VERSION ""

NS_ :

BS_:

BU_: ABS_BASE ATCM_DMSM GENERIC_GWMWakeup PBM IPMB TCU_TBS FDSM GSM TRCM GWM _delete ABS_ESC HUD IPMA CCM SASM PSCM SCCM HCM ATCM SUMA_RLM ATCM_FFSM PCU SECM VDM TBM OCS GENERIC TCCM TSTR RCM

BO_ 947 BodyInfo_3_HS2: 8 GWM
 SG_ ValetMode_D_Mem : 16|1@0+ (1,0) [0|1] "SED"  GENERIC
 SG_ DimmingLvlEvnt_No_Actl : 18|2@0+ (1,0) [0|3] "unitless"  GENERIC
 SG_ DrStatDrvErrCnt_B_Stat : 19|1@0+ (1,0) [0|1] "SED"  GENERIC
 SG_ Backlit_LED_Status : 23|4@0+ (1,0) [0|15] "SED"  ATCM_DMSM,ATCM_FFSM,ATCM,TBM,GSM
 SG_ TurnLghtRight_D_Rq : 63|2@0+ (1,0) [0|3] "SED"  IPMA,HCM,SCCM
 SG_ TurnLghtRightOn_B_Stat : 35|1@0+ (1,0) [0|1] "SED"  GENERIC
 SG_ TurnLghtLeftOn_B_Stat : 54|1@0+ (1,0) [0|1] "SED"  GENERIC
 SG_ FogLghtRearOn_B_Stat : 1|1@0+ (1,0) [0|1] "SED"  HCM,IPMA,GENERIC
 SG_ FogLghtFrontOn_B_Stat : 56|1@0+ (1,0) [0|1] "SED"  HCM,IPMA
 SG_ TurnLghtLeft_D_Rq : 9|2@0+ (1,0) [0|3] "SED"  IPMA,HCM,SCCM
 SG_ IgnKeyType_D_Actl : 39|4@0+ (1,0) [0|15] "SED"  ABS_BASE,ABS_ESC,CCM,IPMA
 SG_ Parklamp_Status : 3|2@0+ (1,0) [0|3] "SED"  HCM,ATCM_FFSM,ATCM_DMSM
 SG_ Litval : 47|8@0+ (1,0) [0|253] "SED"  IPMA,TBM,CCM,HCM,GSM
 SG_ Key_In_Ignition_Stat : 11|1@0+ (1,0) [0|1] "SED"  ABS_BASE,ABS_ESC,GSM,TRCM
 SG_ Ignition_Status : 7|4@0+ (1,0) [0|15] "SED"  ABS_BASE,PBM,HCM,ATCM_DMSM,TCU_TBS,ATCM,FDSM,OCS,TBM,TCCM,VDM,TRCM,SCCM,PSCM,GSM,RCM,HUD,ATCM_FFSM,IPMA,CCM,ABS_ESC
 SG_ Dimming_Lvl : 31|8@0+ (1,0) [0|253] "SED"  ATCM,ATCM_DMSM,ATCM_FFSM,GSM,TBM
 SG_ Day_Night_Status : 15|2@0+ (1,0) [0|3] "SED"  HUD,IPMA,ATCM_DMSM,TBM,CCM,ATCM_FFSM,RCM
 SG_ Remote_Start_Status : 13|2@0+ (1,0) [0|3] "SED"  TRCM,RCM,GENERIC,IPMB
 SG_ DrStatTgate_B_Actl : 0|1@0+ (1,0) [0|1] "SED"  SUMA_RLM,ABS_BASE,VDM,ABS_ESC,IPMB,TCU_TBS,OCS
 SG_ DrStatRr_B_Actl : 49|1@0+ (1,0) [0|1] "SED"  SUMA_RLM,ABS_BASE,VDM,IPMB,ABS_ESC,TCU_TBS,OCS
 SG_ DrStatRl_B_Actl : 48|1@0+ (1,0) [0|1] "SED"  SUMA_RLM,ABS_BASE,VDM,IPMB,ABS_ESC,TCU_TBS,OCS
 SG_ DrStatPsngr_B_Actl : 60|1@0+ (1,0) [0|1] "SED"  SUMA_RLM,ATCM_FFSM,ATCM_DMSM,ABS_BASE,VDM,IPMB,ABS_ESC,TCU_TBS,OCS
 SG_ DrStatInnrTgate_B_Actl : 58|1@0+ (1,0) [0|1] "SED"  VDM,ABS_BASE,ABS_ESC,IPMB,TCU_TBS,SCCM,OCS
 SG_ DrStatHood_B_Actl : 59|1@0+ (1,0) [0|1] "SED"  ABS_BASE,ABS_ESC,TCU_TBS,OCS
 SG_ DrStatDrv_B_Actl : 61|1@0+ (1,0) [0|1] "SED"  SUMA_RLM,ATCM_FFSM,ATCM_DMSM,ABS_BASE,IPMB,PBM,TCU_TBS,SASM,VDM,TCCM,GSM,IPMA,OCS,ABS_ESC,CCM
 SG_ PrkBrkActv_B_Actl : 55|1@0+ (1,0) [0|1] "SED"  ABS_BASE,IPMB,PSCM,TCCM,ABS_ESC
 SG_ LifeCycMde_D_Actl : 53|4@0+ (1,0) [0|15] "SED"  SUMA_RLM,ABS_BASE,SASM,SCCM,TCU_TBS,IPMA,HCM,FDSM,ABS_ESC,CCM,GSM,TRCM,VDM
 SG_ CrashEvnt_D_Stat : 34|2@0+ (1,0) [0|3] "SED"  GENERIC
 SG_ FuelPmpInhbt_B_Stat : 32|1@0+ (1,0) [0|1] "SED"  GENERIC
 SG_ BodySrvcRqd_B_Rq : 10|1@0+ (1,0) [0|1] "SED"  GENERIC
 SG_ Delay_Accy : 57|1@0+ (1,0) [0|1] "SED"  GENERIC

BO_ 131 Steering_Data: 8 SCCM
 SG_ HeadLghtHiCtrl_D_RqAhb : 43|3@0+ (1,0) [0|7] "SED"  GWM,HCM
 SG_ AhbStat_B_Dsply : 33|1@0+ (1,0) [0|1] "SED"  GWM
 SG_ WiprFrontSwtch_D_Stat : 47|4@0+ (1,0) [0|15] "SED"  GWM
 SG_ HeadLghtHiOn_B_StatAhb : 34|1@0+ (1,0) [0|1] "SED"  IPMA,GWM
 SG_ HeadLghtHiFlash_D_Actl : 36|2@0+ (1,0) [0|3] "SED"  GWM,HCM,IPMA
 SG_ TjaButtnOnOffPress : 40|1@0+ (1,0) [0|1] "SED"  IPMA,GWM
 SG_ AccButtnGapTogglePress : 32|1@0+ (1,0) [0|1] "SED"  IPMA,GWM
 SG_ HeadLghtHiFlash_D_Stat : 7|2@0+ (1,0) [0|3] "SED"  HCM,GWM,IPMA
 SG_ WiprFront_D_Stat : 3|4@0+ (1,0) [0|15] "SED"  HCM,CCM,IPMA,GWM,FDSM
 SG_ TurnLghtSwtch_D_Stat : 5|2@0+ (1,0) [0|3] "SED"  PSCM,SASM,HCM,CCM,IPMA,GWM
 SG_ LghtAmb_D_Sns : 15|3@0+ (1,0) [0|7] "SED"  IPMA,HCM,GWM
 SG_ AccButtnGapIncPress : 11|1@0+ (1,0) [0|1] "SED"  IPMA,CCM,GWM
 SG_ AccButtnGapDecPress : 12|1@0+ (1,0) [0|1] "SED"  IPMA,CCM,GWM
 SG_ AslButtnOnOffPress : 9|1@0+ (1,0) [0|1] "SED"  GWM
 SG_ AslButtnOnOffCnclPress : 10|1@0+ (1,0) [0|1] "SED"  CCM,GWM
 SG_ CcButtnOnPress : 37|1@0+ (1,0) [0|1] "SED"  IPMA,CCM,GWM
 SG_ CcButtnOnOffPress : 38|1@0+ (1,0) [0|1] "SED"  IPMA,CCM,GWM
 SG_ CcButtnOnOffCnclPress : 39|1@0+ (1,0) [0|1] "SED"  IPMA,CCM,GWM
 SG_ CcButtnOffPress : 24|1@0+ (1,0) [0|1] "SED"  IPMA,CCM,GWM
 SG_ CcAsllButtnResPress : 25|1@0+ (1,0) [0|1] "SED"  CCM,GWM
 SG_ CcAslButtnSetPress : 26|1@0+ (1,0) [0|1] "SED"  CCM,GWM
 SG_ CcAslButtnSetIncPress : 27|1@0+ (1,0) [0|1] "SED"  IPMA,CCM,GWM
 SG_ CcAslButtnSetDecPress : 28|1@0+ (1,0) [0|1] "SED"  IPMA,CCM,GWM
 SG_ CcAslButtnResIncPress : 29|1@0+ (1,0) [0|1] "SED"  IPMA,CCM,GWM
 SG_ CcAslButtnResDecPress : 30|1@0+ (1,0) [0|1] "SED"  CCM,GWM
 SG_ CcAslButtnOnPress : 31|1@0+ (1,0) [0|1] "SED"  IPMA,CCM,GWM
 SG_ CcAslButtnOnOffCncl : 16|1@0+ (1,0) [0|1] "SED"  CCM,GWM
 SG_ CcAslButtnOffCnclPress : 17|1@0+ (1,0) [0|1] "SED"  GWM,CCM
 SG_ CcAslButtnIndxIncPress : 18|1@0+ (1,0) [0|1] "SED"  CCM,GWM
 SG_ CcAslButtnIndxDecPress : 19|1@0+ (1,0) [0|1] "SED"  CCM,GWM
 SG_ CcAslButtnDeny_B_Actl : 20|1@0+ (1,0) [0|1] "SED"  IPMA,CCM,GWM
 SG_ CcAslButtnCnclResPress : 21|1@0+ (1,0) [0|1] "SED"  IPMA,CCM,GWM
 SG_ CcAslButtnCnclPress : 8|1@0+ (1,0) [0|1] "SED"  IPMA,CCM,GWM
 SG_ LaSwtchPos_D_Stat : 23|2@0+ (1,0) [0|3] "SED"  IPMA,GWM

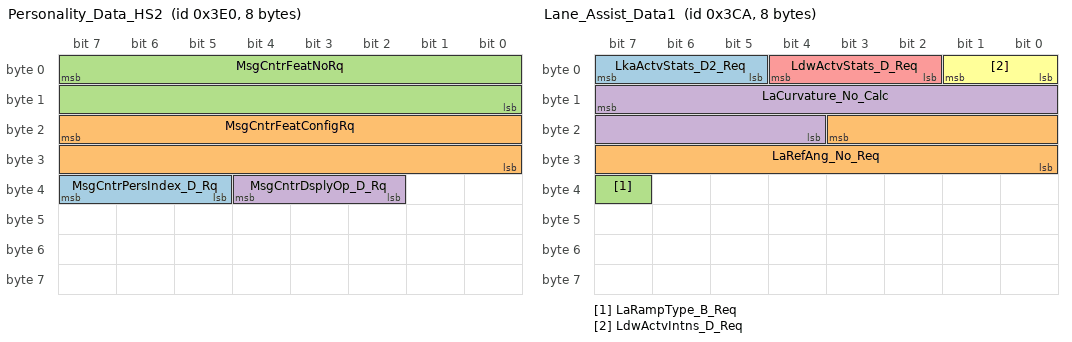
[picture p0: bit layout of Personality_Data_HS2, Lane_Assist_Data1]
BO_ 992 Personality_Data_HS2: 8 GWM
 SG_ MsgCntrPersIndex_D_Rq : 39|3@0+ (1,0) [0|7] "SED"  SASM,IPMB,HCM,CCM,VDM,SCCM,IPMA
 SG_ MsgCntrFeatConfigRq : 23|16@0+ (1,0) [0|65535] "unitless"  SASM,IPMB,HCM,CCM,VDM,SCCM,IPMA
 SG_ MsgCntrFeatNoRq : 7|16@0+ (1,0) [0|65535] "Number"  SASM,IPMB,HCM,CCM,VDM,SCCM,IPMA
 SG_ MsgCntrDsplyOp_D_Rq : 36|3@0+ (1,0) [0|7] "SED"  SASM,IPMB,HCM,SCCM,IPMA,CCM,VDM

BO_ 970 Lane_Assist_Data1: 8 IPMA
 SG_ LkaActvStats_D2_Req : 7|3@0+ (1,0) [0|7] "SED"  PSCM
 SG_ LaRefAng_No_Req : 19|12@0+ (0.05,-102.4) [-102.4|102.3] "mrad"  PSCM
 SG_ LaRampType_B_Req : 39|1@0+ (1,0) [0|1] "SED"  PSCM
 SG_ LaCurvature_No_Calc : 15|12@0+ (5E-006,-0.01024) [-0.01024|0.01023] "1/m"  PSCM
 SG_ LdwActvStats_D_Req : 4|3@0+ (1,0) [0|7] "SED"  SASM,SCCM,PSCM
 SG_ LdwActvIntns_D_Req : 1|2@0+ (1,0) [0|3] "SED"  SASM,SCCM,PSCM,GWM

BO_ 1806 TesterPhysicalResIPMA: 8 IPMA
 SG_ TesterPhysicalResIPMA : 7|64@0+ (1,0) [0|1.84467E+019] "unitless"  TSTR

BO_ 1798 TesterPhysicalReqIPMA: 8 TSTR
 SG_ TesterPhysicalReqIPMA : 7|64@0+ (1,0) [0|1.84467E+019] "unitless"  IPMA

BO_ 129 Steering_Wheel_Data2: 8 SCCM
 SG_ SteWhlSwtchView_B_Stat : 23|1@0+ (1,0) [0|1] "SED"  GWM
 SG_ SteWhlSwtchSet_B_Stat : 8|1@0+ (1,0) [0|1] "SED"  GWM
 SG_ SteWhlSwtchPhon_B_Stat : 9|1@0+ (1,0) [0|1] "SED"  GWM
 SG_ SteWhlSwtchNav_B_Stat : 10|1@0+ (1,0) [0|1] "SED"  GWM
 SG_ SteWhlSwtchMed_B_Stat : 11|1@0+ (1,0) [0|1] "SED"  GWM,HUD
 SG_ SteWhlSwtchIod_B_Stat : 12|1@0+ (1,0) [0|1] "SED"  GWM
 SG_ SteWhlSwtchHud_B_Stat : 13|1@0+ (1,0) [0|1] "SED"  GWM
 SG_ SteWhlSwtchBack_B_Stat : 14|1@0+ (1,0) [0|1] "SED"  GWM
 SG_ SteWhlSwtchMenu_B_Stat : 22|1@0+ (1,0) [0|1] "SED"  GWM
 SG_ SteEffortInc_B_RqDrv : 5|1@0+ (1,0) [0|1] "SED"  GWM
 SG_ SelDrvMdeInc_B_RqDrv : 6|1@0+ (1,0) [0|1] "SED"  GWM
 SG_ SelDrvMdeDec_B_RqDrv : 7|1@0+ (1,0) [0|1] "SED"  GWM
 SG_ SuspDampInc_B_RqDrv : 15|1@0+ (1,0) [0|1] "SED"  GWM
 SG_ SteWhlSwtchUp_B_Stat : 3|1@0+ (1,0) [0|1] "SED"  GWM
 SG_ SteWhlSwtchRght_B_Stat : 2|1@0+ (1,0) [0|1] "SED"  GWM
 SG_ SteWhlSwtchOk_B_Stat : 4|1@0+ (1,0) [0|1] "SED"  GWM
 SG_ SteWhlSwtchLeft_B_Stat : 1|1@0+ (1,0) [0|1] "SED"  GWM
 SG_ SteWhlSwtchDown_B_Stat : 0|1@0+ (1,0) [0|1] "SED"  GWM

BO_ 1833 TesterPhysicalResVDM: 8 VDM
 SG_ TesterPhysicalResVDM : 7|64@0+ (1,0) [0|1.84467E+019] "unitless"  TSTR

BO_ 1109 eCall_Info_HS2: 8 GWM
 SG_ eCallConfirmation : 7|3@0+ (1,0) [0|7] "SED"  RCM

BO_ 394 ACCDATA_3: 8 IPMA
 SG_ AccTrgDist2_D_Dsply : 27|4@0+ (1,0) [0|15] "SED"  GWM
 SG_ AccStopRes_B_Dsply : 54|1@0+ (1,0) [0|1] "SED"  GWM
 SG_ TjaWarn_D_Rq : 50|3@0+ (1,0) [0|7] "SED"  GWM
 SG_ Tja_D_Stat : 44|3@0+ (1,0) [0|7] "SED"  GWM
 SG_ TjaMsgTxt_D_Dsply : 53|3@0+ (1,0) [0|7] "SED"  GWM
 SG_ IaccLamp_D_Rq : 46|2@0+ (1,0) [0|3] "SED"  GWM
 SG_ AccMsgTxt_D2_Rq : 31|4@0+ (1,0) [0|15] "SED"  GWM
 SG_ FcwDeny_B_Dsply : 10|1@0+ (1,0) [0|1] "SED"  GWM
 SG_ FdaWarn_B_Rq : 21|1@0+ (1,0) [0|1] "SED"  GWM
 SG_ FcwMemStat_B_Actl : 13|1@0+ (1,0) [0|1] "SED"  GWM
 SG_ AccTGap_B_Dsply : 35|1@0+ (1,0) [0|1] "SED"  GWM
 SG_ CadsAlignIncplt_B_Actl : 11|1@0+ (1,0) [0|1] "SED"  GWM
 SG_ AccLowVMde_B_Dsply : 16|1@0+ (1,0) [0|1] "SED"  GWM
 SG_ AccFllwMde_B_Dsply : 17|1@0+ (1,0) [0|1] "SED"  GWM
 SG_ CadsRadrBlck_B_Actl : 22|1@0+ (1,0) [0|1] "SED"  GWM
 SG_ FdaStat_D_Dsply : 3|3@0+ (1,0) [0|7] "SED"  GWM
 SG_ FdaDeny_B_Dsply : 4|1@0+ (1,0) [0|1] "SED"  GWM
 SG_ CadsChime_B_Rq : 55|1@0+ (1,0) [0|1] "SED"  GWM
 SG_ CmbbPostEvnt_B_Dsply : 15|1@0+ (1,0) [0|1] "SED"  GWM
 SG_ FcwCmbbSrvcRqd_B_Rq : 12|1@0+ (1,0) [0|1] "SED"  GWM
 SG_ AccStopMde_B_Dsply : 0|1@0+ (1,0) [0|1] "SED"  GWM
 SG_ CadsCamraBlck_B_Actl : 23|1@0+ (1,0) [0|1] "SED"  GWM
 SG_ FcwMemSens_D_Actl : 20|2@0+ (1,0) [0|3] "SED"  GWM
 SG_ FcwMemDfaltOn_B_Actl : 18|1@0+ (1,0) [0|1] "SED"  GWM
 SG_ AccSrvcRqd_B_Rq : 14|1@0+ (1,0) [0|1] "SED"  GWM
 SG_ FcwMsgTxt_D_Rq : 7|3@0+ (1,0) [0|7] "SED"  GWM
 SG_ AccWarn_D_Dsply : 39|2@0+ (1,0) [0|3] "SED"  GWM
 SG_ FcwVisblWarn_B_Rq : 47|1@0+ (1,0) [0|1] "SED"  GWM
 SG_ FcwAudioWarn_B_Rq : 8|1@0+ (1,0) [0|1] "SED"  GWM
 SG_ FcwMemAudioOn_B_Actl : 9|1@0+ (1,0) [0|1] "SED"  GWM
 SG_ AccTGap_D_Dsply : 34|3@0+ (1,0) [0|7] "SED"  GWM
 SG_ AccMemEnbl_B_RqDrv : 36|1@0+ (1,0) [0|1] "SED"  GWM
 SG_ FdaMem_B_Stat : 37|1@0+ (1,0) [0|1] "SED"  GWM

BO_ 1046 BrakeSysFeatures_2: 8 ABS_ESC
 SG_ PrkBrkDynmc_D_Allw : 39|2@0+ (1,0) [0|3] "SED"  PBM,GWM
 SG_ BrkPrkBrkDynmc_B_Actl : 24|1@0+ (1,0) [0|1] "SED"  PBM,GWM
 SG_ ReserveTracCtlPtActv : 28|1@0+ (1,0) [0|1] "SED"  GWM,GENERIC
 SG_ HsaMde_D_Mem : 33|2@0+ (1,0) [0|3] "SED"  GWM
 SG_ BrkBstrVac_B_Rq : 27|1@0+ (1,0) [0|1] "Discrete"  GWM
 SG_ HdcMde_D_Actl : 31|3@0+ (1,0) [0|7] "SED"  GWM
 SG_ RearDiffLck_Tq2_RqMx : 51|12@0+ (4,0) [0|16376] "Nm"  GWM
 SG_ TRLR_SWAY_EVNT_IN_PROG : 25|1@0+ (1,0) [0|1] "SED"  GWM
 SG_ TRLR_SWAY_CONFIG_STAT : 26|1@0+ (1,0) [0|1] "SED"  GWM
 SG_ TCMode : 15|1@0+ (1,0) [0|1] "SED"  IPMA,PBM,PSCM,VDM,RCM,GWM,CCM
 SG_ DrvSlipCtlLamp_D_Rq : 42|2@0+ (1,0) [0|3] "SED"  IPMA,VDM,SASM,GWM,CCM,RCM
 SG_ Abs_B_Falt : 5|1@0+ (1,0) [0|1] "SED"  TBM,GWM
 SG_ DrvSlipCtlMde_D_Ind : 44|2@0+ (1,0) [0|3] "SED"  PSCM,IPMA,CCM,SASM,GWM,RCM
 SG_ BpedMove_No_Cs : 23|8@0+ (1,0) [0|255] "Unitless"  GWM
 SG_ DrvAntiLckLamp_D_Rq : 55|2@0+ (1,0) [0|3] "SED"  GWM,RCM
 SG_ BpedMove_No_Cnt : 3|4@0+ (1,0) [0|15] "Unitless"  GWM
 SG_ StabCtlBrk_B_Avail : 4|1@0+ (1,0) [0|1] "SED"  TCCM,GWM,VDM
 SG_ DrvHdcWarnInfo_D_Rq : 35|2@0+ (1,0) [0|3] "SED"  GWM
 SG_ DrvHdcMsg_D_Rq : 10|3@0+ (1,0) [0|7] "SED"  GWM
 SG_ DrvHdcLampInfo_D_Rq : 12|2@0+ (1,0) [0|3] "SED"  ATCM,GWM
 SG_ BpedMove_D_Actl : 7|2@0+ (1,0) [0|3] "SED"  CCM,GWM
 SG_ ChimeBrk_B_Rq : 14|1@0+ (1,0) [0|1] "SED"  GWM
 SG_ BrkLamp_B_Rq : 13|1@0+ (1,0) [0|1] "SED"  GWM,RCM
 SG_ HILL_DESC_MC : 47|3@0+ (1,0) [0|7] "SED"  GWM

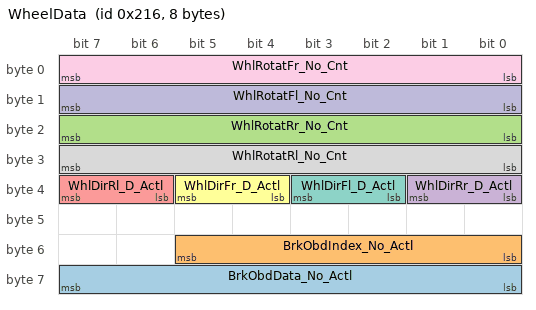
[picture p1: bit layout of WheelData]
BO_ 534 WheelData: 8 ABS_ESC
 SG_ BrkObdData_No_Actl : 63|8@0+ (1,0) [0|255] "unitless"  GWM
 SG_ BrkObdIndex_No_Actl : 53|6@0+ (1,0) [0|63] "unitless"  GWM
 SG_ WhlRotatRr_No_Cnt : 23|8@0+ (1,0) [0|255] "Unitless"  PBM,PSCM,TCU_TBS,GWM
 SG_ WhlDirRr_D_Actl : 33|2@0+ (1,0) [0|3] "SED"  IPMA,PSCM,TCU_TBS,FDSM,CCM,GWM
 SG_ WhlDirRl_D_Actl : 39|2@0+ (1,0) [0|3] "SED"  IPMA,PSCM,TCU_TBS,FDSM,CCM,GWM
 SG_ WhlDirFr_D_Actl : 37|2@0+ (1,0) [0|3] "SED"  PSCM,TCU_TBS,CCM,GWM
 SG_ WhlDirFl_D_Actl : 35|2@0+ (1,0) [0|3] "SED"  PBM,PSCM,TCU_TBS,CCM,GWM
 SG_ WhlRotatRl_No_Cnt : 31|8@0+ (1,0) [0|255] "Unitless"  PBM,PSCM,TCU_TBS,GWM
 SG_ WhlRotatFr_No_Cnt : 7|8@0+ (1,0) [0|255] "Unitless"  PSCM,TCU_TBS,GWM
 SG_ WhlRotatFl_No_Cnt : 15|8@0+ (1,0) [0|255] "Unitless"  PSCM,TCU_TBS,GWM

BO_TX_BU_ 131 : GENERIC_GWMWakeup,SCCM;
BO_TX_BU_ 129 : GENERIC_GWMWakeup,SASM,SCCM;
BO_TX_BU_ 394 : CCM,IPMA;
BO_TX_BU_ 1046 : ABS_BASE,ABS_ESC;
BO_TX_BU_ 534 : ABS_BASE,ABS_ESC;
CM_ SG_ 947 Dimming_Lvl "Refer to Vehicle Interior Illum Dimming Ctrl Sys Eng Spec, Table 2

";
CM_ SG_ 947 PrkBrkActv_B_Actl "Signal not transmitted on vehicles with electric park brake. ";
CM_ SG_ 1046 TCMode "Signal data set to 0x0 for ABS only vehicle option content";
CM_ SG_ 1046 DrvAntiLckLamp_D_Rq "update value table v8.34, not align w/GSDB, need etracker.  ABS & IPC implemented as updated.";
CM_ SG_ 1046 BpedMove_D_Actl "CCMGenSigTimeoutTime=1000";
CM_ SG_ 534 BrkObdData_No_Actl "Signal not transmitted on gas, diesel and HEV.  Only supported on PHEV.";
CM_ SG_ 534 BrkObdIndex_No_Actl "Signal not transmitted on gas, diesel and HEV.  Only supported on PHEV.";
CM_ SG_ 534 WhlRotatRr_No_Cnt "DCR 1833 to update Tx from GWM to EP100ms. Wheel Count signals are used by complex algorithm to determine Tire Pressure by Location & can't change from 20msec. (jweinfur)";
CM_ SG_ 534 WhlRotatRl_No_Cnt "DCR 1833 to update Tx from GWM to EP100ms. Wheel Count signals are used by complex algorithm to determine Tire Pressure by Location & can't change from 20msec. (jweinfur)";
CM_ SG_ 534 WhlRotatFr_No_Cnt "DCR 1833 to update Tx from GWM to EP100ms. Wheel Count signals are used by complex algorithm to determine Tire Pressure by Location & can't change from 20msec. (jweinfur)";
CM_ SG_ 534 WhlRotatFl_No_Cnt "DCR 1833 to update Tx from GWM to EP100ms. Wheel Count signals are used by complex algorithm to determine Tire Pressure by Location & can't change from 20msec. (jweinfur)";
BA_DEF_ SG_  "GenSigTimeoutTime_GWM" INT 0 100000;
BA_DEF_ BO_  "FrameGatewayNetwork" STRING ;
BA_DEF_ BO_  "FrameGatewayMS1" HEX 0 1407;
BA_DEF_ BO_  "FrameGatewayHS3" HEX 0 1407;
BA_DEF_ BO_  "FrameGatewayHS1" HEX 0 1407;
BA_DEF_ BO_  "NetworkInitialization" ENUM  "No","Yes";
BA_DEF_ BO_  "FrameGatewayId" HEX 0 1407;
BA_DEF_ BO_  "EventRateOfChange" INT 10 10000;
BA_DEF_ BO_  "GenMsgStartDelayTime" INT 0 10000;
BA_DEF_ BO_  "GenMsgNrOfRepetition" INT 0 100;
BA_DEF_ BO_  "GenMsgDelayTime" INT 0 1000;
BA_DEF_ BO_  "GenMsgCycleTime" INT 0 100000;
BA_DEF_ BO_  "GenMsgSendType" ENUM  "FixedPeriodic","Event","EnabledPeriodic","NotUsed","NotUsed","EventPeriodic","NotUsed","NotUsed","NoMsgSendType";
BA_DEF_ SG_  "U_U611_U625_MY20_Phev_Tx" ENUM  "No","Yes";
BA_DEF_ SG_  "U_CX482_CX483_MY20_Hev_Tx" ENUM  "No","Yes";
BA_DEF_ SG_  "U_CX482_CX483_MY20_Gas_Tx" ENUM  "No","Yes";
BA_DEF_ SG_  "U_CX482_CX483_MY20_Diesel_Tx" ENUM  "No","Yes";
BA_DEF_ SG_  "U_U611_U625_MY20_Hev_Tx" ENUM  "No","Yes";
BA_DEF_ SG_  "U_U611_U625_MY20_Gas_Tx" ENUM  "No","Yes";
BA_DEF_ SG_  "U_U611_U625_MY20_Diesel_Tx" ENUM  "No","Yes";
BA_DEF_ SG_  "U_LC1_B500_MY18_Gas_Tx" ENUM  "No","Yes";
BA_DEF_ SG_  "U_LC1_B500_MY18_Diesel_Tx" ENUM  "No","Yes";
BA_DEF_ SG_  "U_B500_MY18_Diesel_Tx" ENUM  "No","Yes";
BA_DEF_ SG_  "U_B500_MY18_Gas_Tx" ENUM  "No","Yes";
BA_DEF_ SG_  "U_C490_MY18_Tx" ENUM  "No","Yes";
BA_DEF_ SG_  "U_B562_MY18_Gas_Tx" ENUM  "No","Yes";
BA_DEF_ SG_  "U_C519_MY18_5_Gas_Tx" ENUM  "No","Yes";
BA_DEF_ SG_  "U_C519_MY18_5_Diesel_Tx" ENUM  "No","Yes";
BA_DEF_ SG_  "U_B515_MCA_MY17_Gas_Tx" ENUM  "No","Yes";
BA_DEF_ SG_  "U_B515_MCA_MY17_Diesel_Tx" ENUM  "No","Yes";
BA_DEF_ SG_  "U_B479_MY17_Diesel_Tx" ENUM  "No","Yes";
BA_DEF_ SG_  "U_B479_MY17_Gas_Tx" ENUM  "No","Yes";
BA_DEF_ SG_  "U_B562LC_MY15_Gas_Tx" ENUM  "No","Yes";
BA_DEF_ SG_  "U_B562LC_MY15_Diesel_Tx" ENUM  "No","Yes";
BA_DEF_ SG_  "U_U611_U625_MY20_Phev_Rx" ENUM  "No","Yes";
BA_DEF_ SG_  "U_CX482_CX483_MY20_Hev_Rx" ENUM  "No","Yes";
BA_DEF_ SG_  "U_CX482_CX483_MY20_Gas_Rx" ENUM  "No","Yes";
BA_DEF_ SG_  "U_CX482_CX483_MY20_Diesel_Rx" ENUM  "No","Yes";
BA_DEF_ SG_  "U_U611_U625_MY20_Hev_Rx" ENUM  "No","Yes";
BA_DEF_ SG_  "U_U611_U625_MY20_Gas_Rx" ENUM  "No","Yes";
BA_DEF_ SG_  "U_U611_U625_MY20_Diesel_Rx" ENUM  "No","Yes";
BA_DEF_ SG_  "U_B500_MY18_Diesel_Rx" ENUM  "No","Yes";
BA_DEF_ SG_  "U_B500_MY18_Gas_Rx" ENUM  "No","Yes";
BA_DEF_ SG_  "U_C490_MY18_Rx" ENUM  "No","Yes";
BA_DEF_ SG_  "U_B562_MY18_Gas_Rx" ENUM  "No","Yes";
BA_DEF_ SG_  "U_C519_MY18_5_Gas_Rx" ENUM  "No","Yes";
BA_DEF_ SG_  "U_C519_MY18_5_Diesel_Rx" ENUM  "No","Yes";
BA_DEF_ SG_  "U_B515_MCA_MY17_Gas_Rx" ENUM  "No","Yes";
BA_DEF_ SG_  "U_B515_MCA_MY17_Diesel_Rx" ENUM  "No","Yes";
BA_DEF_ SG_  "U_B479_MY17_Diesel_Rx" ENUM  "No","Yes";
BA_DEF_ SG_  "U_B479_MY17_Gas_Rx" ENUM  "No","Yes";
BA_DEF_ SG_  "U_B562LC_MY15_Gas_Rx" ENUM  "No","Yes";
BA_DEF_ SG_  "U_B562LC_MY15_Diesel_Rx" ENUM  "No","Yes";
BA_DEF_ SG_  "ContentDependant" ENUM  "No","Yes";
BA_DEF_ SG_  "GenSigStartValue" INT 0 1000000000;
BA_DEF_ SG_  "UsedOnPgmDBC" ENUM  "No","Yes";
BA_DEF_ SG_  "CrossOver_InfoCAN" ENUM  "No","Yes";
BA_DEF_ SG_  "WakeupSignal" ENUM  "No","Yes";
BA_DEF_ SG_  "GenSigMissingSourceValue" INT 0 1000000000;
BA_DEF_ SG_  "GenSigSendType" ENUM  "Cyclic","OnWrite","vector_leerstring","OnChange","vector_leerstring","IfActive","vector_leerstring","NoSigSendType";
BA_DEF_ BO_  "GenMsgRoutingTimeoutTime" INT 0 1000;
BA_DEF_ BO_  "MessageGateway" ENUM  "No","Yes";
BA_DEF_ BO_  "NmAsrMessage" ENUM  "No","Yes";
BA_DEF_ BO_  "TpApplType" STRING ;
BA_DEF_ BO_  "DiagState" ENUM  "No","Yes";
BA_DEF_ BO_  "DiagRequest" ENUM  "No","Yes";
BA_DEF_ BO_  "DiagResponse" ENUM  "No","Yes";
BA_DEF_ BO_  "GenMsgILSupport" ENUM  "No","Yes";
BA_DEF_DEF_  "GenSigTimeoutTime_GWM" 0;
BA_DEF_DEF_  "FrameGatewayNetwork" "NONE";
BA_DEF_DEF_  "FrameGatewayMS1" 0;
BA_DEF_DEF_  "FrameGatewayHS3" 0;
BA_DEF_DEF_  "FrameGatewayHS1" 0;
BA_DEF_DEF_  "NetworkInitialization" "Yes";
BA_DEF_DEF_  "FrameGatewayId" 0;
BA_DEF_DEF_  "EventRateOfChange" 10000;
BA_DEF_DEF_  "GenMsgStartDelayTime" 0;
BA_DEF_DEF_  "GenMsgNrOfRepetition" 1;
BA_DEF_DEF_  "GenMsgDelayTime" 20;
BA_DEF_DEF_  "GenMsgCycleTime" 0;
BA_DEF_DEF_  "GenMsgSendType" "NoMsgSendType";
BA_DEF_DEF_  "U_U611_U625_MY20_Phev_Tx" "No";
BA_DEF_DEF_  "U_CX482_CX483_MY20_Hev_Tx" "No";
BA_DEF_DEF_  "U_CX482_CX483_MY20_Gas_Tx" "No";
BA_DEF_DEF_  "U_CX482_CX483_MY20_Diesel_Tx" "No";
BA_DEF_DEF_  "U_U611_U625_MY20_Hev_Tx" "No";
BA_DEF_DEF_  "U_U611_U625_MY20_Gas_Tx" "No";
BA_DEF_DEF_  "U_U611_U625_MY20_Diesel_Tx" "No";
BA_DEF_DEF_  "U_LC1_B500_MY18_Gas_Tx" "No";
BA_DEF_DEF_  "U_LC1_B500_MY18_Diesel_Tx" "No";
BA_DEF_DEF_  "U_B500_MY18_Diesel_Tx" "No";
BA_DEF_DEF_  "U_B500_MY18_Gas_Tx" "No";
BA_DEF_DEF_  "U_C490_MY18_Tx" "No";
BA_DEF_DEF_  "U_B562_MY18_Gas_Tx" "No";
BA_DEF_DEF_  "U_C519_MY18_5_Gas_Tx" "No";
BA_DEF_DEF_  "U_C519_MY18_5_Diesel_Tx" "No";
BA_DEF_DEF_  "U_B515_MCA_MY17_Gas_Tx" "No";
BA_DEF_DEF_  "U_B515_MCA_MY17_Diesel_Tx" "No";
BA_DEF_DEF_  "U_B479_MY17_Diesel_Tx" "No";
BA_DEF_DEF_  "U_B479_MY17_Gas_Tx" "No";
BA_DEF_DEF_  "U_B562LC_MY15_Gas_Tx" "No";
BA_DEF_DEF_  "U_B562LC_MY15_Diesel_Tx" "No";
BA_DEF_DEF_  "U_U611_U625_MY20_Phev_Rx" "No";
BA_DEF_DEF_  "U_CX482_CX483_MY20_Hev_Rx" "No";
BA_DEF_DEF_  "U_CX482_CX483_MY20_Gas_Rx" "No";
BA_DEF_DEF_  "U_CX482_CX483_MY20_Diesel_Rx" "No";
BA_DEF_DEF_  "U_U611_U625_MY20_Hev_Rx" "No";
BA_DEF_DEF_  "U_U611_U625_MY20_Gas_Rx" "No";
BA_DEF_DEF_  "U_U611_U625_MY20_Diesel_Rx" "No";
BA_DEF_DEF_  "U_B500_MY18_Diesel_Rx" "No";
BA_DEF_DEF_  "U_B500_MY18_Gas_Rx" "No";
BA_DEF_DEF_  "U_C490_MY18_Rx" "No";
BA_DEF_DEF_  "U_B562_MY18_Gas_Rx" "No";
BA_DEF_DEF_  "U_C519_MY18_5_Gas_Rx" "No";
BA_DEF_DEF_  "U_C519_MY18_5_Diesel_Rx" "No";
BA_DEF_DEF_  "U_B515_MCA_MY17_Gas_Rx" "No";
BA_DEF_DEF_  "U_B515_MCA_MY17_Diesel_Rx" "No";
BA_DEF_DEF_  "U_B479_MY17_Diesel_Rx" "No";
BA_DEF_DEF_  "U_B479_MY17_Gas_Rx" "No";
BA_DEF_DEF_  "U_B562LC_MY15_Gas_Rx" "No";
BA_DEF_DEF_  "U_B562LC_MY15_Diesel_Rx" "No";
BA_DEF_DEF_  "ContentDependant" "No";
BA_DEF_DEF_  "GenSigStartValue" 0;
BA_DEF_DEF_  "UsedOnPgmDBC" "Yes";
BA_DEF_DEF_  "CrossOver_InfoCAN" "No";
BA_DEF_DEF_  "WakeupSignal" "No";
BA_DEF_DEF_  "GenSigMissingSourceValue" 0;
BA_DEF_DEF_  "GenSigSendType" "NoSigSendType";
BA_DEF_DEF_  "GenMsgRoutingTimeoutTime" 0;
BA_DEF_DEF_  "MessageGateway" "No";
BA_DEF_DEF_  "NmAsrMessage" "No";
BA_DEF_DEF_  "TpApplType" "";
BA_DEF_DEF_  "DiagState" "No";
BA_DEF_DEF_  "DiagRequest" "No";
BA_DEF_DEF_  "DiagResponse" "No";
BA_DEF_DEF_  "GenMsgILSupport" "Yes";
BA_ "FrameGatewayNetwork" BO_ 947 "HS1_CAN";
BA_ "FrameGatewayHS1" BO_ 947 947;
BA_ "FrameGatewayId" BO_ 947 947;
BA_ "GenMsgStartDelayTime" BO_ 947 100;
BA_ "GenMsgCycleTime" BO_ 131 100;
BA_ "GenMsgSendType" BO_ 131 5;
BA_ "MessageGateway" BO_ 131 1;
BA_ "FrameGatewayNetwork" BO_ 992 "HS3_CAN";
BA_ "FrameGatewayHS3" BO_ 992 992;
BA_ "FrameGatewayId" BO_ 992 992;
BA_ "GenMsgDelayTime" BO_ 970 10;
BA_ "GenMsgCycleTime" BO_ 970 30;
BA_ "GenMsgSendType" BO_ 970 0;
BA_ "NetworkInitialization" BO_ 1806 0;
BA_ "GenMsgDelayTime" BO_ 1806 0;
BA_ "GenMsgSendType" BO_ 1806 1;
BA_ "DiagResponse" BO_ 1806 1;
BA_ "GenMsgILSupport" BO_ 1806 0;
BA_ "NetworkInitialization" BO_ 1798 0;
BA_ "GenMsgDelayTime" BO_ 1798 0;
BA_ "GenMsgSendType" BO_ 1798 1;
BA_ "DiagRequest" BO_ 1798 1;
BA_ "GenMsgILSupport" BO_ 1798 0;
BA_ "GenMsgCycleTime" BO_ 129 1000;
BA_ "GenMsgSendType" BO_ 129 5;
BA_ "NetworkInitialization" BO_ 1833 0;
BA_ "GenMsgDelayTime" BO_ 1833 0;
BA_ "GenMsgSendType" BO_ 1833 1;
BA_ "DiagResponse" BO_ 1833 1;
BA_ "GenMsgILSupport" BO_ 1833 0;
BA_ "FrameGatewayNetwork" BO_ 1109 "HS1_CAN";
BA_ "FrameGatewayHS1" BO_ 1109 1109;
BA_ "FrameGatewayId" BO_ 1109 1109;
BA_ "GenMsgCycleTime" BO_ 394 200;
BA_ "GenMsgSendType" BO_ 394 5;
BA_ "GenMsgCycleTime" BO_ 1046 100;
BA_ "GenMsgSendType" BO_ 1046 0;
BA_ "GenMsgDelayTime" BO_ 534 10;
BA_ "GenMsgCycleTime" BO_ 534 20;
BA_ "GenMsgSendType" BO_ 534 0;
BA_ "WakeupSignal" SG_ 947 DimmingLvlEvnt_No_Actl 1;
BA_ "U_U611_U625_MY20_Phev_Rx" SG_ 947 Backlit_LED_Status 1;
BA_ "U_CX482_CX483_MY20_Hev_Rx" SG_ 947 Backlit_LED_Status 1;
BA_ "U_CX482_CX483_MY20_Gas_Rx" SG_ 947 Backlit_LED_Status 1;
BA_ "U_CX482_CX483_MY20_Diesel_Rx" SG_ 947 Backlit_LED_Status 1;
BA_ "U_U611_U625_MY20_Hev_Rx" SG_ 947 Backlit_LED_Status 1;
BA_ "U_U611_U625_MY20_Gas_Rx" SG_ 947 Backlit_LED_Status 1;
BA_ "U_U611_U625_MY20_Diesel_Rx" SG_ 947 Backlit_LED_Status 1;
BA_ "U_C519_MY18_5_Gas_Rx" SG_ 947 Backlit_LED_Status 1;
BA_ "U_C519_MY18_5_Diesel_Rx" SG_ 947 Backlit_LED_Status 1;
BA_ "CrossOver_InfoCAN" SG_ 947 Backlit_LED_Status 1;
BA_ "WakeupSignal" SG_ 947 Backlit_LED_Status 1;
BA_ "U_U611_U625_MY20_Phev_Rx" SG_ 947 TurnLghtRight_D_Rq 1;
BA_ "U_CX482_CX483_MY20_Hev_Rx" SG_ 947 TurnLghtRight_D_Rq 1;
BA_ "U_CX482_CX483_MY20_Gas_Rx" SG_ 947 TurnLghtRight_D_Rq 1;
BA_ "U_CX482_CX483_MY20_Diesel_Rx" SG_ 947 TurnLghtRight_D_Rq 1;
BA_ "U_U611_U625_MY20_Hev_Rx" SG_ 947 TurnLghtRight_D_Rq 1;
BA_ "U_U611_U625_MY20_Gas_Rx" SG_ 947 TurnLghtRight_D_Rq 1;
BA_ "U_U611_U625_MY20_Diesel_Rx" SG_ 947 TurnLghtRight_D_Rq 1;
BA_ "U_B500_MY18_Diesel_Rx" SG_ 947 TurnLghtRight_D_Rq 1;
BA_ "U_B500_MY18_Gas_Rx" SG_ 947 TurnLghtRight_D_Rq 1;
BA_ "U_C519_MY18_5_Gas_Rx" SG_ 947 TurnLghtRight_D_Rq 1;
BA_ "U_C519_MY18_5_Diesel_Rx" SG_ 947 TurnLghtRight_D_Rq 1;
BA_ "U_B515_MCA_MY17_Gas_Rx" SG_ 947 TurnLghtRight_D_Rq 1;
BA_ "U_B515_MCA_MY17_Diesel_Rx" SG_ 947 TurnLghtRight_D_Rq 1;
BA_ "U_B479_MY17_Diesel_Rx" SG_ 947 TurnLghtRight_D_Rq 1;
BA_ "U_B479_MY17_Gas_Rx" SG_ 947 TurnLghtRight_D_Rq 1;
BA_ "CrossOver_InfoCAN" SG_ 947 TurnLghtRight_D_Rq 1;
BA_ "WakeupSignal" SG_ 947 TurnLghtRight_D_Rq 1;
BA_ "CrossOver_InfoCAN" SG_ 947 TurnLghtRightOn_B_Stat 1;
BA_ "CrossOver_InfoCAN" SG_ 947 TurnLghtLeftOn_B_Stat 1;
BA_ "U_CX482_CX483_MY20_Hev_Rx" SG_ 947 FogLghtRearOn_B_Stat 1;
BA_ "U_CX482_CX483_MY20_Gas_Rx" SG_ 947 FogLghtRearOn_B_Stat 1;
BA_ "U_CX482_CX483_MY20_Diesel_Rx" SG_ 947 FogLghtRearOn_B_Stat 1;
BA_ "U_U611_U625_MY20_Hev_Rx" SG_ 947 FogLghtRearOn_B_Stat 1;
BA_ "U_U611_U625_MY20_Gas_Rx" SG_ 947 FogLghtRearOn_B_Stat 1;
BA_ "U_U611_U625_MY20_Diesel_Rx" SG_ 947 FogLghtRearOn_B_Stat 1;
BA_ "U_C519_MY18_5_Gas_Rx" SG_ 947 FogLghtRearOn_B_Stat 1;
BA_ "U_C519_MY18_5_Diesel_Rx" SG_ 947 FogLghtRearOn_B_Stat 1;
BA_ "U_B479_MY17_Diesel_Rx" SG_ 947 FogLghtRearOn_B_Stat 1;
BA_ "U_B479_MY17_Gas_Rx" SG_ 947 FogLghtRearOn_B_Stat 1;
BA_ "CrossOver_InfoCAN" SG_ 947 FogLghtRearOn_B_Stat 1;
BA_ "U_CX482_CX483_MY20_Hev_Rx" SG_ 947 FogLghtFrontOn_B_Stat 1;
BA_ "U_CX482_CX483_MY20_Gas_Rx" SG_ 947 FogLghtFrontOn_B_Stat 1;
BA_ "U_CX482_CX483_MY20_Diesel_Rx" SG_ 947 FogLghtFrontOn_B_Stat 1;
BA_ "U_C519_MY18_5_Gas_Rx" SG_ 947 FogLghtFrontOn_B_Stat 1;
BA_ "U_C519_MY18_5_Diesel_Rx" SG_ 947 FogLghtFrontOn_B_Stat 1;
BA_ "CrossOver_InfoCAN" SG_ 947 FogLghtFrontOn_B_Stat 1;
BA_ "U_U611_U625_MY20_Phev_Rx" SG_ 947 TurnLghtLeft_D_Rq 1;
BA_ "U_CX482_CX483_MY20_Hev_Rx" SG_ 947 TurnLghtLeft_D_Rq 1;
BA_ "U_CX482_CX483_MY20_Gas_Rx" SG_ 947 TurnLghtLeft_D_Rq 1;
BA_ "U_CX482_CX483_MY20_Diesel_Rx" SG_ 947 TurnLghtLeft_D_Rq 1;
BA_ "U_U611_U625_MY20_Hev_Rx" SG_ 947 TurnLghtLeft_D_Rq 1;
BA_ "U_U611_U625_MY20_Gas_Rx" SG_ 947 TurnLghtLeft_D_Rq 1;
BA_ "U_U611_U625_MY20_Diesel_Rx" SG_ 947 TurnLghtLeft_D_Rq 1;
BA_ "U_B500_MY18_Diesel_Rx" SG_ 947 TurnLghtLeft_D_Rq 1;
BA_ "U_B500_MY18_Gas_Rx" SG_ 947 TurnLghtLeft_D_Rq 1;
BA_ "U_C519_MY18_5_Gas_Rx" SG_ 947 TurnLghtLeft_D_Rq 1;
BA_ "U_C519_MY18_5_Diesel_Rx" SG_ 947 TurnLghtLeft_D_Rq 1;
BA_ "U_B515_MCA_MY17_Gas_Rx" SG_ 947 TurnLghtLeft_D_Rq 1;
BA_ "U_B515_MCA_MY17_Diesel_Rx" SG_ 947 TurnLghtLeft_D_Rq 1;
BA_ "U_B479_MY17_Diesel_Rx" SG_ 947 TurnLghtLeft_D_Rq 1;
BA_ "U_B479_MY17_Gas_Rx" SG_ 947 TurnLghtLeft_D_Rq 1;
BA_ "CrossOver_InfoCAN" SG_ 947 TurnLghtLeft_D_Rq 1;
BA_ "WakeupSignal" SG_ 947 TurnLghtLeft_D_Rq 1;
BA_ "U_B500_MY18_Diesel_Rx" SG_ 947 IgnKeyType_D_Actl 1;
BA_ "U_B500_MY18_Gas_Rx" SG_ 947 IgnKeyType_D_Actl 1;
BA_ "U_B562_MY18_Gas_Rx" SG_ 947 IgnKeyType_D_Actl 1;
BA_ "U_B515_MCA_MY17_Gas_Rx" SG_ 947 IgnKeyType_D_Actl 1;
BA_ "U_B515_MCA_MY17_Diesel_Rx" SG_ 947 IgnKeyType_D_Actl 1;
BA_ "U_CX482_CX483_MY20_Hev_Rx" SG_ 947 IgnKeyType_D_Actl 1;
BA_ "U_CX482_CX483_MY20_Gas_Rx" SG_ 947 IgnKeyType_D_Actl 1;
BA_ "U_CX482_CX483_MY20_Diesel_Rx" SG_ 947 IgnKeyType_D_Actl 1;
BA_ "U_U611_U625_MY20_Hev_Rx" SG_ 947 IgnKeyType_D_Actl 1;
BA_ "U_U611_U625_MY20_Gas_Rx" SG_ 947 IgnKeyType_D_Actl 1;
BA_ "U_U611_U625_MY20_Diesel_Rx" SG_ 947 IgnKeyType_D_Actl 1;
BA_ "U_C519_MY18_5_Gas_Rx" SG_ 947 IgnKeyType_D_Actl 1;
BA_ "U_C519_MY18_5_Diesel_Rx" SG_ 947 IgnKeyType_D_Actl 1;
BA_ "GenSigStartValue" SG_ 947 IgnKeyType_D_Actl 14;
BA_ "CrossOver_InfoCAN" SG_ 947 IgnKeyType_D_Actl 1;
BA_ "U_U611_U625_MY20_Hev_Rx" SG_ 947 Parklamp_Status 1;
BA_ "U_U611_U625_MY20_Gas_Rx" SG_ 947 Parklamp_Status 1;
BA_ "U_U611_U625_MY20_Diesel_Rx" SG_ 947 Parklamp_Status 1;
BA_ "GenSigStartValue" SG_ 947 Parklamp_Status 1;
BA_ "CrossOver_InfoCAN" SG_ 947 Parklamp_Status 1;
BA_ "WakeupSignal" SG_ 947 Parklamp_Status 1;
BA_ "U_U611_U625_MY20_Phev_Rx" SG_ 947 Litval 1;
BA_ "U_CX482_CX483_MY20_Hev_Rx" SG_ 947 Litval 1;
BA_ "U_CX482_CX483_MY20_Gas_Rx" SG_ 947 Litval 1;
BA_ "U_CX482_CX483_MY20_Diesel_Rx" SG_ 947 Litval 1;
BA_ "U_U611_U625_MY20_Hev_Rx" SG_ 947 Litval 1;
BA_ "U_U611_U625_MY20_Gas_Rx" SG_ 947 Litval 1;
BA_ "U_U611_U625_MY20_Diesel_Rx" SG_ 947 Litval 1;
BA_ "U_C519_MY18_5_Gas_Rx" SG_ 947 Litval 1;
BA_ "U_C519_MY18_5_Diesel_Rx" SG_ 947 Litval 1;
BA_ "U_B479_MY17_Diesel_Rx" SG_ 947 Litval 1;
BA_ "U_B479_MY17_Gas_Rx" SG_ 947 Litval 1;
BA_ "CrossOver_InfoCAN" SG_ 947 Litval 1;
BA_ "WakeupSignal" SG_ 947 Litval 1;
BA_ "U_B500_MY18_Diesel_Rx" SG_ 947 Key_In_Ignition_Stat 1;
BA_ "U_B500_MY18_Gas_Rx" SG_ 947 Key_In_Ignition_Stat 1;
BA_ "U_B515_MCA_MY17_Gas_Rx" SG_ 947 Key_In_Ignition_Stat 1;
BA_ "U_B515_MCA_MY17_Diesel_Rx" SG_ 947 Key_In_Ignition_Stat 1;
BA_ "U_B479_MY17_Diesel_Rx" SG_ 947 Key_In_Ignition_Stat 1;
BA_ "U_B479_MY17_Gas_Rx" SG_ 947 Key_In_Ignition_Stat 1;
BA_ "U_U611_U625_MY20_Phev_Rx" SG_ 947 Key_In_Ignition_Stat 1;
BA_ "U_CX482_CX483_MY20_Hev_Rx" SG_ 947 Key_In_Ignition_Stat 1;
BA_ "U_CX482_CX483_MY20_Gas_Rx" SG_ 947 Key_In_Ignition_Stat 1;
BA_ "U_CX482_CX483_MY20_Diesel_Rx" SG_ 947 Key_In_Ignition_Stat 1;
BA_ "U_U611_U625_MY20_Hev_Rx" SG_ 947 Key_In_Ignition_Stat 1;
BA_ "U_U611_U625_MY20_Gas_Rx" SG_ 947 Key_In_Ignition_Stat 1;
BA_ "U_U611_U625_MY20_Diesel_Rx" SG_ 947 Key_In_Ignition_Stat 1;
BA_ "U_C519_MY18_5_Gas_Rx" SG_ 947 Key_In_Ignition_Stat 1;
BA_ "U_C519_MY18_5_Diesel_Rx" SG_ 947 Key_In_Ignition_Stat 1;
BA_ "CrossOver_InfoCAN" SG_ 947 Key_In_Ignition_Stat 1;
BA_ "WakeupSignal" SG_ 947 Key_In_Ignition_Stat 1;
BA_ "U_U611_U625_MY20_Phev_Rx" SG_ 947 Ignition_Status 1;
BA_ "U_CX482_CX483_MY20_Hev_Rx" SG_ 947 Ignition_Status 1;
BA_ "U_CX482_CX483_MY20_Gas_Rx" SG_ 947 Ignition_Status 1;
BA_ "U_CX482_CX483_MY20_Diesel_Rx" SG_ 947 Ignition_Status 1;
BA_ "U_U611_U625_MY20_Hev_Rx" SG_ 947 Ignition_Status 1;
BA_ "U_U611_U625_MY20_Gas_Rx" SG_ 947 Ignition_Status 1;
BA_ "U_U611_U625_MY20_Diesel_Rx" SG_ 947 Ignition_Status 1;
BA_ "U_B500_MY18_Diesel_Rx" SG_ 947 Ignition_Status 1;
BA_ "U_B500_MY18_Gas_Rx" SG_ 947 Ignition_Status 1;
BA_ "U_C490_MY18_Rx" SG_ 947 Ignition_Status 1;
BA_ "U_B562_MY18_Gas_Rx" SG_ 947 Ignition_Status 1;
BA_ "U_B515_MCA_MY17_Gas_Rx" SG_ 947 Ignition_Status 1;
BA_ "U_C519_MY18_5_Gas_Rx" SG_ 947 Ignition_Status 1;
BA_ "U_C519_MY18_5_Diesel_Rx" SG_ 947 Ignition_Status 1;
BA_ "U_B479_MY17_Diesel_Rx" SG_ 947 Ignition_Status 1;
BA_ "U_B479_MY17_Gas_Rx" SG_ 947 Ignition_Status 1;
BA_ "CrossOver_InfoCAN" SG_ 947 Ignition_Status 1;
BA_ "WakeupSignal" SG_ 947 Ignition_Status 1;
BA_ "U_U611_U625_MY20_Phev_Rx" SG_ 947 Dimming_Lvl 1;
BA_ "U_CX482_CX483_MY20_Hev_Rx" SG_ 947 Dimming_Lvl 1;
BA_ "U_CX482_CX483_MY20_Gas_Rx" SG_ 947 Dimming_Lvl 1;
BA_ "U_CX482_CX483_MY20_Diesel_Rx" SG_ 947 Dimming_Lvl 1;
BA_ "U_U611_U625_MY20_Hev_Rx" SG_ 947 Dimming_Lvl 1;
BA_ "U_U611_U625_MY20_Gas_Rx" SG_ 947 Dimming_Lvl 1;
BA_ "U_U611_U625_MY20_Diesel_Rx" SG_ 947 Dimming_Lvl 1;
BA_ "U_C519_MY18_5_Gas_Rx" SG_ 947 Dimming_Lvl 1;
BA_ "U_C519_MY18_5_Diesel_Rx" SG_ 947 Dimming_Lvl 1;
BA_ "GenSigStartValue" SG_ 947 Dimming_Lvl 12;
BA_ "CrossOver_InfoCAN" SG_ 947 Dimming_Lvl 1;
BA_ "WakeupSignal" SG_ 947 Dimming_Lvl 1;
BA_ "U_U611_U625_MY20_Hev_Rx" SG_ 947 Day_Night_Status 1;
BA_ "U_U611_U625_MY20_Gas_Rx" SG_ 947 Day_Night_Status 1;
BA_ "U_U611_U625_MY20_Diesel_Rx" SG_ 947 Day_Night_Status 1;
BA_ "U_CX482_CX483_MY20_Hev_Rx" SG_ 947 Day_Night_Status 1;
BA_ "U_CX482_CX483_MY20_Gas_Rx" SG_ 947 Day_Night_Status 1;
BA_ "U_CX482_CX483_MY20_Diesel_Rx" SG_ 947 Day_Night_Status 1;
BA_ "U_C519_MY18_5_Gas_Rx" SG_ 947 Day_Night_Status 1;
BA_ "U_C519_MY18_5_Diesel_Rx" SG_ 947 Day_Night_Status 1;
BA_ "U_B515_MCA_MY17_Gas_Rx" SG_ 947 Day_Night_Status 1;
BA_ "U_B515_MCA_MY17_Diesel_Rx" SG_ 947 Day_Night_Status 1;
BA_ "U_B479_MY17_Diesel_Rx" SG_ 947 Day_Night_Status 1;
BA_ "U_B479_MY17_Gas_Rx" SG_ 947 Day_Night_Status 1;
BA_ "CrossOver_InfoCAN" SG_ 947 Day_Night_Status 1;
BA_ "WakeupSignal" SG_ 947 Day_Night_Status 1;
BA_ "U_U611_U625_MY20_Hev_Rx" SG_ 947 Remote_Start_Status 1;
BA_ "U_U611_U625_MY20_Gas_Rx" SG_ 947 Remote_Start_Status 1;
BA_ "U_U611_U625_MY20_Diesel_Rx" SG_ 947 Remote_Start_Status 1;
BA_ "U_B562_MY18_Gas_Rx" SG_ 947 Remote_Start_Status 1;
BA_ "U_B479_MY17_Diesel_Rx" SG_ 947 Remote_Start_Status 1;
BA_ "U_B479_MY17_Gas_Rx" SG_ 947 Remote_Start_Status 1;
BA_ "CrossOver_InfoCAN" SG_ 947 Remote_Start_Status 1;
BA_ "WakeupSignal" SG_ 947 Remote_Start_Status 1;
BA_ "U_B479_MY17_Diesel_Rx" SG_ 947 DrStatTgate_B_Actl 1;
BA_ "U_B479_MY17_Gas_Rx" SG_ 947 DrStatTgate_B_Actl 1;
BA_ "U_B515_MCA_MY17_Gas_Rx" SG_ 947 DrStatTgate_B_Actl 1;
BA_ "U_B515_MCA_MY17_Diesel_Rx" SG_ 947 DrStatTgate_B_Actl 1;
BA_ "CrossOver_InfoCAN" SG_ 947 DrStatTgate_B_Actl 1;
BA_ "WakeupSignal" SG_ 947 DrStatTgate_B_Actl 1;
BA_ "U_B479_MY17_Diesel_Rx" SG_ 947 DrStatRr_B_Actl 1;
BA_ "U_B479_MY17_Gas_Rx" SG_ 947 DrStatRr_B_Actl 1;
BA_ "U_B515_MCA_MY17_Gas_Rx" SG_ 947 DrStatRr_B_Actl 1;
BA_ "U_B515_MCA_MY17_Diesel_Rx" SG_ 947 DrStatRr_B_Actl 1;
BA_ "CrossOver_InfoCAN" SG_ 947 DrStatRr_B_Actl 1;
BA_ "WakeupSignal" SG_ 947 DrStatRr_B_Actl 1;
BA_ "U_B479_MY17_Diesel_Rx" SG_ 947 DrStatRl_B_Actl 1;
BA_ "U_B479_MY17_Gas_Rx" SG_ 947 DrStatRl_B_Actl 1;
BA_ "U_B515_MCA_MY17_Gas_Rx" SG_ 947 DrStatRl_B_Actl 1;
BA_ "U_B515_MCA_MY17_Diesel_Rx" SG_ 947 DrStatRl_B_Actl 1;
BA_ "CrossOver_InfoCAN" SG_ 947 DrStatRl_B_Actl 1;
BA_ "WakeupSignal" SG_ 947 DrStatRl_B_Actl 1;
BA_ "U_U611_U625_MY20_Hev_Rx" SG_ 947 DrStatPsngr_B_Actl 1;
BA_ "U_U611_U625_MY20_Gas_Rx" SG_ 947 DrStatPsngr_B_Actl 1;
BA_ "U_U611_U625_MY20_Diesel_Rx" SG_ 947 DrStatPsngr_B_Actl 1;
BA_ "U_B515_MCA_MY17_Gas_Rx" SG_ 947 DrStatPsngr_B_Actl 1;
BA_ "U_B515_MCA_MY17_Diesel_Rx" SG_ 947 DrStatPsngr_B_Actl 1;
BA_ "U_B479_MY17_Diesel_Rx" SG_ 947 DrStatPsngr_B_Actl 1;
BA_ "U_B479_MY17_Gas_Rx" SG_ 947 DrStatPsngr_B_Actl 1;
BA_ "CrossOver_InfoCAN" SG_ 947 DrStatPsngr_B_Actl 1;
BA_ "WakeupSignal" SG_ 947 DrStatPsngr_B_Actl 1;
BA_ "U_U611_U625_MY20_Phev_Rx" SG_ 947 DrStatInnrTgate_B_Actl 1;
BA_ "U_CX482_CX483_MY20_Hev_Rx" SG_ 947 DrStatInnrTgate_B_Actl 1;
BA_ "U_CX482_CX483_MY20_Gas_Rx" SG_ 947 DrStatInnrTgate_B_Actl 1;
BA_ "U_CX482_CX483_MY20_Diesel_Rx" SG_ 947 DrStatInnrTgate_B_Actl 1;
BA_ "U_U611_U625_MY20_Hev_Rx" SG_ 947 DrStatInnrTgate_B_Actl 1;
BA_ "U_U611_U625_MY20_Gas_Rx" SG_ 947 DrStatInnrTgate_B_Actl 1;
BA_ "U_U611_U625_MY20_Diesel_Rx" SG_ 947 DrStatInnrTgate_B_Actl 1;
BA_ "U_B515_MCA_MY17_Gas_Rx" SG_ 947 DrStatInnrTgate_B_Actl 1;
BA_ "U_B515_MCA_MY17_Diesel_Rx" SG_ 947 DrStatInnrTgate_B_Actl 1;
BA_ "U_B479_MY17_Diesel_Rx" SG_ 947 DrStatInnrTgate_B_Actl 1;
BA_ "U_B479_MY17_Gas_Rx" SG_ 947 DrStatInnrTgate_B_Actl 1;
BA_ "CrossOver_InfoCAN" SG_ 947 DrStatInnrTgate_B_Actl 1;
BA_ "WakeupSignal" SG_ 947 DrStatInnrTgate_B_Actl 1;
BA_ "U_B479_MY17_Diesel_Rx" SG_ 947 DrStatHood_B_Actl 1;
BA_ "U_B479_MY17_Gas_Rx" SG_ 947 DrStatHood_B_Actl 1;
BA_ "U_B515_MCA_MY17_Gas_Rx" SG_ 947 DrStatHood_B_Actl 1;
BA_ "U_B515_MCA_MY17_Diesel_Rx" SG_ 947 DrStatHood_B_Actl 1;
BA_ "CrossOver_InfoCAN" SG_ 947 DrStatHood_B_Actl 1;
BA_ "WakeupSignal" SG_ 947 DrStatHood_B_Actl 1;
BA_ "U_U611_U625_MY20_Phev_Rx" SG_ 947 DrStatDrv_B_Actl 1;
BA_ "U_CX482_CX483_MY20_Hev_Rx" SG_ 947 DrStatDrv_B_Actl 1;
BA_ "U_CX482_CX483_MY20_Gas_Rx" SG_ 947 DrStatDrv_B_Actl 1;
BA_ "U_CX482_CX483_MY20_Diesel_Rx" SG_ 947 DrStatDrv_B_Actl 1;
BA_ "U_U611_U625_MY20_Hev_Rx" SG_ 947 DrStatDrv_B_Actl 1;
BA_ "U_U611_U625_MY20_Gas_Rx" SG_ 947 DrStatDrv_B_Actl 1;
BA_ "U_U611_U625_MY20_Diesel_Rx" SG_ 947 DrStatDrv_B_Actl 1;
BA_ "U_C519_MY18_5_Gas_Rx" SG_ 947 DrStatDrv_B_Actl 1;
BA_ "U_C519_MY18_5_Diesel_Rx" SG_ 947 DrStatDrv_B_Actl 1;
BA_ "U_B479_MY17_Diesel_Rx" SG_ 947 DrStatDrv_B_Actl 1;
BA_ "U_B479_MY17_Gas_Rx" SG_ 947 DrStatDrv_B_Actl 1;
BA_ "CrossOver_InfoCAN" SG_ 947 DrStatDrv_B_Actl 1;
BA_ "WakeupSignal" SG_ 947 DrStatDrv_B_Actl 1;
BA_ "U_B500_MY18_Diesel_Rx" SG_ 947 PrkBrkActv_B_Actl 1;
BA_ "U_B500_MY18_Gas_Rx" SG_ 947 PrkBrkActv_B_Actl 1;
BA_ "U_CX482_CX483_MY20_Hev_Rx" SG_ 947 PrkBrkActv_B_Actl 1;
BA_ "U_CX482_CX483_MY20_Gas_Rx" SG_ 947 PrkBrkActv_B_Actl 1;
BA_ "U_CX482_CX483_MY20_Diesel_Rx" SG_ 947 PrkBrkActv_B_Actl 1;
BA_ "U_U611_U625_MY20_Hev_Rx" SG_ 947 PrkBrkActv_B_Actl 1;
BA_ "U_U611_U625_MY20_Gas_Rx" SG_ 947 PrkBrkActv_B_Actl 1;
BA_ "U_U611_U625_MY20_Diesel_Rx" SG_ 947 PrkBrkActv_B_Actl 1;
BA_ "U_C519_MY18_5_Gas_Rx" SG_ 947 PrkBrkActv_B_Actl 1;
BA_ "U_C519_MY18_5_Diesel_Rx" SG_ 947 PrkBrkActv_B_Actl 1;
BA_ "U_B515_MCA_MY17_Gas_Rx" SG_ 947 PrkBrkActv_B_Actl 1;
BA_ "U_B515_MCA_MY17_Diesel_Rx" SG_ 947 PrkBrkActv_B_Actl 1;
BA_ "U_B479_MY17_Diesel_Rx" SG_ 947 PrkBrkActv_B_Actl 1;
BA_ "U_B479_MY17_Gas_Rx" SG_ 947 PrkBrkActv_B_Actl 1;
BA_ "ContentDependant" SG_ 947 PrkBrkActv_B_Actl 1;
BA_ "CrossOver_InfoCAN" SG_ 947 PrkBrkActv_B_Actl 1;
BA_ "WakeupSignal" SG_ 947 PrkBrkActv_B_Actl 1;
BA_ "U_B500_MY18_Diesel_Rx" SG_ 947 LifeCycMde_D_Actl 1;
BA_ "U_B500_MY18_Gas_Rx" SG_ 947 LifeCycMde_D_Actl 1;
BA_ "U_B479_MY17_Diesel_Rx" SG_ 947 LifeCycMde_D_Actl 1;
BA_ "U_B479_MY17_Gas_Rx" SG_ 947 LifeCycMde_D_Actl 1;
BA_ "U_CX482_CX483_MY20_Hev_Rx" SG_ 947 LifeCycMde_D_Actl 1;
BA_ "U_CX482_CX483_MY20_Gas_Rx" SG_ 947 LifeCycMde_D_Actl 1;
BA_ "U_CX482_CX483_MY20_Diesel_Rx" SG_ 947 LifeCycMde_D_Actl 1;
BA_ "U_U611_U625_MY20_Phev_Rx" SG_ 947 LifeCycMde_D_Actl 1;
BA_ "U_U611_U625_MY20_Hev_Rx" SG_ 947 LifeCycMde_D_Actl 1;
BA_ "U_U611_U625_MY20_Gas_Rx" SG_ 947 LifeCycMde_D_Actl 1;
BA_ "U_U611_U625_MY20_Diesel_Rx" SG_ 947 LifeCycMde_D_Actl 1;
BA_ "U_C519_MY18_5_Gas_Rx" SG_ 947 LifeCycMde_D_Actl 1;
BA_ "U_C519_MY18_5_Diesel_Rx" SG_ 947 LifeCycMde_D_Actl 1;
BA_ "CrossOver_InfoCAN" SG_ 947 LifeCycMde_D_Actl 1;
BA_ "GenSigStartValue" SG_ 947 CrashEvnt_D_Stat 3;
BA_ "CrossOver_InfoCAN" SG_ 947 CrashEvnt_D_Stat 1;
BA_ "WakeupSignal" SG_ 947 CrashEvnt_D_Stat 1;
BA_ "CrossOver_InfoCAN" SG_ 947 FuelPmpInhbt_B_Stat 1;
BA_ "CrossOver_InfoCAN" SG_ 947 BodySrvcRqd_B_Rq 1;
BA_ "CrossOver_InfoCAN" SG_ 947 Delay_Accy 1;
BA_ "WakeupSignal" SG_ 947 Delay_Accy 1;
BA_ "GenSigTimeoutTime_GWM" SG_ 131 HeadLghtHiCtrl_D_RqAhb 300;
BA_ "U_U611_U625_MY20_Phev_Tx" SG_ 131 HeadLghtHiCtrl_D_RqAhb 1;
BA_ "U_CX482_CX483_MY20_Hev_Tx" SG_ 131 HeadLghtHiCtrl_D_RqAhb 1;
BA_ "U_CX482_CX483_MY20_Gas_Tx" SG_ 131 HeadLghtHiCtrl_D_RqAhb 1;
BA_ "U_CX482_CX483_MY20_Diesel_Tx" SG_ 131 HeadLghtHiCtrl_D_RqAhb 1;
BA_ "U_U611_U625_MY20_Hev_Tx" SG_ 131 HeadLghtHiCtrl_D_RqAhb 1;
BA_ "U_U611_U625_MY20_Gas_Tx" SG_ 131 HeadLghtHiCtrl_D_RqAhb 1;
BA_ "U_U611_U625_MY20_Diesel_Tx" SG_ 131 HeadLghtHiCtrl_D_RqAhb 1;
BA_ "U_B500_MY18_Diesel_Tx" SG_ 131 HeadLghtHiCtrl_D_RqAhb 1;
BA_ "U_B500_MY18_Gas_Tx" SG_ 131 HeadLghtHiCtrl_D_RqAhb 1;
BA_ "U_C519_MY18_5_Gas_Tx" SG_ 131 HeadLghtHiCtrl_D_RqAhb 1;
BA_ "U_C519_MY18_5_Diesel_Tx" SG_ 131 HeadLghtHiCtrl_D_RqAhb 1;
BA_ "U_B515_MCA_MY17_Gas_Tx" SG_ 131 HeadLghtHiCtrl_D_RqAhb 1;
BA_ "U_B515_MCA_MY17_Diesel_Tx" SG_ 131 HeadLghtHiCtrl_D_RqAhb 1;
BA_ "U_B479_MY17_Diesel_Tx" SG_ 131 HeadLghtHiCtrl_D_RqAhb 1;
BA_ "U_B479_MY17_Gas_Tx" SG_ 131 HeadLghtHiCtrl_D_RqAhb 1;
BA_ "U_CX482_CX483_MY20_Hev_Rx" SG_ 131 HeadLghtHiCtrl_D_RqAhb 1;
BA_ "U_CX482_CX483_MY20_Gas_Rx" SG_ 131 HeadLghtHiCtrl_D_RqAhb 1;
BA_ "U_CX482_CX483_MY20_Diesel_Rx" SG_ 131 HeadLghtHiCtrl_D_RqAhb 1;
BA_ "U_U611_U625_MY20_Hev_Rx" SG_ 131 HeadLghtHiCtrl_D_RqAhb 1;
BA_ "U_U611_U625_MY20_Gas_Rx" SG_ 131 HeadLghtHiCtrl_D_RqAhb 1;
BA_ "U_U611_U625_MY20_Diesel_Rx" SG_ 131 HeadLghtHiCtrl_D_RqAhb 1;
BA_ "U_C519_MY18_5_Gas_Rx" SG_ 131 HeadLghtHiCtrl_D_RqAhb 1;
BA_ "U_C519_MY18_5_Diesel_Rx" SG_ 131 HeadLghtHiCtrl_D_RqAhb 1;
BA_ "GenSigSendType" SG_ 131 HeadLghtHiCtrl_D_RqAhb 3;
BA_ "WakeupSignal" SG_ 131 HeadLghtHiCtrl_D_RqAhb 1;
BA_ "GenSigTimeoutTime_GWM" SG_ 131 AhbStat_B_Dsply 300;
BA_ "U_U611_U625_MY20_Phev_Tx" SG_ 131 AhbStat_B_Dsply 1;
BA_ "U_CX482_CX483_MY20_Hev_Tx" SG_ 131 AhbStat_B_Dsply 1;
BA_ "U_CX482_CX483_MY20_Gas_Tx" SG_ 131 AhbStat_B_Dsply 1;
BA_ "U_CX482_CX483_MY20_Diesel_Tx" SG_ 131 AhbStat_B_Dsply 1;
BA_ "U_U611_U625_MY20_Hev_Tx" SG_ 131 AhbStat_B_Dsply 1;
BA_ "U_U611_U625_MY20_Gas_Tx" SG_ 131 AhbStat_B_Dsply 1;
BA_ "U_U611_U625_MY20_Diesel_Tx" SG_ 131 AhbStat_B_Dsply 1;
BA_ "U_B500_MY18_Diesel_Tx" SG_ 131 AhbStat_B_Dsply 1;
BA_ "U_B500_MY18_Gas_Tx" SG_ 131 AhbStat_B_Dsply 1;
BA_ "U_C519_MY18_5_Gas_Tx" SG_ 131 AhbStat_B_Dsply 1;
BA_ "U_C519_MY18_5_Diesel_Tx" SG_ 131 AhbStat_B_Dsply 1;
BA_ "U_B515_MCA_MY17_Gas_Tx" SG_ 131 AhbStat_B_Dsply 1;
BA_ "U_B515_MCA_MY17_Diesel_Tx" SG_ 131 AhbStat_B_Dsply 1;
BA_ "U_B479_MY17_Diesel_Tx" SG_ 131 AhbStat_B_Dsply 1;
BA_ "U_B479_MY17_Gas_Tx" SG_ 131 AhbStat_B_Dsply 1;
BA_ "GenSigSendType" SG_ 131 AhbStat_B_Dsply 3;
BA_ "GenSigTimeoutTime_GWM" SG_ 131 WiprFrontSwtch_D_Stat 300;
BA_ "U_U611_U625_MY20_Phev_Tx" SG_ 131 WiprFrontSwtch_D_Stat 1;
BA_ "U_CX482_CX483_MY20_Hev_Tx" SG_ 131 WiprFrontSwtch_D_Stat 1;
BA_ "U_CX482_CX483_MY20_Gas_Tx" SG_ 131 WiprFrontSwtch_D_Stat 1;
BA_ "U_CX482_CX483_MY20_Diesel_Tx" SG_ 131 WiprFrontSwtch_D_Stat 1;
BA_ "U_U611_U625_MY20_Hev_Tx" SG_ 131 WiprFrontSwtch_D_Stat 1;
BA_ "U_U611_U625_MY20_Gas_Tx" SG_ 131 WiprFrontSwtch_D_Stat 1;
BA_ "U_U611_U625_MY20_Diesel_Tx" SG_ 131 WiprFrontSwtch_D_Stat 1;
BA_ "U_B500_MY18_Diesel_Tx" SG_ 131 WiprFrontSwtch_D_Stat 1;
BA_ "U_B500_MY18_Gas_Tx" SG_ 131 WiprFrontSwtch_D_Stat 1;
BA_ "U_C519_MY18_5_Gas_Tx" SG_ 131 WiprFrontSwtch_D_Stat 1;
BA_ "U_C519_MY18_5_Diesel_Tx" SG_ 131 WiprFrontSwtch_D_Stat 1;
BA_ "U_B515_MCA_MY17_Gas_Tx" SG_ 131 WiprFrontSwtch_D_Stat 1;
BA_ "U_B515_MCA_MY17_Diesel_Tx" SG_ 131 WiprFrontSwtch_D_Stat 1;
BA_ "U_B479_MY17_Diesel_Tx" SG_ 131 WiprFrontSwtch_D_Stat 1;
BA_ "U_B479_MY17_Gas_Tx" SG_ 131 WiprFrontSwtch_D_Stat 1;
BA_ "GenSigSendType" SG_ 131 WiprFrontSwtch_D_Stat 3;
BA_ "GenSigStartValue" SG_ 131 WiprFrontSwtch_D_Stat 9;
BA_ "GenSigTimeoutTime_GWM" SG_ 131 HeadLghtHiOn_B_StatAhb 300;
BA_ "U_U611_U625_MY20_Phev_Tx" SG_ 131 HeadLghtHiOn_B_StatAhb 1;
BA_ "U_CX482_CX483_MY20_Hev_Tx" SG_ 131 HeadLghtHiOn_B_StatAhb 1;
BA_ "U_CX482_CX483_MY20_Gas_Tx" SG_ 131 HeadLghtHiOn_B_StatAhb 1;
BA_ "U_CX482_CX483_MY20_Diesel_Tx" SG_ 131 HeadLghtHiOn_B_StatAhb 1;
BA_ "U_U611_U625_MY20_Hev_Tx" SG_ 131 HeadLghtHiOn_B_StatAhb 1;
BA_ "U_U611_U625_MY20_Gas_Tx" SG_ 131 HeadLghtHiOn_B_StatAhb 1;
BA_ "U_U611_U625_MY20_Diesel_Tx" SG_ 131 HeadLghtHiOn_B_StatAhb 1;
BA_ "U_B500_MY18_Diesel_Tx" SG_ 131 HeadLghtHiOn_B_StatAhb 1;
BA_ "U_B500_MY18_Gas_Tx" SG_ 131 HeadLghtHiOn_B_StatAhb 1;
BA_ "U_C519_MY18_5_Gas_Tx" SG_ 131 HeadLghtHiOn_B_StatAhb 1;
BA_ "U_C519_MY18_5_Diesel_Tx" SG_ 131 HeadLghtHiOn_B_StatAhb 1;
BA_ "U_B515_MCA_MY17_Gas_Tx" SG_ 131 HeadLghtHiOn_B_StatAhb 1;
BA_ "U_B515_MCA_MY17_Diesel_Tx" SG_ 131 HeadLghtHiOn_B_StatAhb 1;
BA_ "U_B479_MY17_Diesel_Tx" SG_ 131 HeadLghtHiOn_B_StatAhb 1;
BA_ "U_B479_MY17_Gas_Tx" SG_ 131 HeadLghtHiOn_B_StatAhb 1;
BA_ "U_CX482_CX483_MY20_Hev_Rx" SG_ 131 HeadLghtHiOn_B_StatAhb 1;
BA_ "U_CX482_CX483_MY20_Gas_Rx" SG_ 131 HeadLghtHiOn_B_StatAhb 1;
BA_ "U_CX482_CX483_MY20_Diesel_Rx" SG_ 131 HeadLghtHiOn_B_StatAhb 1;
BA_ "U_U611_U625_MY20_Hev_Rx" SG_ 131 HeadLghtHiOn_B_StatAhb 1;
BA_ "U_U611_U625_MY20_Gas_Rx" SG_ 131 HeadLghtHiOn_B_StatAhb 1;
BA_ "U_U611_U625_MY20_Diesel_Rx" SG_ 131 HeadLghtHiOn_B_StatAhb 1;
BA_ "U_C519_MY18_5_Gas_Rx" SG_ 131 HeadLghtHiOn_B_StatAhb 1;
BA_ "U_C519_MY18_5_Diesel_Rx" SG_ 131 HeadLghtHiOn_B_StatAhb 1;
BA_ "U_B479_MY17_Diesel_Rx" SG_ 131 HeadLghtHiOn_B_StatAhb 1;
BA_ "U_B479_MY17_Gas_Rx" SG_ 131 HeadLghtHiOn_B_StatAhb 1;
BA_ "GenSigSendType" SG_ 131 HeadLghtHiOn_B_StatAhb 3;
BA_ "CrossOver_InfoCAN" SG_ 131 HeadLghtHiOn_B_StatAhb 1;
BA_ "WakeupSignal" SG_ 131 HeadLghtHiOn_B_StatAhb 1;
BA_ "GenSigTimeoutTime_GWM" SG_ 131 HeadLghtHiFlash_D_Actl 300;
BA_ "U_U611_U625_MY20_Phev_Tx" SG_ 131 HeadLghtHiFlash_D_Actl 1;
BA_ "U_CX482_CX483_MY20_Hev_Tx" SG_ 131 HeadLghtHiFlash_D_Actl 1;
BA_ "U_CX482_CX483_MY20_Gas_Tx" SG_ 131 HeadLghtHiFlash_D_Actl 1;
BA_ "U_CX482_CX483_MY20_Diesel_Tx" SG_ 131 HeadLghtHiFlash_D_Actl 1;
BA_ "U_U611_U625_MY20_Hev_Tx" SG_ 131 HeadLghtHiFlash_D_Actl 1;
BA_ "U_U611_U625_MY20_Gas_Tx" SG_ 131 HeadLghtHiFlash_D_Actl 1;
BA_ "U_U611_U625_MY20_Diesel_Tx" SG_ 131 HeadLghtHiFlash_D_Actl 1;
BA_ "U_B500_MY18_Diesel_Tx" SG_ 131 HeadLghtHiFlash_D_Actl 1;
BA_ "U_B500_MY18_Gas_Tx" SG_ 131 HeadLghtHiFlash_D_Actl 1;
BA_ "U_C519_MY18_5_Gas_Tx" SG_ 131 HeadLghtHiFlash_D_Actl 1;
BA_ "U_C519_MY18_5_Diesel_Tx" SG_ 131 HeadLghtHiFlash_D_Actl 1;
BA_ "U_B515_MCA_MY17_Gas_Tx" SG_ 131 HeadLghtHiFlash_D_Actl 1;
BA_ "U_B515_MCA_MY17_Diesel_Tx" SG_ 131 HeadLghtHiFlash_D_Actl 1;
BA_ "U_B479_MY17_Diesel_Tx" SG_ 131 HeadLghtHiFlash_D_Actl 1;
BA_ "U_B479_MY17_Gas_Tx" SG_ 131 HeadLghtHiFlash_D_Actl 1;
BA_ "U_CX482_CX483_MY20_Hev_Rx" SG_ 131 HeadLghtHiFlash_D_Actl 1;
BA_ "U_CX482_CX483_MY20_Gas_Rx" SG_ 131 HeadLghtHiFlash_D_Actl 1;
BA_ "U_CX482_CX483_MY20_Diesel_Rx" SG_ 131 HeadLghtHiFlash_D_Actl 1;
BA_ "U_U611_U625_MY20_Hev_Rx" SG_ 131 HeadLghtHiFlash_D_Actl 1;
BA_ "U_U611_U625_MY20_Gas_Rx" SG_ 131 HeadLghtHiFlash_D_Actl 1;
BA_ "U_U611_U625_MY20_Diesel_Rx" SG_ 131 HeadLghtHiFlash_D_Actl 1;
BA_ "U_C519_MY18_5_Gas_Rx" SG_ 131 HeadLghtHiFlash_D_Actl 1;
BA_ "U_C519_MY18_5_Diesel_Rx" SG_ 131 HeadLghtHiFlash_D_Actl 1;
BA_ "U_B479_MY17_Diesel_Rx" SG_ 131 HeadLghtHiFlash_D_Actl 1;
BA_ "U_B479_MY17_Gas_Rx" SG_ 131 HeadLghtHiFlash_D_Actl 1;
BA_ "GenSigSendType" SG_ 131 HeadLghtHiFlash_D_Actl 3;
BA_ "GenSigTimeoutTime_GWM" SG_ 131 TjaButtnOnOffPress 300;
BA_ "U_U611_U625_MY20_Phev_Tx" SG_ 131 TjaButtnOnOffPress 1;
BA_ "U_CX482_CX483_MY20_Hev_Tx" SG_ 131 TjaButtnOnOffPress 1;
BA_ "U_CX482_CX483_MY20_Gas_Tx" SG_ 131 TjaButtnOnOffPress 1;
BA_ "U_CX482_CX483_MY20_Diesel_Tx" SG_ 131 TjaButtnOnOffPress 1;
BA_ "U_U611_U625_MY20_Hev_Tx" SG_ 131 TjaButtnOnOffPress 1;
BA_ "U_U611_U625_MY20_Gas_Tx" SG_ 131 TjaButtnOnOffPress 1;
BA_ "U_U611_U625_MY20_Diesel_Tx" SG_ 131 TjaButtnOnOffPress 1;
BA_ "U_B500_MY18_Diesel_Tx" SG_ 131 TjaButtnOnOffPress 1;
BA_ "U_B500_MY18_Gas_Tx" SG_ 131 TjaButtnOnOffPress 1;
BA_ "U_C519_MY18_5_Gas_Tx" SG_ 131 TjaButtnOnOffPress 1;
BA_ "U_C519_MY18_5_Diesel_Tx" SG_ 131 TjaButtnOnOffPress 1;
BA_ "U_B479_MY17_Diesel_Tx" SG_ 131 TjaButtnOnOffPress 1;
BA_ "U_B479_MY17_Gas_Tx" SG_ 131 TjaButtnOnOffPress 1;
BA_ "U_CX482_CX483_MY20_Hev_Rx" SG_ 131 TjaButtnOnOffPress 1;
BA_ "U_CX482_CX483_MY20_Gas_Rx" SG_ 131 TjaButtnOnOffPress 1;
BA_ "U_CX482_CX483_MY20_Diesel_Rx" SG_ 131 TjaButtnOnOffPress 1;
BA_ "U_U611_U625_MY20_Hev_Rx" SG_ 131 TjaButtnOnOffPress 1;
BA_ "U_U611_U625_MY20_Gas_Rx" SG_ 131 TjaButtnOnOffPress 1;
BA_ "U_U611_U625_MY20_Diesel_Rx" SG_ 131 TjaButtnOnOffPress 1;
BA_ "U_C519_MY18_5_Gas_Rx" SG_ 131 TjaButtnOnOffPress 1;
BA_ "U_C519_MY18_5_Diesel_Rx" SG_ 131 TjaButtnOnOffPress 1;
BA_ "GenSigSendType" SG_ 131 TjaButtnOnOffPress 3;
BA_ "GenSigTimeoutTime_GWM" SG_ 131 AccButtnGapTogglePress 300;
BA_ "U_U611_U625_MY20_Phev_Tx" SG_ 131 AccButtnGapTogglePress 1;
BA_ "U_CX482_CX483_MY20_Hev_Tx" SG_ 131 AccButtnGapTogglePress 1;
BA_ "U_CX482_CX483_MY20_Gas_Tx" SG_ 131 AccButtnGapTogglePress 1;
BA_ "U_CX482_CX483_MY20_Diesel_Tx" SG_ 131 AccButtnGapTogglePress 1;
BA_ "U_U611_U625_MY20_Hev_Tx" SG_ 131 AccButtnGapTogglePress 1;
BA_ "U_U611_U625_MY20_Gas_Tx" SG_ 131 AccButtnGapTogglePress 1;
BA_ "U_U611_U625_MY20_Diesel_Tx" SG_ 131 AccButtnGapTogglePress 1;
BA_ "U_B500_MY18_Diesel_Tx" SG_ 131 AccButtnGapTogglePress 1;
BA_ "U_B500_MY18_Gas_Tx" SG_ 131 AccButtnGapTogglePress 1;
BA_ "U_C519_MY18_5_Gas_Tx" SG_ 131 AccButtnGapTogglePress 1;
BA_ "U_C519_MY18_5_Diesel_Tx" SG_ 131 AccButtnGapTogglePress 1;
BA_ "U_B515_MCA_MY17_Gas_Tx" SG_ 131 AccButtnGapTogglePress 1;
BA_ "U_B515_MCA_MY17_Diesel_Tx" SG_ 131 AccButtnGapTogglePress 1;
BA_ "U_B479_MY17_Diesel_Tx" SG_ 131 AccButtnGapTogglePress 1;
BA_ "U_B479_MY17_Gas_Tx" SG_ 131 AccButtnGapTogglePress 1;
BA_ "U_CX482_CX483_MY20_Hev_Rx" SG_ 131 AccButtnGapTogglePress 1;
BA_ "U_CX482_CX483_MY20_Gas_Rx" SG_ 131 AccButtnGapTogglePress 1;
BA_ "U_CX482_CX483_MY20_Diesel_Rx" SG_ 131 AccButtnGapTogglePress 1;
BA_ "U_U611_U625_MY20_Hev_Rx" SG_ 131 AccButtnGapTogglePress 1;
BA_ "U_U611_U625_MY20_Gas_Rx" SG_ 131 AccButtnGapTogglePress 1;
BA_ "U_U611_U625_MY20_Diesel_Rx" SG_ 131 AccButtnGapTogglePress 1;
BA_ "U_C519_MY18_5_Gas_Rx" SG_ 131 AccButtnGapTogglePress 1;
BA_ "U_C519_MY18_5_Diesel_Rx" SG_ 131 AccButtnGapTogglePress 1;
BA_ "U_B479_MY17_Diesel_Rx" SG_ 131 AccButtnGapTogglePress 1;
BA_ "U_B479_MY17_Gas_Rx" SG_ 131 AccButtnGapTogglePress 1;
BA_ "GenSigSendType" SG_ 131 AccButtnGapTogglePress 3;
BA_ "GenSigTimeoutTime_GWM" SG_ 131 HeadLghtHiFlash_D_Stat 300;
BA_ "U_U611_U625_MY20_Phev_Tx" SG_ 131 HeadLghtHiFlash_D_Stat 1;
BA_ "U_CX482_CX483_MY20_Hev_Tx" SG_ 131 HeadLghtHiFlash_D_Stat 1;
BA_ "U_CX482_CX483_MY20_Gas_Tx" SG_ 131 HeadLghtHiFlash_D_Stat 1;
BA_ "U_CX482_CX483_MY20_Diesel_Tx" SG_ 131 HeadLghtHiFlash_D_Stat 1;
BA_ "U_U611_U625_MY20_Hev_Tx" SG_ 131 HeadLghtHiFlash_D_Stat 1;
BA_ "U_U611_U625_MY20_Gas_Tx" SG_ 131 HeadLghtHiFlash_D_Stat 1;
BA_ "U_U611_U625_MY20_Diesel_Tx" SG_ 131 HeadLghtHiFlash_D_Stat 1;
BA_ "U_B500_MY18_Diesel_Tx" SG_ 131 HeadLghtHiFlash_D_Stat 1;
BA_ "U_B500_MY18_Gas_Tx" SG_ 131 HeadLghtHiFlash_D_Stat 1;
BA_ "U_C519_MY18_5_Gas_Tx" SG_ 131 HeadLghtHiFlash_D_Stat 1;
BA_ "U_C519_MY18_5_Diesel_Tx" SG_ 131 HeadLghtHiFlash_D_Stat 1;
BA_ "U_B515_MCA_MY17_Gas_Tx" SG_ 131 HeadLghtHiFlash_D_Stat 1;
BA_ "U_B515_MCA_MY17_Diesel_Tx" SG_ 131 HeadLghtHiFlash_D_Stat 1;
BA_ "U_B479_MY17_Diesel_Tx" SG_ 131 HeadLghtHiFlash_D_Stat 1;
BA_ "U_B479_MY17_Gas_Tx" SG_ 131 HeadLghtHiFlash_D_Stat 1;
BA_ "U_CX482_CX483_MY20_Hev_Rx" SG_ 131 HeadLghtHiFlash_D_Stat 1;
BA_ "U_CX482_CX483_MY20_Gas_Rx" SG_ 131 HeadLghtHiFlash_D_Stat 1;
BA_ "U_CX482_CX483_MY20_Diesel_Rx" SG_ 131 HeadLghtHiFlash_D_Stat 1;
BA_ "U_U611_U625_MY20_Hev_Rx" SG_ 131 HeadLghtHiFlash_D_Stat 1;
BA_ "U_U611_U625_MY20_Gas_Rx" SG_ 131 HeadLghtHiFlash_D_Stat 1;
BA_ "U_U611_U625_MY20_Diesel_Rx" SG_ 131 HeadLghtHiFlash_D_Stat 1;
BA_ "U_C519_MY18_5_Gas_Rx" SG_ 131 HeadLghtHiFlash_D_Stat 1;
BA_ "U_C519_MY18_5_Diesel_Rx" SG_ 131 HeadLghtHiFlash_D_Stat 1;
BA_ "U_B479_MY17_Diesel_Rx" SG_ 131 HeadLghtHiFlash_D_Stat 1;
BA_ "U_B479_MY17_Gas_Rx" SG_ 131 HeadLghtHiFlash_D_Stat 1;
BA_ "GenSigSendType" SG_ 131 HeadLghtHiFlash_D_Stat 3;
BA_ "WakeupSignal" SG_ 131 HeadLghtHiFlash_D_Stat 1;
BA_ "GenSigTimeoutTime_GWM" SG_ 131 WiprFront_D_Stat 300;
BA_ "U_U611_U625_MY20_Phev_Tx" SG_ 131 WiprFront_D_Stat 1;
BA_ "U_CX482_CX483_MY20_Hev_Tx" SG_ 131 WiprFront_D_Stat 1;
BA_ "U_CX482_CX483_MY20_Gas_Tx" SG_ 131 WiprFront_D_Stat 1;
BA_ "U_CX482_CX483_MY20_Diesel_Tx" SG_ 131 WiprFront_D_Stat 1;
BA_ "U_U611_U625_MY20_Hev_Tx" SG_ 131 WiprFront_D_Stat 1;
BA_ "U_U611_U625_MY20_Gas_Tx" SG_ 131 WiprFront_D_Stat 1;
BA_ "U_U611_U625_MY20_Diesel_Tx" SG_ 131 WiprFront_D_Stat 1;
BA_ "U_B500_MY18_Diesel_Tx" SG_ 131 WiprFront_D_Stat 1;
BA_ "U_B500_MY18_Gas_Tx" SG_ 131 WiprFront_D_Stat 1;
BA_ "U_C519_MY18_5_Gas_Tx" SG_ 131 WiprFront_D_Stat 1;
BA_ "U_C519_MY18_5_Diesel_Tx" SG_ 131 WiprFront_D_Stat 1;
BA_ "U_B515_MCA_MY17_Gas_Tx" SG_ 131 WiprFront_D_Stat 1;
BA_ "U_B515_MCA_MY17_Diesel_Tx" SG_ 131 WiprFront_D_Stat 1;
BA_ "U_B479_MY17_Diesel_Tx" SG_ 131 WiprFront_D_Stat 1;
BA_ "U_B479_MY17_Gas_Tx" SG_ 131 WiprFront_D_Stat 1;
BA_ "U_CX482_CX483_MY20_Hev_Rx" SG_ 131 WiprFront_D_Stat 1;
BA_ "U_CX482_CX483_MY20_Gas_Rx" SG_ 131 WiprFront_D_Stat 1;
BA_ "U_CX482_CX483_MY20_Diesel_Rx" SG_ 131 WiprFront_D_Stat 1;
BA_ "U_U611_U625_MY20_Hev_Rx" SG_ 131 WiprFront_D_Stat 1;
BA_ "U_U611_U625_MY20_Gas_Rx" SG_ 131 WiprFront_D_Stat 1;
BA_ "U_U611_U625_MY20_Diesel_Rx" SG_ 131 WiprFront_D_Stat 1;
BA_ "U_C519_MY18_5_Gas_Rx" SG_ 131 WiprFront_D_Stat 1;
BA_ "U_C519_MY18_5_Diesel_Rx" SG_ 131 WiprFront_D_Stat 1;
BA_ "GenSigSendType" SG_ 131 WiprFront_D_Stat 3;
BA_ "GenSigStartValue" SG_ 131 WiprFront_D_Stat 15;
BA_ "GenSigTimeoutTime_GWM" SG_ 131 TurnLghtSwtch_D_Stat 300;
BA_ "U_U611_U625_MY20_Phev_Tx" SG_ 131 TurnLghtSwtch_D_Stat 1;
BA_ "U_CX482_CX483_MY20_Hev_Tx" SG_ 131 TurnLghtSwtch_D_Stat 1;
BA_ "U_CX482_CX483_MY20_Gas_Tx" SG_ 131 TurnLghtSwtch_D_Stat 1;
BA_ "U_CX482_CX483_MY20_Diesel_Tx" SG_ 131 TurnLghtSwtch_D_Stat 1;
BA_ "U_U611_U625_MY20_Hev_Tx" SG_ 131 TurnLghtSwtch_D_Stat 1;
BA_ "U_U611_U625_MY20_Gas_Tx" SG_ 131 TurnLghtSwtch_D_Stat 1;
BA_ "U_U611_U625_MY20_Diesel_Tx" SG_ 131 TurnLghtSwtch_D_Stat 1;
BA_ "U_B500_MY18_Diesel_Tx" SG_ 131 TurnLghtSwtch_D_Stat 1;
BA_ "U_B500_MY18_Gas_Tx" SG_ 131 TurnLghtSwtch_D_Stat 1;
BA_ "U_C519_MY18_5_Gas_Tx" SG_ 131 TurnLghtSwtch_D_Stat 1;
BA_ "U_C519_MY18_5_Diesel_Tx" SG_ 131 TurnLghtSwtch_D_Stat 1;
BA_ "U_B515_MCA_MY17_Gas_Tx" SG_ 131 TurnLghtSwtch_D_Stat 1;
BA_ "U_B515_MCA_MY17_Diesel_Tx" SG_ 131 TurnLghtSwtch_D_Stat 1;
BA_ "U_B479_MY17_Diesel_Tx" SG_ 131 TurnLghtSwtch_D_Stat 1;
BA_ "U_B479_MY17_Gas_Tx" SG_ 131 TurnLghtSwtch_D_Stat 1;
BA_ "U_U611_U625_MY20_Phev_Rx" SG_ 131 TurnLghtSwtch_D_Stat 1;
BA_ "U_B500_MY18_Diesel_Rx" SG_ 131 TurnLghtSwtch_D_Stat 1;
BA_ "U_B500_MY18_Gas_Rx" SG_ 131 TurnLghtSwtch_D_Stat 1;
BA_ "U_CX482_CX483_MY20_Hev_Rx" SG_ 131 TurnLghtSwtch_D_Stat 1;
BA_ "U_CX482_CX483_MY20_Gas_Rx" SG_ 131 TurnLghtSwtch_D_Stat 1;
BA_ "U_CX482_CX483_MY20_Diesel_Rx" SG_ 131 TurnLghtSwtch_D_Stat 1;
BA_ "U_U611_U625_MY20_Hev_Rx" SG_ 131 TurnLghtSwtch_D_Stat 1;
BA_ "U_U611_U625_MY20_Gas_Rx" SG_ 131 TurnLghtSwtch_D_Stat 1;
BA_ "U_U611_U625_MY20_Diesel_Rx" SG_ 131 TurnLghtSwtch_D_Stat 1;
BA_ "U_C519_MY18_5_Gas_Rx" SG_ 131 TurnLghtSwtch_D_Stat 1;
BA_ "U_C519_MY18_5_Diesel_Rx" SG_ 131 TurnLghtSwtch_D_Stat 1;
BA_ "U_B479_MY17_Diesel_Rx" SG_ 131 TurnLghtSwtch_D_Stat 1;
BA_ "U_B479_MY17_Gas_Rx" SG_ 131 TurnLghtSwtch_D_Stat 1;
BA_ "GenSigSendType" SG_ 131 TurnLghtSwtch_D_Stat 3;
BA_ "CrossOver_InfoCAN" SG_ 131 TurnLghtSwtch_D_Stat 1;
BA_ "WakeupSignal" SG_ 131 TurnLghtSwtch_D_Stat 1;
BA_ "GenSigTimeoutTime_GWM" SG_ 131 LghtAmb_D_Sns 300;
BA_ "U_U611_U625_MY20_Phev_Tx" SG_ 131 LghtAmb_D_Sns 1;
BA_ "U_CX482_CX483_MY20_Hev_Tx" SG_ 131 LghtAmb_D_Sns 1;
BA_ "U_CX482_CX483_MY20_Gas_Tx" SG_ 131 LghtAmb_D_Sns 1;
BA_ "U_CX482_CX483_MY20_Diesel_Tx" SG_ 131 LghtAmb_D_Sns 1;
BA_ "U_U611_U625_MY20_Hev_Tx" SG_ 131 LghtAmb_D_Sns 1;
BA_ "U_U611_U625_MY20_Gas_Tx" SG_ 131 LghtAmb_D_Sns 1;
BA_ "U_U611_U625_MY20_Diesel_Tx" SG_ 131 LghtAmb_D_Sns 1;
BA_ "U_B500_MY18_Diesel_Tx" SG_ 131 LghtAmb_D_Sns 1;
BA_ "U_B500_MY18_Gas_Tx" SG_ 131 LghtAmb_D_Sns 1;
BA_ "U_C519_MY18_5_Gas_Tx" SG_ 131 LghtAmb_D_Sns 1;
BA_ "U_C519_MY18_5_Diesel_Tx" SG_ 131 LghtAmb_D_Sns 1;
BA_ "U_B515_MCA_MY17_Gas_Tx" SG_ 131 LghtAmb_D_Sns 1;
BA_ "U_B515_MCA_MY17_Diesel_Tx" SG_ 131 LghtAmb_D_Sns 1;
BA_ "U_B479_MY17_Diesel_Tx" SG_ 131 LghtAmb_D_Sns 1;
BA_ "U_B479_MY17_Gas_Tx" SG_ 131 LghtAmb_D_Sns 1;
BA_ "U_B479_MY17_Diesel_Rx" SG_ 131 LghtAmb_D_Sns 1;
BA_ "U_B479_MY17_Gas_Rx" SG_ 131 LghtAmb_D_Sns 1;
BA_ "U_CX482_CX483_MY20_Hev_Rx" SG_ 131 LghtAmb_D_Sns 1;
BA_ "U_CX482_CX483_MY20_Gas_Rx" SG_ 131 LghtAmb_D_Sns 1;
BA_ "U_CX482_CX483_MY20_Diesel_Rx" SG_ 131 LghtAmb_D_Sns 1;
BA_ "U_U611_U625_MY20_Hev_Rx" SG_ 131 LghtAmb_D_Sns 1;
BA_ "U_U611_U625_MY20_Gas_Rx" SG_ 131 LghtAmb_D_Sns 1;
BA_ "U_U611_U625_MY20_Diesel_Rx" SG_ 131 LghtAmb_D_Sns 1;
BA_ "U_C519_MY18_5_Gas_Rx" SG_ 131 LghtAmb_D_Sns 1;
BA_ "U_C519_MY18_5_Diesel_Rx" SG_ 131 LghtAmb_D_Sns 1;
BA_ "GenSigSendType" SG_ 131 LghtAmb_D_Sns 3;
BA_ "GenSigStartValue" SG_ 131 LghtAmb_D_Sns 7;
BA_ "GenSigTimeoutTime_GWM" SG_ 131 AccButtnGapIncPress 300;
BA_ "U_U611_U625_MY20_Phev_Tx" SG_ 131 AccButtnGapIncPress 1;
BA_ "U_CX482_CX483_MY20_Hev_Tx" SG_ 131 AccButtnGapIncPress 1;
BA_ "U_CX482_CX483_MY20_Gas_Tx" SG_ 131 AccButtnGapIncPress 1;
BA_ "U_CX482_CX483_MY20_Diesel_Tx" SG_ 131 AccButtnGapIncPress 1;
BA_ "U_U611_U625_MY20_Hev_Tx" SG_ 131 AccButtnGapIncPress 1;
BA_ "U_U611_U625_MY20_Gas_Tx" SG_ 131 AccButtnGapIncPress 1;
BA_ "U_U611_U625_MY20_Diesel_Tx" SG_ 131 AccButtnGapIncPress 1;
BA_ "U_B500_MY18_Diesel_Tx" SG_ 131 AccButtnGapIncPress 1;
BA_ "U_B500_MY18_Gas_Tx" SG_ 131 AccButtnGapIncPress 1;
BA_ "U_C519_MY18_5_Gas_Tx" SG_ 131 AccButtnGapIncPress 1;
BA_ "U_C519_MY18_5_Diesel_Tx" SG_ 131 AccButtnGapIncPress 1;
BA_ "U_B515_MCA_MY17_Gas_Tx" SG_ 131 AccButtnGapIncPress 1;
BA_ "U_B515_MCA_MY17_Diesel_Tx" SG_ 131 AccButtnGapIncPress 1;
BA_ "U_B479_MY17_Diesel_Tx" SG_ 131 AccButtnGapIncPress 1;
BA_ "U_B479_MY17_Gas_Tx" SG_ 131 AccButtnGapIncPress 1;
BA_ "U_CX482_CX483_MY20_Hev_Rx" SG_ 131 AccButtnGapIncPress 1;
BA_ "U_CX482_CX483_MY20_Gas_Rx" SG_ 131 AccButtnGapIncPress 1;
BA_ "U_CX482_CX483_MY20_Diesel_Rx" SG_ 131 AccButtnGapIncPress 1;
BA_ "U_U611_U625_MY20_Hev_Rx" SG_ 131 AccButtnGapIncPress 1;
BA_ "U_U611_U625_MY20_Gas_Rx" SG_ 131 AccButtnGapIncPress 1;
BA_ "U_U611_U625_MY20_Diesel_Rx" SG_ 131 AccButtnGapIncPress 1;
BA_ "U_C519_MY18_5_Gas_Rx" SG_ 131 AccButtnGapIncPress 1;
BA_ "U_C519_MY18_5_Diesel_Rx" SG_ 131 AccButtnGapIncPress 1;
BA_ "U_B479_MY17_Diesel_Rx" SG_ 131 AccButtnGapIncPress 1;
BA_ "U_B479_MY17_Gas_Rx" SG_ 131 AccButtnGapIncPress 1;
BA_ "GenSigSendType" SG_ 131 AccButtnGapIncPress 3;
BA_ "GenSigTimeoutTime_GWM" SG_ 131 AccButtnGapDecPress 300;
BA_ "U_U611_U625_MY20_Phev_Tx" SG_ 131 AccButtnGapDecPress 1;
BA_ "U_CX482_CX483_MY20_Hev_Tx" SG_ 131 AccButtnGapDecPress 1;
BA_ "U_CX482_CX483_MY20_Gas_Tx" SG_ 131 AccButtnGapDecPress 1;
BA_ "U_CX482_CX483_MY20_Diesel_Tx" SG_ 131 AccButtnGapDecPress 1;
BA_ "U_U611_U625_MY20_Hev_Tx" SG_ 131 AccButtnGapDecPress 1;
BA_ "U_U611_U625_MY20_Gas_Tx" SG_ 131 AccButtnGapDecPress 1;
BA_ "U_U611_U625_MY20_Diesel_Tx" SG_ 131 AccButtnGapDecPress 1;
BA_ "U_B500_MY18_Diesel_Tx" SG_ 131 AccButtnGapDecPress 1;
BA_ "U_B500_MY18_Gas_Tx" SG_ 131 AccButtnGapDecPress 1;
BA_ "U_C519_MY18_5_Gas_Tx" SG_ 131 AccButtnGapDecPress 1;
BA_ "U_C519_MY18_5_Diesel_Tx" SG_ 131 AccButtnGapDecPress 1;
BA_ "U_B515_MCA_MY17_Gas_Tx" SG_ 131 AccButtnGapDecPress 1;
BA_ "U_B515_MCA_MY17_Diesel_Tx" SG_ 131 AccButtnGapDecPress 1;
BA_ "U_B479_MY17_Diesel_Tx" SG_ 131 AccButtnGapDecPress 1;
BA_ "U_B479_MY17_Gas_Tx" SG_ 131 AccButtnGapDecPress 1;
BA_ "U_CX482_CX483_MY20_Hev_Rx" SG_ 131 AccButtnGapDecPress 1;
BA_ "U_CX482_CX483_MY20_Gas_Rx" SG_ 131 AccButtnGapDecPress 1;
BA_ "U_CX482_CX483_MY20_Diesel_Rx" SG_ 131 AccButtnGapDecPress 1;
BA_ "U_U611_U625_MY20_Hev_Rx" SG_ 131 AccButtnGapDecPress 1;
BA_ "U_U611_U625_MY20_Gas_Rx" SG_ 131 AccButtnGapDecPress 1;
BA_ "U_U611_U625_MY20_Diesel_Rx" SG_ 131 AccButtnGapDecPress 1;
BA_ "U_C519_MY18_5_Gas_Rx" SG_ 131 AccButtnGapDecPress 1;
BA_ "U_C519_MY18_5_Diesel_Rx" SG_ 131 AccButtnGapDecPress 1;
BA_ "U_B479_MY17_Diesel_Rx" SG_ 131 AccButtnGapDecPress 1;
BA_ "U_B479_MY17_Gas_Rx" SG_ 131 AccButtnGapDecPress 1;
BA_ "GenSigSendType" SG_ 131 AccButtnGapDecPress 3;
BA_ "GenSigTimeoutTime_GWM" SG_ 131 AslButtnOnOffPress 300;
BA_ "U_U611_U625_MY20_Phev_Tx" SG_ 131 AslButtnOnOffPress 1;
BA_ "U_CX482_CX483_MY20_Hev_Tx" SG_ 131 AslButtnOnOffPress 1;
BA_ "U_CX482_CX483_MY20_Gas_Tx" SG_ 131 AslButtnOnOffPress 1;
BA_ "U_CX482_CX483_MY20_Diesel_Tx" SG_ 131 AslButtnOnOffPress 1;
BA_ "U_U611_U625_MY20_Hev_Tx" SG_ 131 AslButtnOnOffPress 1;
BA_ "U_U611_U625_MY20_Gas_Tx" SG_ 131 AslButtnOnOffPress 1;
BA_ "U_U611_U625_MY20_Diesel_Tx" SG_ 131 AslButtnOnOffPress 1;
BA_ "U_B500_MY18_Diesel_Tx" SG_ 131 AslButtnOnOffPress 1;
BA_ "U_B500_MY18_Gas_Tx" SG_ 131 AslButtnOnOffPress 1;
BA_ "U_C519_MY18_5_Gas_Tx" SG_ 131 AslButtnOnOffPress 1;
BA_ "U_C519_MY18_5_Diesel_Tx" SG_ 131 AslButtnOnOffPress 1;
BA_ "U_B515_MCA_MY17_Gas_Tx" SG_ 131 AslButtnOnOffPress 1;
BA_ "U_B515_MCA_MY17_Diesel_Tx" SG_ 131 AslButtnOnOffPress 1;
BA_ "U_B479_MY17_Diesel_Tx" SG_ 131 AslButtnOnOffPress 1;
BA_ "U_B479_MY17_Gas_Tx" SG_ 131 AslButtnOnOffPress 1;
BA_ "GenSigSendType" SG_ 131 AslButtnOnOffPress 3;
BA_ "GenSigTimeoutTime_GWM" SG_ 131 AslButtnOnOffCnclPress 300;
BA_ "U_U611_U625_MY20_Phev_Tx" SG_ 131 AslButtnOnOffCnclPress 1;
BA_ "U_CX482_CX483_MY20_Hev_Tx" SG_ 131 AslButtnOnOffCnclPress 1;
BA_ "U_CX482_CX483_MY20_Gas_Tx" SG_ 131 AslButtnOnOffCnclPress 1;
BA_ "U_CX482_CX483_MY20_Diesel_Tx" SG_ 131 AslButtnOnOffCnclPress 1;
BA_ "U_U611_U625_MY20_Hev_Tx" SG_ 131 AslButtnOnOffCnclPress 1;
BA_ "U_U611_U625_MY20_Gas_Tx" SG_ 131 AslButtnOnOffCnclPress 1;
BA_ "U_U611_U625_MY20_Diesel_Tx" SG_ 131 AslButtnOnOffCnclPress 1;
BA_ "U_B500_MY18_Diesel_Tx" SG_ 131 AslButtnOnOffCnclPress 1;
BA_ "U_B500_MY18_Gas_Tx" SG_ 131 AslButtnOnOffCnclPress 1;
BA_ "U_C519_MY18_5_Gas_Tx" SG_ 131 AslButtnOnOffCnclPress 1;
BA_ "U_C519_MY18_5_Diesel_Tx" SG_ 131 AslButtnOnOffCnclPress 1;
BA_ "U_B515_MCA_MY17_Gas_Tx" SG_ 131 AslButtnOnOffCnclPress 1;
BA_ "U_B515_MCA_MY17_Diesel_Tx" SG_ 131 AslButtnOnOffCnclPress 1;
BA_ "U_B479_MY17_Diesel_Tx" SG_ 131 AslButtnOnOffCnclPress 1;
BA_ "U_B479_MY17_Gas_Tx" SG_ 131 AslButtnOnOffCnclPress 1;
BA_ "GenSigSendType" SG_ 131 AslButtnOnOffCnclPress 3;
BA_ "GenSigTimeoutTime_GWM" SG_ 131 CcButtnOnPress 300;
BA_ "U_U611_U625_MY20_Phev_Tx" SG_ 131 CcButtnOnPress 1;
BA_ "U_CX482_CX483_MY20_Hev_Tx" SG_ 131 CcButtnOnPress 1;
BA_ "U_CX482_CX483_MY20_Gas_Tx" SG_ 131 CcButtnOnPress 1;
BA_ "U_CX482_CX483_MY20_Diesel_Tx" SG_ 131 CcButtnOnPress 1;
BA_ "U_U611_U625_MY20_Hev_Tx" SG_ 131 CcButtnOnPress 1;
BA_ "U_U611_U625_MY20_Gas_Tx" SG_ 131 CcButtnOnPress 1;
BA_ "U_U611_U625_MY20_Diesel_Tx" SG_ 131 CcButtnOnPress 1;
BA_ "U_B500_MY18_Diesel_Tx" SG_ 131 CcButtnOnPress 1;
BA_ "U_B500_MY18_Gas_Tx" SG_ 131 CcButtnOnPress 1;
BA_ "U_C519_MY18_5_Gas_Tx" SG_ 131 CcButtnOnPress 1;
BA_ "U_C519_MY18_5_Diesel_Tx" SG_ 131 CcButtnOnPress 1;
BA_ "U_B515_MCA_MY17_Gas_Tx" SG_ 131 CcButtnOnPress 1;
BA_ "U_B515_MCA_MY17_Diesel_Tx" SG_ 131 CcButtnOnPress 1;
BA_ "U_B479_MY17_Diesel_Tx" SG_ 131 CcButtnOnPress 1;
BA_ "U_B479_MY17_Gas_Tx" SG_ 131 CcButtnOnPress 1;
BA_ "GenSigSendType" SG_ 131 CcButtnOnPress 3;
BA_ "GenSigTimeoutTime_GWM" SG_ 131 CcButtnOnOffPress 300;
BA_ "U_U611_U625_MY20_Phev_Tx" SG_ 131 CcButtnOnOffPress 1;
BA_ "U_CX482_CX483_MY20_Hev_Tx" SG_ 131 CcButtnOnOffPress 1;
BA_ "U_CX482_CX483_MY20_Gas_Tx" SG_ 131 CcButtnOnOffPress 1;
BA_ "U_CX482_CX483_MY20_Diesel_Tx" SG_ 131 CcButtnOnOffPress 1;
BA_ "U_U611_U625_MY20_Hev_Tx" SG_ 131 CcButtnOnOffPress 1;
BA_ "U_U611_U625_MY20_Gas_Tx" SG_ 131 CcButtnOnOffPress 1;
BA_ "U_U611_U625_MY20_Diesel_Tx" SG_ 131 CcButtnOnOffPress 1;
BA_ "U_B500_MY18_Diesel_Tx" SG_ 131 CcButtnOnOffPress 1;
BA_ "U_B500_MY18_Gas_Tx" SG_ 131 CcButtnOnOffPress 1;
BA_ "U_C519_MY18_5_Gas_Tx" SG_ 131 CcButtnOnOffPress 1;
BA_ "U_C519_MY18_5_Diesel_Tx" SG_ 131 CcButtnOnOffPress 1;
BA_ "U_B515_MCA_MY17_Gas_Tx" SG_ 131 CcButtnOnOffPress 1;
BA_ "U_B515_MCA_MY17_Diesel_Tx" SG_ 131 CcButtnOnOffPress 1;
BA_ "U_B479_MY17_Diesel_Tx" SG_ 131 CcButtnOnOffPress 1;
BA_ "U_B479_MY17_Gas_Tx" SG_ 131 CcButtnOnOffPress 1;
BA_ "U_CX482_CX483_MY20_Hev_Rx" SG_ 131 CcButtnOnOffPress 1;
BA_ "U_CX482_CX483_MY20_Gas_Rx" SG_ 131 CcButtnOnOffPress 1;
BA_ "U_CX482_CX483_MY20_Diesel_Rx" SG_ 131 CcButtnOnOffPress 1;
BA_ "U_U611_U625_MY20_Hev_Rx" SG_ 131 CcButtnOnOffPress 1;
BA_ "U_U611_U625_MY20_Gas_Rx" SG_ 131 CcButtnOnOffPress 1;
BA_ "U_U611_U625_MY20_Diesel_Rx" SG_ 131 CcButtnOnOffPress 1;
BA_ "U_C519_MY18_5_Gas_Rx" SG_ 131 CcButtnOnOffPress 1;
BA_ "U_C519_MY18_5_Diesel_Rx" SG_ 131 CcButtnOnOffPress 1;
BA_ "U_B479_MY17_Diesel_Rx" SG_ 131 CcButtnOnOffPress 1;
BA_ "U_B479_MY17_Gas_Rx" SG_ 131 CcButtnOnOffPress 1;
BA_ "GenSigSendType" SG_ 131 CcButtnOnOffPress 3;
BA_ "GenSigTimeoutTime_GWM" SG_ 131 CcButtnOnOffCnclPress 300;
BA_ "U_U611_U625_MY20_Phev_Tx" SG_ 131 CcButtnOnOffCnclPress 1;
BA_ "U_CX482_CX483_MY20_Hev_Tx" SG_ 131 CcButtnOnOffCnclPress 1;
BA_ "U_CX482_CX483_MY20_Gas_Tx" SG_ 131 CcButtnOnOffCnclPress 1;
BA_ "U_CX482_CX483_MY20_Diesel_Tx" SG_ 131 CcButtnOnOffCnclPress 1;
BA_ "U_U611_U625_MY20_Hev_Tx" SG_ 131 CcButtnOnOffCnclPress 1;
BA_ "U_U611_U625_MY20_Gas_Tx" SG_ 131 CcButtnOnOffCnclPress 1;
BA_ "U_U611_U625_MY20_Diesel_Tx" SG_ 131 CcButtnOnOffCnclPress 1;
BA_ "U_B500_MY18_Diesel_Tx" SG_ 131 CcButtnOnOffCnclPress 1;
BA_ "U_B500_MY18_Gas_Tx" SG_ 131 CcButtnOnOffCnclPress 1;
BA_ "U_C519_MY18_5_Gas_Tx" SG_ 131 CcButtnOnOffCnclPress 1;
BA_ "U_C519_MY18_5_Diesel_Tx" SG_ 131 CcButtnOnOffCnclPress 1;
BA_ "U_B515_MCA_MY17_Gas_Tx" SG_ 131 CcButtnOnOffCnclPress 1;
BA_ "U_B515_MCA_MY17_Diesel_Tx" SG_ 131 CcButtnOnOffCnclPress 1;
BA_ "U_B479_MY17_Diesel_Tx" SG_ 131 CcButtnOnOffCnclPress 1;
BA_ "U_B479_MY17_Gas_Tx" SG_ 131 CcButtnOnOffCnclPress 1;
BA_ "U_CX482_CX483_MY20_Hev_Rx" SG_ 131 CcButtnOnOffCnclPress 1;
BA_ "U_CX482_CX483_MY20_Gas_Rx" SG_ 131 CcButtnOnOffCnclPress 1;
BA_ "U_CX482_CX483_MY20_Diesel_Rx" SG_ 131 CcButtnOnOffCnclPress 1;
BA_ "U_U611_U625_MY20_Hev_Rx" SG_ 131 CcButtnOnOffCnclPress 1;
BA_ "U_U611_U625_MY20_Gas_Rx" SG_ 131 CcButtnOnOffCnclPress 1;
BA_ "U_U611_U625_MY20_Diesel_Rx" SG_ 131 CcButtnOnOffCnclPress 1;
BA_ "U_C519_MY18_5_Gas_Rx" SG_ 131 CcButtnOnOffCnclPress 1;
BA_ "U_C519_MY18_5_Diesel_Rx" SG_ 131 CcButtnOnOffCnclPress 1;
BA_ "U_B479_MY17_Diesel_Rx" SG_ 131 CcButtnOnOffCnclPress 1;
BA_ "U_B479_MY17_Gas_Rx" SG_ 131 CcButtnOnOffCnclPress 1;
BA_ "GenSigSendType" SG_ 131 CcButtnOnOffCnclPress 3;
BA_ "GenSigTimeoutTime_GWM" SG_ 131 CcButtnOffPress 300;
BA_ "U_U611_U625_MY20_Phev_Tx" SG_ 131 CcButtnOffPress 1;
BA_ "U_CX482_CX483_MY20_Hev_Tx" SG_ 131 CcButtnOffPress 1;
BA_ "U_CX482_CX483_MY20_Gas_Tx" SG_ 131 CcButtnOffPress 1;
BA_ "U_CX482_CX483_MY20_Diesel_Tx" SG_ 131 CcButtnOffPress 1;
BA_ "U_U611_U625_MY20_Hev_Tx" SG_ 131 CcButtnOffPress 1;
BA_ "U_U611_U625_MY20_Gas_Tx" SG_ 131 CcButtnOffPress 1;
BA_ "U_U611_U625_MY20_Diesel_Tx" SG_ 131 CcButtnOffPress 1;
BA_ "U_B500_MY18_Diesel_Tx" SG_ 131 CcButtnOffPress 1;
BA_ "U_B500_MY18_Gas_Tx" SG_ 131 CcButtnOffPress 1;
BA_ "U_C519_MY18_5_Gas_Tx" SG_ 131 CcButtnOffPress 1;
BA_ "U_C519_MY18_5_Diesel_Tx" SG_ 131 CcButtnOffPress 1;
BA_ "U_B515_MCA_MY17_Gas_Tx" SG_ 131 CcButtnOffPress 1;
BA_ "U_B515_MCA_MY17_Diesel_Tx" SG_ 131 CcButtnOffPress 1;
BA_ "U_B479_MY17_Diesel_Tx" SG_ 131 CcButtnOffPress 1;
BA_ "U_B479_MY17_Gas_Tx" SG_ 131 CcButtnOffPress 1;
BA_ "GenSigSendType" SG_ 131 CcButtnOffPress 3;
BA_ "GenSigTimeoutTime_GWM" SG_ 131 CcAsllButtnResPress 300;
BA_ "U_U611_U625_MY20_Phev_Tx" SG_ 131 CcAsllButtnResPress 1;
BA_ "U_CX482_CX483_MY20_Hev_Tx" SG_ 131 CcAsllButtnResPress 1;
BA_ "U_CX482_CX483_MY20_Gas_Tx" SG_ 131 CcAsllButtnResPress 1;
BA_ "U_CX482_CX483_MY20_Diesel_Tx" SG_ 131 CcAsllButtnResPress 1;
BA_ "U_U611_U625_MY20_Hev_Tx" SG_ 131 CcAsllButtnResPress 1;
BA_ "U_U611_U625_MY20_Gas_Tx" SG_ 131 CcAsllButtnResPress 1;
BA_ "U_U611_U625_MY20_Diesel_Tx" SG_ 131 CcAsllButtnResPress 1;
BA_ "U_B500_MY18_Diesel_Tx" SG_ 131 CcAsllButtnResPress 1;
BA_ "U_B500_MY18_Gas_Tx" SG_ 131 CcAsllButtnResPress 1;
BA_ "U_C519_MY18_5_Gas_Tx" SG_ 131 CcAsllButtnResPress 1;
BA_ "U_C519_MY18_5_Diesel_Tx" SG_ 131 CcAsllButtnResPress 1;
BA_ "U_B515_MCA_MY17_Gas_Tx" SG_ 131 CcAsllButtnResPress 1;
BA_ "U_B515_MCA_MY17_Diesel_Tx" SG_ 131 CcAsllButtnResPress 1;
BA_ "U_B479_MY17_Diesel_Tx" SG_ 131 CcAsllButtnResPress 1;
BA_ "U_B479_MY17_Gas_Tx" SG_ 131 CcAsllButtnResPress 1;
BA_ "GenSigSendType" SG_ 131 CcAsllButtnResPress 3;
BA_ "GenSigTimeoutTime_GWM" SG_ 131 CcAslButtnSetPress 300;
BA_ "U_U611_U625_MY20_Phev_Tx" SG_ 131 CcAslButtnSetPress 1;
BA_ "U_CX482_CX483_MY20_Hev_Tx" SG_ 131 CcAslButtnSetPress 1;
BA_ "U_CX482_CX483_MY20_Gas_Tx" SG_ 131 CcAslButtnSetPress 1;
BA_ "U_CX482_CX483_MY20_Diesel_Tx" SG_ 131 CcAslButtnSetPress 1;
BA_ "U_U611_U625_MY20_Hev_Tx" SG_ 131 CcAslButtnSetPress 1;
BA_ "U_U611_U625_MY20_Gas_Tx" SG_ 131 CcAslButtnSetPress 1;
BA_ "U_U611_U625_MY20_Diesel_Tx" SG_ 131 CcAslButtnSetPress 1;
BA_ "U_B500_MY18_Diesel_Tx" SG_ 131 CcAslButtnSetPress 1;
BA_ "U_B500_MY18_Gas_Tx" SG_ 131 CcAslButtnSetPress 1;
BA_ "U_C519_MY18_5_Gas_Tx" SG_ 131 CcAslButtnSetPress 1;
BA_ "U_C519_MY18_5_Diesel_Tx" SG_ 131 CcAslButtnSetPress 1;
BA_ "U_B515_MCA_MY17_Gas_Tx" SG_ 131 CcAslButtnSetPress 1;
BA_ "U_B515_MCA_MY17_Diesel_Tx" SG_ 131 CcAslButtnSetPress 1;
BA_ "U_B479_MY17_Diesel_Tx" SG_ 131 CcAslButtnSetPress 1;
BA_ "U_B479_MY17_Gas_Tx" SG_ 131 CcAslButtnSetPress 1;
BA_ "GenSigSendType" SG_ 131 CcAslButtnSetPress 3;
BA_ "GenSigTimeoutTime_GWM" SG_ 131 CcAslButtnSetIncPress 300;
BA_ "U_U611_U625_MY20_Phev_Tx" SG_ 131 CcAslButtnSetIncPress 1;
BA_ "U_CX482_CX483_MY20_Hev_Tx" SG_ 131 CcAslButtnSetIncPress 1;
BA_ "U_CX482_CX483_MY20_Gas_Tx" SG_ 131 CcAslButtnSetIncPress 1;
BA_ "U_CX482_CX483_MY20_Diesel_Tx" SG_ 131 CcAslButtnSetIncPress 1;
BA_ "U_U611_U625_MY20_Hev_Tx" SG_ 131 CcAslButtnSetIncPress 1;
BA_ "U_U611_U625_MY20_Gas_Tx" SG_ 131 CcAslButtnSetIncPress 1;
BA_ "U_U611_U625_MY20_Diesel_Tx" SG_ 131 CcAslButtnSetIncPress 1;
BA_ "U_B500_MY18_Diesel_Tx" SG_ 131 CcAslButtnSetIncPress 1;
BA_ "U_B500_MY18_Gas_Tx" SG_ 131 CcAslButtnSetIncPress 1;
BA_ "U_C519_MY18_5_Gas_Tx" SG_ 131 CcAslButtnSetIncPress 1;
BA_ "U_C519_MY18_5_Diesel_Tx" SG_ 131 CcAslButtnSetIncPress 1;
BA_ "U_B515_MCA_MY17_Gas_Tx" SG_ 131 CcAslButtnSetIncPress 1;
BA_ "U_B515_MCA_MY17_Diesel_Tx" SG_ 131 CcAslButtnSetIncPress 1;
BA_ "U_B479_MY17_Diesel_Tx" SG_ 131 CcAslButtnSetIncPress 1;
BA_ "U_B479_MY17_Gas_Tx" SG_ 131 CcAslButtnSetIncPress 1;
BA_ "U_CX482_CX483_MY20_Hev_Rx" SG_ 131 CcAslButtnSetIncPress 1;
BA_ "U_CX482_CX483_MY20_Gas_Rx" SG_ 131 CcAslButtnSetIncPress 1;
BA_ "U_CX482_CX483_MY20_Diesel_Rx" SG_ 131 CcAslButtnSetIncPress 1;
BA_ "U_U611_U625_MY20_Hev_Rx" SG_ 131 CcAslButtnSetIncPress 1;
BA_ "U_U611_U625_MY20_Gas_Rx" SG_ 131 CcAslButtnSetIncPress 1;
BA_ "U_U611_U625_MY20_Diesel_Rx" SG_ 131 CcAslButtnSetIncPress 1;
BA_ "U_C519_MY18_5_Gas_Rx" SG_ 131 CcAslButtnSetIncPress 1;
BA_ "U_C519_MY18_5_Diesel_Rx" SG_ 131 CcAslButtnSetIncPress 1;
BA_ "U_B479_MY17_Diesel_Rx" SG_ 131 CcAslButtnSetIncPress 1;
BA_ "U_B479_MY17_Gas_Rx" SG_ 131 CcAslButtnSetIncPress 1;
BA_ "GenSigSendType" SG_ 131 CcAslButtnSetIncPress 3;
BA_ "GenSigTimeoutTime_GWM" SG_ 131 CcAslButtnSetDecPress 300;
BA_ "U_U611_U625_MY20_Phev_Tx" SG_ 131 CcAslButtnSetDecPress 1;
BA_ "U_CX482_CX483_MY20_Hev_Tx" SG_ 131 CcAslButtnSetDecPress 1;
BA_ "U_CX482_CX483_MY20_Gas_Tx" SG_ 131 CcAslButtnSetDecPress 1;
BA_ "U_CX482_CX483_MY20_Diesel_Tx" SG_ 131 CcAslButtnSetDecPress 1;
BA_ "U_U611_U625_MY20_Hev_Tx" SG_ 131 CcAslButtnSetDecPress 1;
BA_ "U_U611_U625_MY20_Gas_Tx" SG_ 131 CcAslButtnSetDecPress 1;
BA_ "U_U611_U625_MY20_Diesel_Tx" SG_ 131 CcAslButtnSetDecPress 1;
BA_ "U_B500_MY18_Diesel_Tx" SG_ 131 CcAslButtnSetDecPress 1;
BA_ "U_B500_MY18_Gas_Tx" SG_ 131 CcAslButtnSetDecPress 1;
BA_ "U_C519_MY18_5_Gas_Tx" SG_ 131 CcAslButtnSetDecPress 1;
BA_ "U_C519_MY18_5_Diesel_Tx" SG_ 131 CcAslButtnSetDecPress 1;
BA_ "U_B515_MCA_MY17_Gas_Tx" SG_ 131 CcAslButtnSetDecPress 1;
BA_ "U_B515_MCA_MY17_Diesel_Tx" SG_ 131 CcAslButtnSetDecPress 1;
BA_ "U_B479_MY17_Diesel_Tx" SG_ 131 CcAslButtnSetDecPress 1;
BA_ "U_B479_MY17_Gas_Tx" SG_ 131 CcAslButtnSetDecPress 1;
BA_ "U_CX482_CX483_MY20_Hev_Rx" SG_ 131 CcAslButtnSetDecPress 1;
BA_ "U_CX482_CX483_MY20_Gas_Rx" SG_ 131 CcAslButtnSetDecPress 1;
BA_ "U_CX482_CX483_MY20_Diesel_Rx" SG_ 131 CcAslButtnSetDecPress 1;
BA_ "U_U611_U625_MY20_Hev_Rx" SG_ 131 CcAslButtnSetDecPress 1;
BA_ "U_U611_U625_MY20_Gas_Rx" SG_ 131 CcAslButtnSetDecPress 1;
BA_ "U_U611_U625_MY20_Diesel_Rx" SG_ 131 CcAslButtnSetDecPress 1;
BA_ "U_C519_MY18_5_Gas_Rx" SG_ 131 CcAslButtnSetDecPress 1;
BA_ "U_C519_MY18_5_Diesel_Rx" SG_ 131 CcAslButtnSetDecPress 1;
BA_ "U_B479_MY17_Diesel_Rx" SG_ 131 CcAslButtnSetDecPress 1;
BA_ "U_B479_MY17_Gas_Rx" SG_ 131 CcAslButtnSetDecPress 1;
BA_ "GenSigSendType" SG_ 131 CcAslButtnSetDecPress 3;
BA_ "GenSigTimeoutTime_GWM" SG_ 131 CcAslButtnResIncPress 300;
BA_ "U_U611_U625_MY20_Phev_Tx" SG_ 131 CcAslButtnResIncPress 1;
BA_ "U_CX482_CX483_MY20_Hev_Tx" SG_ 131 CcAslButtnResIncPress 1;
BA_ "U_CX482_CX483_MY20_Gas_Tx" SG_ 131 CcAslButtnResIncPress 1;
BA_ "U_CX482_CX483_MY20_Diesel_Tx" SG_ 131 CcAslButtnResIncPress 1;
BA_ "U_U611_U625_MY20_Hev_Tx" SG_ 131 CcAslButtnResIncPress 1;
BA_ "U_U611_U625_MY20_Gas_Tx" SG_ 131 CcAslButtnResIncPress 1;
BA_ "U_U611_U625_MY20_Diesel_Tx" SG_ 131 CcAslButtnResIncPress 1;
BA_ "U_B500_MY18_Diesel_Tx" SG_ 131 CcAslButtnResIncPress 1;
BA_ "U_B500_MY18_Gas_Tx" SG_ 131 CcAslButtnResIncPress 1;
BA_ "U_C519_MY18_5_Gas_Tx" SG_ 131 CcAslButtnResIncPress 1;
BA_ "U_C519_MY18_5_Diesel_Tx" SG_ 131 CcAslButtnResIncPress 1;
BA_ "U_B515_MCA_MY17_Gas_Tx" SG_ 131 CcAslButtnResIncPress 1;
BA_ "U_B515_MCA_MY17_Diesel_Tx" SG_ 131 CcAslButtnResIncPress 1;
BA_ "U_B479_MY17_Diesel_Tx" SG_ 131 CcAslButtnResIncPress 1;
BA_ "U_B479_MY17_Gas_Tx" SG_ 131 CcAslButtnResIncPress 1;
BA_ "U_CX482_CX483_MY20_Hev_Rx" SG_ 131 CcAslButtnResIncPress 1;
BA_ "U_CX482_CX483_MY20_Gas_Rx" SG_ 131 CcAslButtnResIncPress 1;
BA_ "U_CX482_CX483_MY20_Diesel_Rx" SG_ 131 CcAslButtnResIncPress 1;
BA_ "U_U611_U625_MY20_Hev_Rx" SG_ 131 CcAslButtnResIncPress 1;
BA_ "U_U611_U625_MY20_Gas_Rx" SG_ 131 CcAslButtnResIncPress 1;
BA_ "U_U611_U625_MY20_Diesel_Rx" SG_ 131 CcAslButtnResIncPress 1;
BA_ "U_C519_MY18_5_Gas_Rx" SG_ 131 CcAslButtnResIncPress 1;
BA_ "U_C519_MY18_5_Diesel_Rx" SG_ 131 CcAslButtnResIncPress 1;
BA_ "U_B479_MY17_Diesel_Rx" SG_ 131 CcAslButtnResIncPress 1;
BA_ "U_B479_MY17_Gas_Rx" SG_ 131 CcAslButtnResIncPress 1;
BA_ "GenSigSendType" SG_ 131 CcAslButtnResIncPress 3;
BA_ "GenSigTimeoutTime_GWM" SG_ 131 CcAslButtnResDecPress 300;
BA_ "U_U611_U625_MY20_Phev_Tx" SG_ 131 CcAslButtnResDecPress 1;
BA_ "U_CX482_CX483_MY20_Hev_Tx" SG_ 131 CcAslButtnResDecPress 1;
BA_ "U_CX482_CX483_MY20_Gas_Tx" SG_ 131 CcAslButtnResDecPress 1;
BA_ "U_CX482_CX483_MY20_Diesel_Tx" SG_ 131 CcAslButtnResDecPress 1;
BA_ "U_U611_U625_MY20_Hev_Tx" SG_ 131 CcAslButtnResDecPress 1;
BA_ "U_U611_U625_MY20_Gas_Tx" SG_ 131 CcAslButtnResDecPress 1;
BA_ "U_U611_U625_MY20_Diesel_Tx" SG_ 131 CcAslButtnResDecPress 1;
BA_ "U_B500_MY18_Diesel_Tx" SG_ 131 CcAslButtnResDecPress 1;
BA_ "U_B500_MY18_Gas_Tx" SG_ 131 CcAslButtnResDecPress 1;
BA_ "U_C519_MY18_5_Gas_Tx" SG_ 131 CcAslButtnResDecPress 1;
BA_ "U_C519_MY18_5_Diesel_Tx" SG_ 131 CcAslButtnResDecPress 1;
BA_ "U_B515_MCA_MY17_Gas_Tx" SG_ 131 CcAslButtnResDecPress 1;
BA_ "U_B515_MCA_MY17_Diesel_Tx" SG_ 131 CcAslButtnResDecPress 1;
BA_ "U_B479_MY17_Diesel_Tx" SG_ 131 CcAslButtnResDecPress 1;
BA_ "U_B479_MY17_Gas_Tx" SG_ 131 CcAslButtnResDecPress 1;
BA_ "GenSigSendType" SG_ 131 CcAslButtnResDecPress 3;
BA_ "GenSigTimeoutTime_GWM" SG_ 131 CcAslButtnOnPress 300;
BA_ "U_U611_U625_MY20_Phev_Tx" SG_ 131 CcAslButtnOnPress 1;
BA_ "U_CX482_CX483_MY20_Hev_Tx" SG_ 131 CcAslButtnOnPress 1;
BA_ "U_CX482_CX483_MY20_Gas_Tx" SG_ 131 CcAslButtnOnPress 1;
BA_ "U_CX482_CX483_MY20_Diesel_Tx" SG_ 131 CcAslButtnOnPress 1;
BA_ "U_U611_U625_MY20_Hev_Tx" SG_ 131 CcAslButtnOnPress 1;
BA_ "U_U611_U625_MY20_Gas_Tx" SG_ 131 CcAslButtnOnPress 1;
BA_ "U_U611_U625_MY20_Diesel_Tx" SG_ 131 CcAslButtnOnPress 1;
BA_ "U_B500_MY18_Diesel_Tx" SG_ 131 CcAslButtnOnPress 1;
BA_ "U_B500_MY18_Gas_Tx" SG_ 131 CcAslButtnOnPress 1;
BA_ "U_C519_MY18_5_Gas_Tx" SG_ 131 CcAslButtnOnPress 1;
BA_ "U_C519_MY18_5_Diesel_Tx" SG_ 131 CcAslButtnOnPress 1;
BA_ "U_B515_MCA_MY17_Gas_Tx" SG_ 131 CcAslButtnOnPress 1;
BA_ "U_B515_MCA_MY17_Diesel_Tx" SG_ 131 CcAslButtnOnPress 1;
BA_ "U_B479_MY17_Diesel_Tx" SG_ 131 CcAslButtnOnPress 1;
BA_ "U_B479_MY17_Gas_Tx" SG_ 131 CcAslButtnOnPress 1;
BA_ "U_U611_U625_MY20_Hev_Rx" SG_ 131 CcAslButtnOnPress 1;
BA_ "GenSigSendType" SG_ 131 CcAslButtnOnPress 3;
BA_ "GenSigTimeoutTime_GWM" SG_ 131 CcAslButtnOnOffCncl 300;
BA_ "U_U611_U625_MY20_Phev_Tx" SG_ 131 CcAslButtnOnOffCncl 1;
BA_ "U_CX482_CX483_MY20_Hev_Tx" SG_ 131 CcAslButtnOnOffCncl 1;
BA_ "U_CX482_CX483_MY20_Gas_Tx" SG_ 131 CcAslButtnOnOffCncl 1;
BA_ "U_CX482_CX483_MY20_Diesel_Tx" SG_ 131 CcAslButtnOnOffCncl 1;
BA_ "U_U611_U625_MY20_Hev_Tx" SG_ 131 CcAslButtnOnOffCncl 1;
BA_ "U_U611_U625_MY20_Gas_Tx" SG_ 131 CcAslButtnOnOffCncl 1;
BA_ "U_U611_U625_MY20_Diesel_Tx" SG_ 131 CcAslButtnOnOffCncl 1;
BA_ "U_B500_MY18_Diesel_Tx" SG_ 131 CcAslButtnOnOffCncl 1;
BA_ "U_B500_MY18_Gas_Tx" SG_ 131 CcAslButtnOnOffCncl 1;
BA_ "U_C519_MY18_5_Gas_Tx" SG_ 131 CcAslButtnOnOffCncl 1;
BA_ "U_C519_MY18_5_Diesel_Tx" SG_ 131 CcAslButtnOnOffCncl 1;
BA_ "U_B515_MCA_MY17_Gas_Tx" SG_ 131 CcAslButtnOnOffCncl 1;
BA_ "U_B515_MCA_MY17_Diesel_Tx" SG_ 131 CcAslButtnOnOffCncl 1;
BA_ "U_B479_MY17_Diesel_Tx" SG_ 131 CcAslButtnOnOffCncl 1;
BA_ "U_B479_MY17_Gas_Tx" SG_ 131 CcAslButtnOnOffCncl 1;
BA_ "GenSigSendType" SG_ 131 CcAslButtnOnOffCncl 3;
BA_ "GenSigTimeoutTime_GWM" SG_ 131 CcAslButtnOffCnclPress 300;
BA_ "U_U611_U625_MY20_Phev_Tx" SG_ 131 CcAslButtnOffCnclPress 1;
BA_ "U_CX482_CX483_MY20_Hev_Tx" SG_ 131 CcAslButtnOffCnclPress 1;
BA_ "U_CX482_CX483_MY20_Gas_Tx" SG_ 131 CcAslButtnOffCnclPress 1;
BA_ "U_CX482_CX483_MY20_Diesel_Tx" SG_ 131 CcAslButtnOffCnclPress 1;
BA_ "U_U611_U625_MY20_Hev_Tx" SG_ 131 CcAslButtnOffCnclPress 1;
BA_ "U_U611_U625_MY20_Gas_Tx" SG_ 131 CcAslButtnOffCnclPress 1;
BA_ "U_U611_U625_MY20_Diesel_Tx" SG_ 131 CcAslButtnOffCnclPress 1;
BA_ "U_B500_MY18_Diesel_Tx" SG_ 131 CcAslButtnOffCnclPress 1;
BA_ "U_B500_MY18_Gas_Tx" SG_ 131 CcAslButtnOffCnclPress 1;
BA_ "U_C519_MY18_5_Gas_Tx" SG_ 131 CcAslButtnOffCnclPress 1;
BA_ "U_C519_MY18_5_Diesel_Tx" SG_ 131 CcAslButtnOffCnclPress 1;
BA_ "U_B515_MCA_MY17_Gas_Tx" SG_ 131 CcAslButtnOffCnclPress 1;
BA_ "U_B515_MCA_MY17_Diesel_Tx" SG_ 131 CcAslButtnOffCnclPress 1;
BA_ "U_B479_MY17_Diesel_Tx" SG_ 131 CcAslButtnOffCnclPress 1;
BA_ "U_B479_MY17_Gas_Tx" SG_ 131 CcAslButtnOffCnclPress 1;
BA_ "GenSigSendType" SG_ 131 CcAslButtnOffCnclPress 3;
BA_ "GenSigTimeoutTime_GWM" SG_ 131 CcAslButtnIndxIncPress 300;
BA_ "U_U611_U625_MY20_Phev_Tx" SG_ 131 CcAslButtnIndxIncPress 1;
BA_ "U_CX482_CX483_MY20_Hev_Tx" SG_ 131 CcAslButtnIndxIncPress 1;
BA_ "U_CX482_CX483_MY20_Gas_Tx" SG_ 131 CcAslButtnIndxIncPress 1;
BA_ "U_CX482_CX483_MY20_Diesel_Tx" SG_ 131 CcAslButtnIndxIncPress 1;
BA_ "U_U611_U625_MY20_Hev_Tx" SG_ 131 CcAslButtnIndxIncPress 1;
BA_ "U_U611_U625_MY20_Gas_Tx" SG_ 131 CcAslButtnIndxIncPress 1;
BA_ "U_U611_U625_MY20_Diesel_Tx" SG_ 131 CcAslButtnIndxIncPress 1;
BA_ "U_B500_MY18_Diesel_Tx" SG_ 131 CcAslButtnIndxIncPress 1;
BA_ "U_B500_MY18_Gas_Tx" SG_ 131 CcAslButtnIndxIncPress 1;
BA_ "U_C519_MY18_5_Gas_Tx" SG_ 131 CcAslButtnIndxIncPress 1;
BA_ "U_C519_MY18_5_Diesel_Tx" SG_ 131 CcAslButtnIndxIncPress 1;
BA_ "U_B515_MCA_MY17_Gas_Tx" SG_ 131 CcAslButtnIndxIncPress 1;
BA_ "U_B515_MCA_MY17_Diesel_Tx" SG_ 131 CcAslButtnIndxIncPress 1;
BA_ "U_B479_MY17_Diesel_Tx" SG_ 131 CcAslButtnIndxIncPress 1;
BA_ "U_B479_MY17_Gas_Tx" SG_ 131 CcAslButtnIndxIncPress 1;
BA_ "GenSigSendType" SG_ 131 CcAslButtnIndxIncPress 3;
BA_ "GenSigTimeoutTime_GWM" SG_ 131 CcAslButtnIndxDecPress 300;
BA_ "U_U611_U625_MY20_Phev_Tx" SG_ 131 CcAslButtnIndxDecPress 1;
BA_ "U_CX482_CX483_MY20_Hev_Tx" SG_ 131 CcAslButtnIndxDecPress 1;
BA_ "U_CX482_CX483_MY20_Gas_Tx" SG_ 131 CcAslButtnIndxDecPress 1;
BA_ "U_CX482_CX483_MY20_Diesel_Tx" SG_ 131 CcAslButtnIndxDecPress 1;
BA_ "U_U611_U625_MY20_Hev_Tx" SG_ 131 CcAslButtnIndxDecPress 1;
BA_ "U_U611_U625_MY20_Gas_Tx" SG_ 131 CcAslButtnIndxDecPress 1;
BA_ "U_U611_U625_MY20_Diesel_Tx" SG_ 131 CcAslButtnIndxDecPress 1;
BA_ "U_B500_MY18_Diesel_Tx" SG_ 131 CcAslButtnIndxDecPress 1;
BA_ "U_B500_MY18_Gas_Tx" SG_ 131 CcAslButtnIndxDecPress 1;
BA_ "U_C519_MY18_5_Gas_Tx" SG_ 131 CcAslButtnIndxDecPress 1;
BA_ "U_C519_MY18_5_Diesel_Tx" SG_ 131 CcAslButtnIndxDecPress 1;
BA_ "U_B515_MCA_MY17_Gas_Tx" SG_ 131 CcAslButtnIndxDecPress 1;
BA_ "U_B515_MCA_MY17_Diesel_Tx" SG_ 131 CcAslButtnIndxDecPress 1;
BA_ "U_B479_MY17_Diesel_Tx" SG_ 131 CcAslButtnIndxDecPress 1;
BA_ "U_B479_MY17_Gas_Tx" SG_ 131 CcAslButtnIndxDecPress 1;
BA_ "GenSigSendType" SG_ 131 CcAslButtnIndxDecPress 3;
BA_ "GenSigTimeoutTime_GWM" SG_ 131 CcAslButtnDeny_B_Actl 300;
BA_ "U_U611_U625_MY20_Phev_Tx" SG_ 131 CcAslButtnDeny_B_Actl 1;
BA_ "U_CX482_CX483_MY20_Hev_Tx" SG_ 131 CcAslButtnDeny_B_Actl 1;
BA_ "U_CX482_CX483_MY20_Gas_Tx" SG_ 131 CcAslButtnDeny_B_Actl 1;
BA_ "U_CX482_CX483_MY20_Diesel_Tx" SG_ 131 CcAslButtnDeny_B_Actl 1;
BA_ "U_U611_U625_MY20_Hev_Tx" SG_ 131 CcAslButtnDeny_B_Actl 1;
BA_ "U_U611_U625_MY20_Gas_Tx" SG_ 131 CcAslButtnDeny_B_Actl 1;
BA_ "U_U611_U625_MY20_Diesel_Tx" SG_ 131 CcAslButtnDeny_B_Actl 1;
BA_ "U_B500_MY18_Diesel_Tx" SG_ 131 CcAslButtnDeny_B_Actl 1;
BA_ "U_B500_MY18_Gas_Tx" SG_ 131 CcAslButtnDeny_B_Actl 1;
BA_ "U_C519_MY18_5_Gas_Tx" SG_ 131 CcAslButtnDeny_B_Actl 1;
BA_ "U_C519_MY18_5_Diesel_Tx" SG_ 131 CcAslButtnDeny_B_Actl 1;
BA_ "U_B515_MCA_MY17_Gas_Tx" SG_ 131 CcAslButtnDeny_B_Actl 1;
BA_ "U_B515_MCA_MY17_Diesel_Tx" SG_ 131 CcAslButtnDeny_B_Actl 1;
BA_ "U_B479_MY17_Diesel_Tx" SG_ 131 CcAslButtnDeny_B_Actl 1;
BA_ "U_B479_MY17_Gas_Tx" SG_ 131 CcAslButtnDeny_B_Actl 1;
BA_ "U_CX482_CX483_MY20_Hev_Rx" SG_ 131 CcAslButtnDeny_B_Actl 1;
BA_ "U_CX482_CX483_MY20_Gas_Rx" SG_ 131 CcAslButtnDeny_B_Actl 1;
BA_ "U_CX482_CX483_MY20_Diesel_Rx" SG_ 131 CcAslButtnDeny_B_Actl 1;
BA_ "U_U611_U625_MY20_Hev_Rx" SG_ 131 CcAslButtnDeny_B_Actl 1;
BA_ "U_U611_U625_MY20_Gas_Rx" SG_ 131 CcAslButtnDeny_B_Actl 1;
BA_ "U_U611_U625_MY20_Diesel_Rx" SG_ 131 CcAslButtnDeny_B_Actl 1;
BA_ "U_C519_MY18_5_Gas_Rx" SG_ 131 CcAslButtnDeny_B_Actl 1;
BA_ "U_C519_MY18_5_Diesel_Rx" SG_ 131 CcAslButtnDeny_B_Actl 1;
BA_ "U_B479_MY17_Diesel_Rx" SG_ 131 CcAslButtnDeny_B_Actl 1;
BA_ "U_B479_MY17_Gas_Rx" SG_ 131 CcAslButtnDeny_B_Actl 1;
BA_ "GenSigSendType" SG_ 131 CcAslButtnDeny_B_Actl 3;
BA_ "GenSigTimeoutTime_GWM" SG_ 131 CcAslButtnCnclResPress 300;
BA_ "U_U611_U625_MY20_Phev_Tx" SG_ 131 CcAslButtnCnclResPress 1;
BA_ "U_CX482_CX483_MY20_Hev_Tx" SG_ 131 CcAslButtnCnclResPress 1;
BA_ "U_CX482_CX483_MY20_Gas_Tx" SG_ 131 CcAslButtnCnclResPress 1;
BA_ "U_CX482_CX483_MY20_Diesel_Tx" SG_ 131 CcAslButtnCnclResPress 1;
BA_ "U_U611_U625_MY20_Hev_Tx" SG_ 131 CcAslButtnCnclResPress 1;
BA_ "U_U611_U625_MY20_Gas_Tx" SG_ 131 CcAslButtnCnclResPress 1;
BA_ "U_U611_U625_MY20_Diesel_Tx" SG_ 131 CcAslButtnCnclResPress 1;
BA_ "U_B500_MY18_Diesel_Tx" SG_ 131 CcAslButtnCnclResPress 1;
BA_ "U_B500_MY18_Gas_Tx" SG_ 131 CcAslButtnCnclResPress 1;
BA_ "U_C519_MY18_5_Gas_Tx" SG_ 131 CcAslButtnCnclResPress 1;
BA_ "U_C519_MY18_5_Diesel_Tx" SG_ 131 CcAslButtnCnclResPress 1;
BA_ "U_B515_MCA_MY17_Gas_Tx" SG_ 131 CcAslButtnCnclResPress 1;
BA_ "U_B515_MCA_MY17_Diesel_Tx" SG_ 131 CcAslButtnCnclResPress 1;
BA_ "U_B479_MY17_Diesel_Tx" SG_ 131 CcAslButtnCnclResPress 1;
BA_ "U_B479_MY17_Gas_Tx" SG_ 131 CcAslButtnCnclResPress 1;
BA_ "U_CX482_CX483_MY20_Hev_Rx" SG_ 131 CcAslButtnCnclResPress 1;
BA_ "U_CX482_CX483_MY20_Gas_Rx" SG_ 131 CcAslButtnCnclResPress 1;
BA_ "U_CX482_CX483_MY20_Diesel_Rx" SG_ 131 CcAslButtnCnclResPress 1;
BA_ "U_U611_U625_MY20_Hev_Rx" SG_ 131 CcAslButtnCnclResPress 1;
BA_ "U_U611_U625_MY20_Gas_Rx" SG_ 131 CcAslButtnCnclResPress 1;
BA_ "U_U611_U625_MY20_Diesel_Rx" SG_ 131 CcAslButtnCnclResPress 1;
BA_ "U_C519_MY18_5_Gas_Rx" SG_ 131 CcAslButtnCnclResPress 1;
BA_ "U_C519_MY18_5_Diesel_Rx" SG_ 131 CcAslButtnCnclResPress 1;
BA_ "U_B479_MY17_Diesel_Rx" SG_ 131 CcAslButtnCnclResPress 1;
BA_ "U_B479_MY17_Gas_Rx" SG_ 131 CcAslButtnCnclResPress 1;
BA_ "GenSigSendType" SG_ 131 CcAslButtnCnclResPress 3;
BA_ "GenSigTimeoutTime_GWM" SG_ 131 CcAslButtnCnclPress 300;
BA_ "U_U611_U625_MY20_Phev_Tx" SG_ 131 CcAslButtnCnclPress 1;
BA_ "U_CX482_CX483_MY20_Hev_Tx" SG_ 131 CcAslButtnCnclPress 1;
BA_ "U_CX482_CX483_MY20_Gas_Tx" SG_ 131 CcAslButtnCnclPress 1;
BA_ "U_CX482_CX483_MY20_Diesel_Tx" SG_ 131 CcAslButtnCnclPress 1;
BA_ "U_U611_U625_MY20_Hev_Tx" SG_ 131 CcAslButtnCnclPress 1;
BA_ "U_U611_U625_MY20_Gas_Tx" SG_ 131 CcAslButtnCnclPress 1;
BA_ "U_U611_U625_MY20_Diesel_Tx" SG_ 131 CcAslButtnCnclPress 1;
BA_ "U_B500_MY18_Diesel_Tx" SG_ 131 CcAslButtnCnclPress 1;
BA_ "U_B500_MY18_Gas_Tx" SG_ 131 CcAslButtnCnclPress 1;
BA_ "U_C519_MY18_5_Gas_Tx" SG_ 131 CcAslButtnCnclPress 1;
BA_ "U_C519_MY18_5_Diesel_Tx" SG_ 131 CcAslButtnCnclPress 1;
BA_ "U_B515_MCA_MY17_Gas_Tx" SG_ 131 CcAslButtnCnclPress 1;
BA_ "U_B515_MCA_MY17_Diesel_Tx" SG_ 131 CcAslButtnCnclPress 1;
BA_ "U_B479_MY17_Diesel_Tx" SG_ 131 CcAslButtnCnclPress 1;
BA_ "U_B479_MY17_Gas_Tx" SG_ 131 CcAslButtnCnclPress 1;
BA_ "U_CX482_CX483_MY20_Hev_Rx" SG_ 131 CcAslButtnCnclPress 1;
BA_ "U_CX482_CX483_MY20_Gas_Rx" SG_ 131 CcAslButtnCnclPress 1;
BA_ "U_CX482_CX483_MY20_Diesel_Rx" SG_ 131 CcAslButtnCnclPress 1;
BA_ "U_U611_U625_MY20_Hev_Rx" SG_ 131 CcAslButtnCnclPress 1;
BA_ "U_U611_U625_MY20_Gas_Rx" SG_ 131 CcAslButtnCnclPress 1;
BA_ "U_U611_U625_MY20_Diesel_Rx" SG_ 131 CcAslButtnCnclPress 1;
BA_ "U_C519_MY18_5_Gas_Rx" SG_ 131 CcAslButtnCnclPress 1;
BA_ "U_C519_MY18_5_Diesel_Rx" SG_ 131 CcAslButtnCnclPress 1;
BA_ "U_B479_MY17_Diesel_Rx" SG_ 131 CcAslButtnCnclPress 1;
BA_ "U_B479_MY17_Gas_Rx" SG_ 131 CcAslButtnCnclPress 1;
BA_ "GenSigSendType" SG_ 131 CcAslButtnCnclPress 3;
BA_ "GenSigTimeoutTime_GWM" SG_ 131 LaSwtchPos_D_Stat 300;
BA_ "U_U611_U625_MY20_Phev_Tx" SG_ 131 LaSwtchPos_D_Stat 1;
BA_ "U_CX482_CX483_MY20_Hev_Tx" SG_ 131 LaSwtchPos_D_Stat 1;
BA_ "U_CX482_CX483_MY20_Gas_Tx" SG_ 131 LaSwtchPos_D_Stat 1;
BA_ "U_CX482_CX483_MY20_Diesel_Tx" SG_ 131 LaSwtchPos_D_Stat 1;
BA_ "U_U611_U625_MY20_Hev_Tx" SG_ 131 LaSwtchPos_D_Stat 1;
BA_ "U_U611_U625_MY20_Gas_Tx" SG_ 131 LaSwtchPos_D_Stat 1;
BA_ "U_U611_U625_MY20_Diesel_Tx" SG_ 131 LaSwtchPos_D_Stat 1;
BA_ "U_B500_MY18_Diesel_Tx" SG_ 131 LaSwtchPos_D_Stat 1;
BA_ "U_B500_MY18_Gas_Tx" SG_ 131 LaSwtchPos_D_Stat 1;
BA_ "U_C519_MY18_5_Gas_Tx" SG_ 131 LaSwtchPos_D_Stat 1;
BA_ "U_C519_MY18_5_Diesel_Tx" SG_ 131 LaSwtchPos_D_Stat 1;
BA_ "U_B515_MCA_MY17_Gas_Tx" SG_ 131 LaSwtchPos_D_Stat 1;
BA_ "U_B515_MCA_MY17_Diesel_Tx" SG_ 131 LaSwtchPos_D_Stat 1;
BA_ "U_B479_MY17_Diesel_Tx" SG_ 131 LaSwtchPos_D_Stat 1;
BA_ "U_B479_MY17_Gas_Tx" SG_ 131 LaSwtchPos_D_Stat 1;
BA_ "U_CX482_CX483_MY20_Hev_Rx" SG_ 131 LaSwtchPos_D_Stat 1;
BA_ "U_CX482_CX483_MY20_Gas_Rx" SG_ 131 LaSwtchPos_D_Stat 1;
BA_ "U_CX482_CX483_MY20_Diesel_Rx" SG_ 131 LaSwtchPos_D_Stat 1;
BA_ "U_U611_U625_MY20_Hev_Rx" SG_ 131 LaSwtchPos_D_Stat 1;
BA_ "U_U611_U625_MY20_Gas_Rx" SG_ 131 LaSwtchPos_D_Stat 1;
BA_ "U_U611_U625_MY20_Diesel_Rx" SG_ 131 LaSwtchPos_D_Stat 1;
BA_ "U_C519_MY18_5_Gas_Rx" SG_ 131 LaSwtchPos_D_Stat 1;
BA_ "U_C519_MY18_5_Diesel_Rx" SG_ 131 LaSwtchPos_D_Stat 1;
BA_ "U_B479_MY17_Diesel_Rx" SG_ 131 LaSwtchPos_D_Stat 1;
BA_ "U_B479_MY17_Gas_Rx" SG_ 131 LaSwtchPos_D_Stat 1;
BA_ "GenSigSendType" SG_ 131 LaSwtchPos_D_Stat 3;
BA_ "U_U611_U625_MY20_Phev_Rx" SG_ 992 MsgCntrPersIndex_D_Rq 1;
BA_ "U_CX482_CX483_MY20_Hev_Rx" SG_ 992 MsgCntrPersIndex_D_Rq 1;
BA_ "U_CX482_CX483_MY20_Gas_Rx" SG_ 992 MsgCntrPersIndex_D_Rq 1;
BA_ "U_CX482_CX483_MY20_Diesel_Rx" SG_ 992 MsgCntrPersIndex_D_Rq 1;
BA_ "U_U611_U625_MY20_Hev_Rx" SG_ 992 MsgCntrPersIndex_D_Rq 1;
BA_ "U_U611_U625_MY20_Gas_Rx" SG_ 992 MsgCntrPersIndex_D_Rq 1;
BA_ "U_U611_U625_MY20_Diesel_Rx" SG_ 992 MsgCntrPersIndex_D_Rq 1;
BA_ "U_B500_MY18_Diesel_Rx" SG_ 992 MsgCntrPersIndex_D_Rq 1;
BA_ "U_B500_MY18_Gas_Rx" SG_ 992 MsgCntrPersIndex_D_Rq 1;
BA_ "U_C519_MY18_5_Gas_Rx" SG_ 992 MsgCntrPersIndex_D_Rq 1;
BA_ "U_C519_MY18_5_Diesel_Rx" SG_ 992 MsgCntrPersIndex_D_Rq 1;
BA_ "U_B515_MCA_MY17_Gas_Rx" SG_ 992 MsgCntrPersIndex_D_Rq 1;
BA_ "U_B515_MCA_MY17_Diesel_Rx" SG_ 992 MsgCntrPersIndex_D_Rq 1;
BA_ "GenSigStartValue" SG_ 992 MsgCntrPersIndex_D_Rq 4;
BA_ "CrossOver_InfoCAN" SG_ 992 MsgCntrPersIndex_D_Rq 1;
BA_ "U_U611_U625_MY20_Phev_Rx" SG_ 992 MsgCntrFeatConfigRq 1;
BA_ "U_CX482_CX483_MY20_Hev_Rx" SG_ 992 MsgCntrFeatConfigRq 1;
BA_ "U_CX482_CX483_MY20_Gas_Rx" SG_ 992 MsgCntrFeatConfigRq 1;
BA_ "U_CX482_CX483_MY20_Diesel_Rx" SG_ 992 MsgCntrFeatConfigRq 1;
BA_ "U_U611_U625_MY20_Hev_Rx" SG_ 992 MsgCntrFeatConfigRq 1;
BA_ "U_U611_U625_MY20_Gas_Rx" SG_ 992 MsgCntrFeatConfigRq 1;
BA_ "U_U611_U625_MY20_Diesel_Rx" SG_ 992 MsgCntrFeatConfigRq 1;
BA_ "U_B500_MY18_Diesel_Rx" SG_ 992 MsgCntrFeatConfigRq 1;
BA_ "U_B500_MY18_Gas_Rx" SG_ 992 MsgCntrFeatConfigRq 1;
BA_ "U_C519_MY18_5_Gas_Rx" SG_ 992 MsgCntrFeatConfigRq 1;
BA_ "U_C519_MY18_5_Diesel_Rx" SG_ 992 MsgCntrFeatConfigRq 1;
BA_ "U_B515_MCA_MY17_Gas_Rx" SG_ 992 MsgCntrFeatConfigRq 1;
BA_ "U_B515_MCA_MY17_Diesel_Rx" SG_ 992 MsgCntrFeatConfigRq 1;
BA_ "CrossOver_InfoCAN" SG_ 992 MsgCntrFeatConfigRq 1;
BA_ "U_U611_U625_MY20_Phev_Rx" SG_ 992 MsgCntrFeatNoRq 1;
BA_ "U_CX482_CX483_MY20_Hev_Rx" SG_ 992 MsgCntrFeatNoRq 1;
BA_ "U_CX482_CX483_MY20_Gas_Rx" SG_ 992 MsgCntrFeatNoRq 1;
BA_ "U_CX482_CX483_MY20_Diesel_Rx" SG_ 992 MsgCntrFeatNoRq 1;
BA_ "U_U611_U625_MY20_Hev_Rx" SG_ 992 MsgCntrFeatNoRq 1;
BA_ "U_U611_U625_MY20_Gas_Rx" SG_ 992 MsgCntrFeatNoRq 1;
BA_ "U_U611_U625_MY20_Diesel_Rx" SG_ 992 MsgCntrFeatNoRq 1;
BA_ "U_B500_MY18_Diesel_Rx" SG_ 992 MsgCntrFeatNoRq 1;
BA_ "U_B500_MY18_Gas_Rx" SG_ 992 MsgCntrFeatNoRq 1;
BA_ "U_C519_MY18_5_Gas_Rx" SG_ 992 MsgCntrFeatNoRq 1;
BA_ "U_C519_MY18_5_Diesel_Rx" SG_ 992 MsgCntrFeatNoRq 1;
BA_ "U_B515_MCA_MY17_Gas_Rx" SG_ 992 MsgCntrFeatNoRq 1;
BA_ "U_B515_MCA_MY17_Diesel_Rx" SG_ 992 MsgCntrFeatNoRq 1;
BA_ "CrossOver_InfoCAN" SG_ 992 MsgCntrFeatNoRq 1;
BA_ "U_U611_U625_MY20_Phev_Rx" SG_ 992 MsgCntrDsplyOp_D_Rq 1;
BA_ "U_B500_MY18_Diesel_Rx" SG_ 992 MsgCntrDsplyOp_D_Rq 1;
BA_ "U_B500_MY18_Gas_Rx" SG_ 992 MsgCntrDsplyOp_D_Rq 1;
BA_ "U_B515_MCA_MY17_Gas_Rx" SG_ 992 MsgCntrDsplyOp_D_Rq 1;
BA_ "U_B515_MCA_MY17_Diesel_Rx" SG_ 992 MsgCntrDsplyOp_D_Rq 1;
BA_ "U_CX482_CX483_MY20_Hev_Rx" SG_ 992 MsgCntrDsplyOp_D_Rq 1;
BA_ "U_CX482_CX483_MY20_Gas_Rx" SG_ 992 MsgCntrDsplyOp_D_Rq 1;
BA_ "U_CX482_CX483_MY20_Diesel_Rx" SG_ 992 MsgCntrDsplyOp_D_Rq 1;
BA_ "U_U611_U625_MY20_Hev_Rx" SG_ 992 MsgCntrDsplyOp_D_Rq 1;
BA_ "U_U611_U625_MY20_Gas_Rx" SG_ 992 MsgCntrDsplyOp_D_Rq 1;
BA_ "U_U611_U625_MY20_Diesel_Rx" SG_ 992 MsgCntrDsplyOp_D_Rq 1;
BA_ "U_B479_MY17_Diesel_Rx" SG_ 992 MsgCntrDsplyOp_D_Rq 1;
BA_ "U_B479_MY17_Gas_Rx" SG_ 992 MsgCntrDsplyOp_D_Rq 1;
BA_ "U_C519_MY18_5_Gas_Rx" SG_ 992 MsgCntrDsplyOp_D_Rq 1;
BA_ "U_C519_MY18_5_Diesel_Rx" SG_ 992 MsgCntrDsplyOp_D_Rq 1;
BA_ "CrossOver_InfoCAN" SG_ 992 MsgCntrDsplyOp_D_Rq 1;
BA_ "U_U611_U625_MY20_Hev_Tx" SG_ 970 LkaActvStats_D2_Req 1;
BA_ "U_U611_U625_MY20_Gas_Tx" SG_ 970 LkaActvStats_D2_Req 1;
BA_ "U_U611_U625_MY20_Diesel_Tx" SG_ 970 LkaActvStats_D2_Req 1;
BA_ "U_CX482_CX483_MY20_Hev_Tx" SG_ 970 LaRefAng_No_Req 1;
BA_ "U_CX482_CX483_MY20_Gas_Tx" SG_ 970 LaRefAng_No_Req 1;
BA_ "U_CX482_CX483_MY20_Diesel_Tx" SG_ 970 LaRefAng_No_Req 1;
BA_ "U_U611_U625_MY20_Hev_Tx" SG_ 970 LaRefAng_No_Req 1;
BA_ "U_U611_U625_MY20_Gas_Tx" SG_ 970 LaRefAng_No_Req 1;
BA_ "U_U611_U625_MY20_Diesel_Tx" SG_ 970 LaRefAng_No_Req 1;
BA_ "U_C519_MY18_5_Gas_Tx" SG_ 970 LaRefAng_No_Req 1;
BA_ "U_C519_MY18_5_Diesel_Tx" SG_ 970 LaRefAng_No_Req 1;
BA_ "U_B479_MY17_Diesel_Tx" SG_ 970 LaRefAng_No_Req 1;
BA_ "U_B479_MY17_Gas_Tx" SG_ 970 LaRefAng_No_Req 1;
BA_ "U_U611_U625_MY20_Phev_Rx" SG_ 970 LaRefAng_No_Req 1;
BA_ "U_CX482_CX483_MY20_Hev_Rx" SG_ 970 LaRefAng_No_Req 1;
BA_ "U_CX482_CX483_MY20_Gas_Rx" SG_ 970 LaRefAng_No_Req 1;
BA_ "U_CX482_CX483_MY20_Diesel_Rx" SG_ 970 LaRefAng_No_Req 1;
BA_ "U_U611_U625_MY20_Hev_Rx" SG_ 970 LaRefAng_No_Req 1;
BA_ "U_U611_U625_MY20_Gas_Rx" SG_ 970 LaRefAng_No_Req 1;
BA_ "U_U611_U625_MY20_Diesel_Rx" SG_ 970 LaRefAng_No_Req 1;
BA_ "U_B500_MY18_Diesel_Rx" SG_ 970 LaRefAng_No_Req 1;
BA_ "U_B500_MY18_Gas_Rx" SG_ 970 LaRefAng_No_Req 1;
BA_ "U_C519_MY18_5_Gas_Rx" SG_ 970 LaRefAng_No_Req 1;
BA_ "U_C519_MY18_5_Diesel_Rx" SG_ 970 LaRefAng_No_Req 1;
BA_ "U_B479_MY17_Diesel_Rx" SG_ 970 LaRefAng_No_Req 1;
BA_ "U_B479_MY17_Gas_Rx" SG_ 970 LaRefAng_No_Req 1;
BA_ "GenSigStartValue" SG_ 970 LaRefAng_No_Req 2048;
BA_ "U_CX482_CX483_MY20_Hev_Tx" SG_ 970 LaRampType_B_Req 1;
BA_ "U_CX482_CX483_MY20_Gas_Tx" SG_ 970 LaRampType_B_Req 1;
BA_ "U_CX482_CX483_MY20_Diesel_Tx" SG_ 970 LaRampType_B_Req 1;
BA_ "U_U611_U625_MY20_Hev_Tx" SG_ 970 LaRampType_B_Req 1;
BA_ "U_U611_U625_MY20_Gas_Tx" SG_ 970 LaRampType_B_Req 1;
BA_ "U_U611_U625_MY20_Diesel_Tx" SG_ 970 LaRampType_B_Req 1;
BA_ "U_C519_MY18_5_Gas_Tx" SG_ 970 LaRampType_B_Req 1;
BA_ "U_C519_MY18_5_Diesel_Tx" SG_ 970 LaRampType_B_Req 1;
BA_ "U_B479_MY17_Diesel_Tx" SG_ 970 LaRampType_B_Req 1;
BA_ "U_B479_MY17_Gas_Tx" SG_ 970 LaRampType_B_Req 1;
BA_ "U_U611_U625_MY20_Phev_Rx" SG_ 970 LaRampType_B_Req 1;
BA_ "U_CX482_CX483_MY20_Hev_Rx" SG_ 970 LaRampType_B_Req 1;
BA_ "U_CX482_CX483_MY20_Gas_Rx" SG_ 970 LaRampType_B_Req 1;
BA_ "U_CX482_CX483_MY20_Diesel_Rx" SG_ 970 LaRampType_B_Req 1;
BA_ "U_U611_U625_MY20_Hev_Rx" SG_ 970 LaRampType_B_Req 1;
BA_ "U_U611_U625_MY20_Gas_Rx" SG_ 970 LaRampType_B_Req 1;
BA_ "U_U611_U625_MY20_Diesel_Rx" SG_ 970 LaRampType_B_Req 1;
BA_ "U_B500_MY18_Diesel_Rx" SG_ 970 LaRampType_B_Req 1;
BA_ "U_B500_MY18_Gas_Rx" SG_ 970 LaRampType_B_Req 1;
BA_ "U_C519_MY18_5_Gas_Rx" SG_ 970 LaRampType_B_Req 1;
BA_ "U_C519_MY18_5_Diesel_Rx" SG_ 970 LaRampType_B_Req 1;
BA_ "U_B479_MY17_Diesel_Rx" SG_ 970 LaRampType_B_Req 1;
BA_ "U_B479_MY17_Gas_Rx" SG_ 970 LaRampType_B_Req 1;
BA_ "U_CX482_CX483_MY20_Hev_Tx" SG_ 970 LaCurvature_No_Calc 1;
BA_ "U_CX482_CX483_MY20_Gas_Tx" SG_ 970 LaCurvature_No_Calc 1;
BA_ "U_CX482_CX483_MY20_Diesel_Tx" SG_ 970 LaCurvature_No_Calc 1;
BA_ "U_U611_U625_MY20_Hev_Tx" SG_ 970 LaCurvature_No_Calc 1;
BA_ "U_U611_U625_MY20_Gas_Tx" SG_ 970 LaCurvature_No_Calc 1;
BA_ "U_U611_U625_MY20_Diesel_Tx" SG_ 970 LaCurvature_No_Calc 1;
BA_ "U_C519_MY18_5_Gas_Tx" SG_ 970 LaCurvature_No_Calc 1;
BA_ "U_C519_MY18_5_Diesel_Tx" SG_ 970 LaCurvature_No_Calc 1;
BA_ "U_B479_MY17_Diesel_Tx" SG_ 970 LaCurvature_No_Calc 1;
BA_ "U_B479_MY17_Gas_Tx" SG_ 970 LaCurvature_No_Calc 1;
BA_ "U_U611_U625_MY20_Phev_Rx" SG_ 970 LaCurvature_No_Calc 1;
BA_ "U_CX482_CX483_MY20_Hev_Rx" SG_ 970 LaCurvature_No_Calc 1;
BA_ "U_CX482_CX483_MY20_Gas_Rx" SG_ 970 LaCurvature_No_Calc 1;
BA_ "U_CX482_CX483_MY20_Diesel_Rx" SG_ 970 LaCurvature_No_Calc 1;
BA_ "U_U611_U625_MY20_Hev_Rx" SG_ 970 LaCurvature_No_Calc 1;
BA_ "U_U611_U625_MY20_Gas_Rx" SG_ 970 LaCurvature_No_Calc 1;
BA_ "U_U611_U625_MY20_Diesel_Rx" SG_ 970 LaCurvature_No_Calc 1;
BA_ "U_B500_MY18_Diesel_Rx" SG_ 970 LaCurvature_No_Calc 1;
BA_ "U_B500_MY18_Gas_Rx" SG_ 970 LaCurvature_No_Calc 1;
BA_ "U_C519_MY18_5_Gas_Rx" SG_ 970 LaCurvature_No_Calc 1;
BA_ "U_C519_MY18_5_Diesel_Rx" SG_ 970 LaCurvature_No_Calc 1;
BA_ "U_B479_MY17_Diesel_Rx" SG_ 970 LaCurvature_No_Calc 1;
BA_ "U_B479_MY17_Gas_Rx" SG_ 970 LaCurvature_No_Calc 1;
BA_ "GenSigStartValue" SG_ 970 LaCurvature_No_Calc 2048;
BA_ "U_CX482_CX483_MY20_Hev_Tx" SG_ 970 LdwActvStats_D_Req 1;
BA_ "U_CX482_CX483_MY20_Gas_Tx" SG_ 970 LdwActvStats_D_Req 1;
BA_ "U_CX482_CX483_MY20_Diesel_Tx" SG_ 970 LdwActvStats_D_Req 1;
BA_ "U_U611_U625_MY20_Hev_Tx" SG_ 970 LdwActvStats_D_Req 1;
BA_ "U_U611_U625_MY20_Gas_Tx" SG_ 970 LdwActvStats_D_Req 1;
BA_ "U_U611_U625_MY20_Diesel_Tx" SG_ 970 LdwActvStats_D_Req 1;
BA_ "U_C519_MY18_5_Gas_Tx" SG_ 970 LdwActvStats_D_Req 1;
BA_ "U_C519_MY18_5_Diesel_Tx" SG_ 970 LdwActvStats_D_Req 1;
BA_ "U_B479_MY17_Diesel_Tx" SG_ 970 LdwActvStats_D_Req 1;
BA_ "U_B479_MY17_Gas_Tx" SG_ 970 LdwActvStats_D_Req 1;
BA_ "U_U611_U625_MY20_Phev_Rx" SG_ 970 LdwActvStats_D_Req 1;
BA_ "U_CX482_CX483_MY20_Hev_Rx" SG_ 970 LdwActvStats_D_Req 1;
BA_ "U_CX482_CX483_MY20_Gas_Rx" SG_ 970 LdwActvStats_D_Req 1;
BA_ "U_CX482_CX483_MY20_Diesel_Rx" SG_ 970 LdwActvStats_D_Req 1;
BA_ "U_U611_U625_MY20_Hev_Rx" SG_ 970 LdwActvStats_D_Req 1;
BA_ "U_U611_U625_MY20_Gas_Rx" SG_ 970 LdwActvStats_D_Req 1;
BA_ "U_U611_U625_MY20_Diesel_Rx" SG_ 970 LdwActvStats_D_Req 1;
BA_ "U_B500_MY18_Diesel_Rx" SG_ 970 LdwActvStats_D_Req 1;
BA_ "U_B500_MY18_Gas_Rx" SG_ 970 LdwActvStats_D_Req 1;
BA_ "U_C519_MY18_5_Gas_Rx" SG_ 970 LdwActvStats_D_Req 1;
BA_ "U_C519_MY18_5_Diesel_Rx" SG_ 970 LdwActvStats_D_Req 1;
BA_ "U_B479_MY17_Diesel_Rx" SG_ 970 LdwActvStats_D_Req 1;
BA_ "U_B479_MY17_Gas_Rx" SG_ 970 LdwActvStats_D_Req 1;
BA_ "U_CX482_CX483_MY20_Hev_Tx" SG_ 970 LdwActvIntns_D_Req 1;
BA_ "U_CX482_CX483_MY20_Gas_Tx" SG_ 970 LdwActvIntns_D_Req 1;
BA_ "U_CX482_CX483_MY20_Diesel_Tx" SG_ 970 LdwActvIntns_D_Req 1;
BA_ "U_U611_U625_MY20_Hev_Tx" SG_ 970 LdwActvIntns_D_Req 1;
BA_ "U_U611_U625_MY20_Gas_Tx" SG_ 970 LdwActvIntns_D_Req 1;
BA_ "U_U611_U625_MY20_Diesel_Tx" SG_ 970 LdwActvIntns_D_Req 1;
BA_ "U_C519_MY18_5_Gas_Tx" SG_ 970 LdwActvIntns_D_Req 1;
BA_ "U_C519_MY18_5_Diesel_Tx" SG_ 970 LdwActvIntns_D_Req 1;
BA_ "U_B479_MY17_Diesel_Tx" SG_ 970 LdwActvIntns_D_Req 1;
BA_ "U_B479_MY17_Gas_Tx" SG_ 970 LdwActvIntns_D_Req 1;
BA_ "U_U611_U625_MY20_Phev_Rx" SG_ 970 LdwActvIntns_D_Req 1;
BA_ "U_CX482_CX483_MY20_Hev_Rx" SG_ 970 LdwActvIntns_D_Req 1;
BA_ "U_CX482_CX483_MY20_Gas_Rx" SG_ 970 LdwActvIntns_D_Req 1;
BA_ "U_CX482_CX483_MY20_Diesel_Rx" SG_ 970 LdwActvIntns_D_Req 1;
BA_ "U_U611_U625_MY20_Hev_Rx" SG_ 970 LdwActvIntns_D_Req 1;
BA_ "U_U611_U625_MY20_Gas_Rx" SG_ 970 LdwActvIntns_D_Req 1;
BA_ "U_U611_U625_MY20_Diesel_Rx" SG_ 970 LdwActvIntns_D_Req 1;
BA_ "U_B500_MY18_Diesel_Rx" SG_ 970 LdwActvIntns_D_Req 1;
BA_ "U_B500_MY18_Gas_Rx" SG_ 970 LdwActvIntns_D_Req 1;
BA_ "U_C519_MY18_5_Gas_Rx" SG_ 970 LdwActvIntns_D_Req 1;
BA_ "U_C519_MY18_5_Diesel_Rx" SG_ 970 LdwActvIntns_D_Req 1;
BA_ "U_B479_MY17_Diesel_Rx" SG_ 970 LdwActvIntns_D_Req 1;
BA_ "U_B479_MY17_Gas_Rx" SG_ 970 LdwActvIntns_D_Req 1;
BA_ "CrossOver_InfoCAN" SG_ 970 LdwActvIntns_D_Req 1;
BA_ "U_CX482_CX483_MY20_Hev_Tx" SG_ 1806 TesterPhysicalResIPMA 1;
BA_ "U_CX482_CX483_MY20_Gas_Tx" SG_ 1806 TesterPhysicalResIPMA 1;
BA_ "U_CX482_CX483_MY20_Diesel_Tx" SG_ 1806 TesterPhysicalResIPMA 1;
BA_ "U_U611_U625_MY20_Hev_Tx" SG_ 1806 TesterPhysicalResIPMA 1;
BA_ "U_U611_U625_MY20_Gas_Tx" SG_ 1806 TesterPhysicalResIPMA 1;
BA_ "U_U611_U625_MY20_Diesel_Tx" SG_ 1806 TesterPhysicalResIPMA 1;
BA_ "U_C519_MY18_5_Gas_Tx" SG_ 1806 TesterPhysicalResIPMA 1;
BA_ "U_C519_MY18_5_Diesel_Tx" SG_ 1806 TesterPhysicalResIPMA 1;
BA_ "U_B479_MY17_Diesel_Tx" SG_ 1806 TesterPhysicalResIPMA 1;
BA_ "U_B479_MY17_Gas_Tx" SG_ 1806 TesterPhysicalResIPMA 1;
BA_ "GenSigSendType" SG_ 1806 TesterPhysicalResIPMA 3;
BA_ "U_CX482_CX483_MY20_Hev_Rx" SG_ 1798 TesterPhysicalReqIPMA 1;
BA_ "U_CX482_CX483_MY20_Gas_Rx" SG_ 1798 TesterPhysicalReqIPMA 1;
BA_ "U_CX482_CX483_MY20_Diesel_Rx" SG_ 1798 TesterPhysicalReqIPMA 1;
BA_ "U_U611_U625_MY20_Hev_Rx" SG_ 1798 TesterPhysicalReqIPMA 1;
BA_ "U_U611_U625_MY20_Gas_Rx" SG_ 1798 TesterPhysicalReqIPMA 1;
BA_ "U_U611_U625_MY20_Diesel_Rx" SG_ 1798 TesterPhysicalReqIPMA 1;
BA_ "U_C519_MY18_5_Gas_Rx" SG_ 1798 TesterPhysicalReqIPMA 1;
BA_ "U_C519_MY18_5_Diesel_Rx" SG_ 1798 TesterPhysicalReqIPMA 1;
BA_ "U_B479_MY17_Diesel_Rx" SG_ 1798 TesterPhysicalReqIPMA 1;
BA_ "U_B479_MY17_Gas_Rx" SG_ 1798 TesterPhysicalReqIPMA 1;
BA_ "GenSigSendType" SG_ 1798 TesterPhysicalReqIPMA 3;
BA_ "U_U611_U625_MY20_Phev_Tx" SG_ 129 SteWhlSwtchView_B_Stat 1;
BA_ "U_CX482_CX483_MY20_Hev_Tx" SG_ 129 SteWhlSwtchView_B_Stat 1;
BA_ "U_CX482_CX483_MY20_Gas_Tx" SG_ 129 SteWhlSwtchView_B_Stat 1;
BA_ "U_CX482_CX483_MY20_Diesel_Tx" SG_ 129 SteWhlSwtchView_B_Stat 1;
BA_ "U_U611_U625_MY20_Hev_Tx" SG_ 129 SteWhlSwtchView_B_Stat 1;
BA_ "U_U611_U625_MY20_Gas_Tx" SG_ 129 SteWhlSwtchView_B_Stat 1;
BA_ "U_U611_U625_MY20_Diesel_Tx" SG_ 129 SteWhlSwtchView_B_Stat 1;
BA_ "U_B500_MY18_Diesel_Tx" SG_ 129 SteWhlSwtchView_B_Stat 1;
BA_ "U_B500_MY18_Gas_Tx" SG_ 129 SteWhlSwtchView_B_Stat 1;
BA_ "U_C519_MY18_5_Gas_Tx" SG_ 129 SteWhlSwtchView_B_Stat 1;
BA_ "U_C519_MY18_5_Diesel_Tx" SG_ 129 SteWhlSwtchView_B_Stat 1;
BA_ "U_B515_MCA_MY17_Gas_Tx" SG_ 129 SteWhlSwtchView_B_Stat 1;
BA_ "U_B515_MCA_MY17_Diesel_Tx" SG_ 129 SteWhlSwtchView_B_Stat 1;
BA_ "U_B479_MY17_Diesel_Tx" SG_ 129 SteWhlSwtchView_B_Stat 1;
BA_ "U_B479_MY17_Gas_Tx" SG_ 129 SteWhlSwtchView_B_Stat 1;
BA_ "GenSigSendType" SG_ 129 SteWhlSwtchView_B_Stat 3;
BA_ "WakeupSignal" SG_ 129 SteWhlSwtchView_B_Stat 1;
BA_ "U_U611_U625_MY20_Phev_Tx" SG_ 129 SteWhlSwtchSet_B_Stat 1;
BA_ "U_CX482_CX483_MY20_Hev_Tx" SG_ 129 SteWhlSwtchSet_B_Stat 1;
BA_ "U_CX482_CX483_MY20_Gas_Tx" SG_ 129 SteWhlSwtchSet_B_Stat 1;
BA_ "U_CX482_CX483_MY20_Diesel_Tx" SG_ 129 SteWhlSwtchSet_B_Stat 1;
BA_ "U_U611_U625_MY20_Hev_Tx" SG_ 129 SteWhlSwtchSet_B_Stat 1;
BA_ "U_U611_U625_MY20_Gas_Tx" SG_ 129 SteWhlSwtchSet_B_Stat 1;
BA_ "U_U611_U625_MY20_Diesel_Tx" SG_ 129 SteWhlSwtchSet_B_Stat 1;
BA_ "U_B500_MY18_Diesel_Tx" SG_ 129 SteWhlSwtchSet_B_Stat 1;
BA_ "U_B500_MY18_Gas_Tx" SG_ 129 SteWhlSwtchSet_B_Stat 1;
BA_ "U_C519_MY18_5_Gas_Tx" SG_ 129 SteWhlSwtchSet_B_Stat 1;
BA_ "U_C519_MY18_5_Diesel_Tx" SG_ 129 SteWhlSwtchSet_B_Stat 1;
BA_ "U_B515_MCA_MY17_Gas_Tx" SG_ 129 SteWhlSwtchSet_B_Stat 1;
BA_ "U_B515_MCA_MY17_Diesel_Tx" SG_ 129 SteWhlSwtchSet_B_Stat 1;
BA_ "U_B479_MY17_Diesel_Tx" SG_ 129 SteWhlSwtchSet_B_Stat 1;
BA_ "U_B479_MY17_Gas_Tx" SG_ 129 SteWhlSwtchSet_B_Stat 1;
BA_ "GenSigSendType" SG_ 129 SteWhlSwtchSet_B_Stat 3;
BA_ "WakeupSignal" SG_ 129 SteWhlSwtchSet_B_Stat 1;
BA_ "U_U611_U625_MY20_Phev_Tx" SG_ 129 SteWhlSwtchPhon_B_Stat 1;
BA_ "U_CX482_CX483_MY20_Hev_Tx" SG_ 129 SteWhlSwtchPhon_B_Stat 1;
BA_ "U_CX482_CX483_MY20_Gas_Tx" SG_ 129 SteWhlSwtchPhon_B_Stat 1;
BA_ "U_CX482_CX483_MY20_Diesel_Tx" SG_ 129 SteWhlSwtchPhon_B_Stat 1;
BA_ "U_U611_U625_MY20_Hev_Tx" SG_ 129 SteWhlSwtchPhon_B_Stat 1;
BA_ "U_U611_U625_MY20_Gas_Tx" SG_ 129 SteWhlSwtchPhon_B_Stat 1;
BA_ "U_U611_U625_MY20_Diesel_Tx" SG_ 129 SteWhlSwtchPhon_B_Stat 1;
BA_ "U_B500_MY18_Diesel_Tx" SG_ 129 SteWhlSwtchPhon_B_Stat 1;
BA_ "U_B500_MY18_Gas_Tx" SG_ 129 SteWhlSwtchPhon_B_Stat 1;
BA_ "U_C519_MY18_5_Gas_Tx" SG_ 129 SteWhlSwtchPhon_B_Stat 1;
BA_ "U_C519_MY18_5_Diesel_Tx" SG_ 129 SteWhlSwtchPhon_B_Stat 1;
BA_ "U_B515_MCA_MY17_Gas_Tx" SG_ 129 SteWhlSwtchPhon_B_Stat 1;
BA_ "U_B515_MCA_MY17_Diesel_Tx" SG_ 129 SteWhlSwtchPhon_B_Stat 1;
BA_ "U_B479_MY17_Diesel_Tx" SG_ 129 SteWhlSwtchPhon_B_Stat 1;
BA_ "U_B479_MY17_Gas_Tx" SG_ 129 SteWhlSwtchPhon_B_Stat 1;
BA_ "GenSigSendType" SG_ 129 SteWhlSwtchPhon_B_Stat 3;
BA_ "WakeupSignal" SG_ 129 SteWhlSwtchPhon_B_Stat 1;
BA_ "U_U611_U625_MY20_Phev_Tx" SG_ 129 SteWhlSwtchNav_B_Stat 1;
BA_ "U_CX482_CX483_MY20_Hev_Tx" SG_ 129 SteWhlSwtchNav_B_Stat 1;
BA_ "U_CX482_CX483_MY20_Gas_Tx" SG_ 129 SteWhlSwtchNav_B_Stat 1;
BA_ "U_CX482_CX483_MY20_Diesel_Tx" SG_ 129 SteWhlSwtchNav_B_Stat 1;
BA_ "U_U611_U625_MY20_Hev_Tx" SG_ 129 SteWhlSwtchNav_B_Stat 1;
BA_ "U_U611_U625_MY20_Gas_Tx" SG_ 129 SteWhlSwtchNav_B_Stat 1;
BA_ "U_U611_U625_MY20_Diesel_Tx" SG_ 129 SteWhlSwtchNav_B_Stat 1;
BA_ "U_B500_MY18_Diesel_Tx" SG_ 129 SteWhlSwtchNav_B_Stat 1;
BA_ "U_B500_MY18_Gas_Tx" SG_ 129 SteWhlSwtchNav_B_Stat 1;
BA_ "U_C519_MY18_5_Gas_Tx" SG_ 129 SteWhlSwtchNav_B_Stat 1;
BA_ "U_C519_MY18_5_Diesel_Tx" SG_ 129 SteWhlSwtchNav_B_Stat 1;
BA_ "U_B515_MCA_MY17_Gas_Tx" SG_ 129 SteWhlSwtchNav_B_Stat 1;
BA_ "U_B515_MCA_MY17_Diesel_Tx" SG_ 129 SteWhlSwtchNav_B_Stat 1;
BA_ "U_B479_MY17_Diesel_Tx" SG_ 129 SteWhlSwtchNav_B_Stat 1;
BA_ "U_B479_MY17_Gas_Tx" SG_ 129 SteWhlSwtchNav_B_Stat 1;
BA_ "GenSigSendType" SG_ 129 SteWhlSwtchNav_B_Stat 3;
BA_ "WakeupSignal" SG_ 129 SteWhlSwtchNav_B_Stat 1;
BA_ "U_U611_U625_MY20_Phev_Tx" SG_ 129 SteWhlSwtchMed_B_Stat 1;
BA_ "U_CX482_CX483_MY20_Hev_Tx" SG_ 129 SteWhlSwtchMed_B_Stat 1;
BA_ "U_CX482_CX483_MY20_Gas_Tx" SG_ 129 SteWhlSwtchMed_B_Stat 1;
BA_ "U_CX482_CX483_MY20_Diesel_Tx" SG_ 129 SteWhlSwtchMed_B_Stat 1;
BA_ "U_U611_U625_MY20_Hev_Tx" SG_ 129 SteWhlSwtchMed_B_Stat 1;
BA_ "U_U611_U625_MY20_Gas_Tx" SG_ 129 SteWhlSwtchMed_B_Stat 1;
BA_ "U_U611_U625_MY20_Diesel_Tx" SG_ 129 SteWhlSwtchMed_B_Stat 1;
BA_ "U_B500_MY18_Diesel_Tx" SG_ 129 SteWhlSwtchMed_B_Stat 1;
BA_ "U_B500_MY18_Gas_Tx" SG_ 129 SteWhlSwtchMed_B_Stat 1;
BA_ "U_C519_MY18_5_Gas_Tx" SG_ 129 SteWhlSwtchMed_B_Stat 1;
BA_ "U_C519_MY18_5_Diesel_Tx" SG_ 129 SteWhlSwtchMed_B_Stat 1;
BA_ "U_B515_MCA_MY17_Gas_Tx" SG_ 129 SteWhlSwtchMed_B_Stat 1;
BA_ "U_B515_MCA_MY17_Diesel_Tx" SG_ 129 SteWhlSwtchMed_B_Stat 1;
BA_ "U_B479_MY17_Diesel_Tx" SG_ 129 SteWhlSwtchMed_B_Stat 1;
BA_ "U_B479_MY17_Gas_Tx" SG_ 129 SteWhlSwtchMed_B_Stat 1;
BA_ "GenSigSendType" SG_ 129 SteWhlSwtchMed_B_Stat 3;
BA_ "WakeupSignal" SG_ 129 SteWhlSwtchMed_B_Stat 1;
BA_ "U_U611_U625_MY20_Phev_Tx" SG_ 129 SteWhlSwtchIod_B_Stat 1;
BA_ "U_CX482_CX483_MY20_Hev_Tx" SG_ 129 SteWhlSwtchIod_B_Stat 1;
BA_ "U_CX482_CX483_MY20_Gas_Tx" SG_ 129 SteWhlSwtchIod_B_Stat 1;
BA_ "U_CX482_CX483_MY20_Diesel_Tx" SG_ 129 SteWhlSwtchIod_B_Stat 1;
BA_ "U_U611_U625_MY20_Hev_Tx" SG_ 129 SteWhlSwtchIod_B_Stat 1;
BA_ "U_U611_U625_MY20_Gas_Tx" SG_ 129 SteWhlSwtchIod_B_Stat 1;
BA_ "U_U611_U625_MY20_Diesel_Tx" SG_ 129 SteWhlSwtchIod_B_Stat 1;
BA_ "U_B500_MY18_Diesel_Tx" SG_ 129 SteWhlSwtchIod_B_Stat 1;
BA_ "U_B500_MY18_Gas_Tx" SG_ 129 SteWhlSwtchIod_B_Stat 1;
BA_ "U_C519_MY18_5_Gas_Tx" SG_ 129 SteWhlSwtchIod_B_Stat 1;
BA_ "U_C519_MY18_5_Diesel_Tx" SG_ 129 SteWhlSwtchIod_B_Stat 1;
BA_ "U_B515_MCA_MY17_Gas_Tx" SG_ 129 SteWhlSwtchIod_B_Stat 1;
BA_ "U_B515_MCA_MY17_Diesel_Tx" SG_ 129 SteWhlSwtchIod_B_Stat 1;
BA_ "U_B479_MY17_Diesel_Tx" SG_ 129 SteWhlSwtchIod_B_Stat 1;
BA_ "U_B479_MY17_Gas_Tx" SG_ 129 SteWhlSwtchIod_B_Stat 1;
BA_ "GenSigSendType" SG_ 129 SteWhlSwtchIod_B_Stat 3;
BA_ "WakeupSignal" SG_ 129 SteWhlSwtchIod_B_Stat 1;
BA_ "U_U611_U625_MY20_Phev_Tx" SG_ 129 SteWhlSwtchHud_B_Stat 1;
BA_ "U_CX482_CX483_MY20_Hev_Tx" SG_ 129 SteWhlSwtchHud_B_Stat 1;
BA_ "U_CX482_CX483_MY20_Gas_Tx" SG_ 129 SteWhlSwtchHud_B_Stat 1;
BA_ "U_CX482_CX483_MY20_Diesel_Tx" SG_ 129 SteWhlSwtchHud_B_Stat 1;
BA_ "U_U611_U625_MY20_Hev_Tx" SG_ 129 SteWhlSwtchHud_B_Stat 1;
BA_ "U_U611_U625_MY20_Gas_Tx" SG_ 129 SteWhlSwtchHud_B_Stat 1;
BA_ "U_U611_U625_MY20_Diesel_Tx" SG_ 129 SteWhlSwtchHud_B_Stat 1;
BA_ "U_B500_MY18_Diesel_Tx" SG_ 129 SteWhlSwtchHud_B_Stat 1;
BA_ "U_B500_MY18_Gas_Tx" SG_ 129 SteWhlSwtchHud_B_Stat 1;
BA_ "U_C519_MY18_5_Gas_Tx" SG_ 129 SteWhlSwtchHud_B_Stat 1;
BA_ "U_C519_MY18_5_Diesel_Tx" SG_ 129 SteWhlSwtchHud_B_Stat 1;
BA_ "U_B515_MCA_MY17_Gas_Tx" SG_ 129 SteWhlSwtchHud_B_Stat 1;
BA_ "U_B515_MCA_MY17_Diesel_Tx" SG_ 129 SteWhlSwtchHud_B_Stat 1;
BA_ "U_B479_MY17_Diesel_Tx" SG_ 129 SteWhlSwtchHud_B_Stat 1;
BA_ "U_B479_MY17_Gas_Tx" SG_ 129 SteWhlSwtchHud_B_Stat 1;
BA_ "GenSigSendType" SG_ 129 SteWhlSwtchHud_B_Stat 3;
BA_ "WakeupSignal" SG_ 129 SteWhlSwtchHud_B_Stat 1;
BA_ "U_U611_U625_MY20_Phev_Tx" SG_ 129 SteWhlSwtchBack_B_Stat 1;
BA_ "U_CX482_CX483_MY20_Hev_Tx" SG_ 129 SteWhlSwtchBack_B_Stat 1;
BA_ "U_CX482_CX483_MY20_Gas_Tx" SG_ 129 SteWhlSwtchBack_B_Stat 1;
BA_ "U_CX482_CX483_MY20_Diesel_Tx" SG_ 129 SteWhlSwtchBack_B_Stat 1;
BA_ "U_U611_U625_MY20_Hev_Tx" SG_ 129 SteWhlSwtchBack_B_Stat 1;
BA_ "U_U611_U625_MY20_Gas_Tx" SG_ 129 SteWhlSwtchBack_B_Stat 1;
BA_ "U_U611_U625_MY20_Diesel_Tx" SG_ 129 SteWhlSwtchBack_B_Stat 1;
BA_ "U_B500_MY18_Diesel_Tx" SG_ 129 SteWhlSwtchBack_B_Stat 1;
BA_ "U_B500_MY18_Gas_Tx" SG_ 129 SteWhlSwtchBack_B_Stat 1;
BA_ "U_C519_MY18_5_Gas_Tx" SG_ 129 SteWhlSwtchBack_B_Stat 1;
BA_ "U_C519_MY18_5_Diesel_Tx" SG_ 129 SteWhlSwtchBack_B_Stat 1;
BA_ "U_B515_MCA_MY17_Gas_Tx" SG_ 129 SteWhlSwtchBack_B_Stat 1;
BA_ "U_B515_MCA_MY17_Diesel_Tx" SG_ 129 SteWhlSwtchBack_B_Stat 1;
BA_ "U_B479_MY17_Diesel_Tx" SG_ 129 SteWhlSwtchBack_B_Stat 1;
BA_ "U_B479_MY17_Gas_Tx" SG_ 129 SteWhlSwtchBack_B_Stat 1;
BA_ "GenSigSendType" SG_ 129 SteWhlSwtchBack_B_Stat 3;
BA_ "WakeupSignal" SG_ 129 SteWhlSwtchBack_B_Stat 1;
BA_ "U_U611_U625_MY20_Phev_Tx" SG_ 129 SteWhlSwtchMenu_B_Stat 1;
BA_ "U_CX482_CX483_MY20_Hev_Tx" SG_ 129 SteWhlSwtchMenu_B_Stat 1;
BA_ "U_CX482_CX483_MY20_Gas_Tx" SG_ 129 SteWhlSwtchMenu_B_Stat 1;
BA_ "U_CX482_CX483_MY20_Diesel_Tx" SG_ 129 SteWhlSwtchMenu_B_Stat 1;
BA_ "U_U611_U625_MY20_Hev_Tx" SG_ 129 SteWhlSwtchMenu_B_Stat 1;
BA_ "U_U611_U625_MY20_Gas_Tx" SG_ 129 SteWhlSwtchMenu_B_Stat 1;
BA_ "U_U611_U625_MY20_Diesel_Tx" SG_ 129 SteWhlSwtchMenu_B_Stat 1;
BA_ "U_B500_MY18_Diesel_Tx" SG_ 129 SteWhlSwtchMenu_B_Stat 1;
BA_ "U_B500_MY18_Gas_Tx" SG_ 129 SteWhlSwtchMenu_B_Stat 1;
BA_ "U_C519_MY18_5_Gas_Tx" SG_ 129 SteWhlSwtchMenu_B_Stat 1;
BA_ "U_C519_MY18_5_Diesel_Tx" SG_ 129 SteWhlSwtchMenu_B_Stat 1;
BA_ "U_B515_MCA_MY17_Gas_Tx" SG_ 129 SteWhlSwtchMenu_B_Stat 1;
BA_ "U_B515_MCA_MY17_Diesel_Tx" SG_ 129 SteWhlSwtchMenu_B_Stat 1;
BA_ "U_B479_MY17_Diesel_Tx" SG_ 129 SteWhlSwtchMenu_B_Stat 1;
BA_ "U_B479_MY17_Gas_Tx" SG_ 129 SteWhlSwtchMenu_B_Stat 1;
BA_ "GenSigSendType" SG_ 129 SteWhlSwtchMenu_B_Stat 3;
BA_ "WakeupSignal" SG_ 129 SteWhlSwtchMenu_B_Stat 1;
BA_ "U_U611_U625_MY20_Phev_Tx" SG_ 129 SteEffortInc_B_RqDrv 1;
BA_ "U_CX482_CX483_MY20_Hev_Tx" SG_ 129 SteEffortInc_B_RqDrv 1;
BA_ "U_CX482_CX483_MY20_Gas_Tx" SG_ 129 SteEffortInc_B_RqDrv 1;
BA_ "U_CX482_CX483_MY20_Diesel_Tx" SG_ 129 SteEffortInc_B_RqDrv 1;
BA_ "U_U611_U625_MY20_Hev_Tx" SG_ 129 SteEffortInc_B_RqDrv 1;
BA_ "U_U611_U625_MY20_Gas_Tx" SG_ 129 SteEffortInc_B_RqDrv 1;
BA_ "U_U611_U625_MY20_Diesel_Tx" SG_ 129 SteEffortInc_B_RqDrv 1;
BA_ "U_B500_MY18_Diesel_Tx" SG_ 129 SteEffortInc_B_RqDrv 1;
BA_ "U_B500_MY18_Gas_Tx" SG_ 129 SteEffortInc_B_RqDrv 1;
BA_ "U_C519_MY18_5_Gas_Tx" SG_ 129 SteEffortInc_B_RqDrv 1;
BA_ "U_C519_MY18_5_Diesel_Tx" SG_ 129 SteEffortInc_B_RqDrv 1;
BA_ "U_B515_MCA_MY17_Gas_Tx" SG_ 129 SteEffortInc_B_RqDrv 1;
BA_ "U_B515_MCA_MY17_Diesel_Tx" SG_ 129 SteEffortInc_B_RqDrv 1;
BA_ "U_B479_MY17_Diesel_Tx" SG_ 129 SteEffortInc_B_RqDrv 1;
BA_ "U_B479_MY17_Gas_Tx" SG_ 129 SteEffortInc_B_RqDrv 1;
BA_ "GenSigSendType" SG_ 129 SteEffortInc_B_RqDrv 3;
BA_ "U_U611_U625_MY20_Phev_Tx" SG_ 129 SelDrvMdeInc_B_RqDrv 1;
BA_ "U_CX482_CX483_MY20_Hev_Tx" SG_ 129 SelDrvMdeInc_B_RqDrv 1;
BA_ "U_CX482_CX483_MY20_Gas_Tx" SG_ 129 SelDrvMdeInc_B_RqDrv 1;
BA_ "U_CX482_CX483_MY20_Diesel_Tx" SG_ 129 SelDrvMdeInc_B_RqDrv 1;
BA_ "U_U611_U625_MY20_Hev_Tx" SG_ 129 SelDrvMdeInc_B_RqDrv 1;
BA_ "U_U611_U625_MY20_Gas_Tx" SG_ 129 SelDrvMdeInc_B_RqDrv 1;
BA_ "U_U611_U625_MY20_Diesel_Tx" SG_ 129 SelDrvMdeInc_B_RqDrv 1;
BA_ "U_B500_MY18_Diesel_Tx" SG_ 129 SelDrvMdeInc_B_RqDrv 1;
BA_ "U_B500_MY18_Gas_Tx" SG_ 129 SelDrvMdeInc_B_RqDrv 1;
BA_ "U_C519_MY18_5_Gas_Tx" SG_ 129 SelDrvMdeInc_B_RqDrv 1;
BA_ "U_C519_MY18_5_Diesel_Tx" SG_ 129 SelDrvMdeInc_B_RqDrv 1;
BA_ "U_B515_MCA_MY17_Gas_Tx" SG_ 129 SelDrvMdeInc_B_RqDrv 1;
BA_ "U_B515_MCA_MY17_Diesel_Tx" SG_ 129 SelDrvMdeInc_B_RqDrv 1;
BA_ "U_B479_MY17_Diesel_Tx" SG_ 129 SelDrvMdeInc_B_RqDrv 1;
BA_ "U_B479_MY17_Gas_Tx" SG_ 129 SelDrvMdeInc_B_RqDrv 1;
BA_ "GenSigSendType" SG_ 129 SelDrvMdeInc_B_RqDrv 3;
BA_ "U_U611_U625_MY20_Phev_Tx" SG_ 129 SelDrvMdeDec_B_RqDrv 1;
BA_ "U_CX482_CX483_MY20_Hev_Tx" SG_ 129 SelDrvMdeDec_B_RqDrv 1;
BA_ "U_CX482_CX483_MY20_Gas_Tx" SG_ 129 SelDrvMdeDec_B_RqDrv 1;
BA_ "U_CX482_CX483_MY20_Diesel_Tx" SG_ 129 SelDrvMdeDec_B_RqDrv 1;
BA_ "U_U611_U625_MY20_Hev_Tx" SG_ 129 SelDrvMdeDec_B_RqDrv 1;
BA_ "U_U611_U625_MY20_Gas_Tx" SG_ 129 SelDrvMdeDec_B_RqDrv 1;
BA_ "U_U611_U625_MY20_Diesel_Tx" SG_ 129 SelDrvMdeDec_B_RqDrv 1;
BA_ "U_B500_MY18_Diesel_Tx" SG_ 129 SelDrvMdeDec_B_RqDrv 1;
BA_ "U_B500_MY18_Gas_Tx" SG_ 129 SelDrvMdeDec_B_RqDrv 1;
BA_ "U_C519_MY18_5_Gas_Tx" SG_ 129 SelDrvMdeDec_B_RqDrv 1;
BA_ "U_C519_MY18_5_Diesel_Tx" SG_ 129 SelDrvMdeDec_B_RqDrv 1;
BA_ "U_B515_MCA_MY17_Gas_Tx" SG_ 129 SelDrvMdeDec_B_RqDrv 1;
BA_ "U_B515_MCA_MY17_Diesel_Tx" SG_ 129 SelDrvMdeDec_B_RqDrv 1;
BA_ "U_B479_MY17_Diesel_Tx" SG_ 129 SelDrvMdeDec_B_RqDrv 1;
BA_ "U_B479_MY17_Gas_Tx" SG_ 129 SelDrvMdeDec_B_RqDrv 1;
BA_ "GenSigSendType" SG_ 129 SelDrvMdeDec_B_RqDrv 3;
BA_ "U_U611_U625_MY20_Phev_Tx" SG_ 129 SuspDampInc_B_RqDrv 1;
BA_ "U_CX482_CX483_MY20_Hev_Tx" SG_ 129 SuspDampInc_B_RqDrv 1;
BA_ "U_CX482_CX483_MY20_Gas_Tx" SG_ 129 SuspDampInc_B_RqDrv 1;
BA_ "U_CX482_CX483_MY20_Diesel_Tx" SG_ 129 SuspDampInc_B_RqDrv 1;
BA_ "U_U611_U625_MY20_Hev_Tx" SG_ 129 SuspDampInc_B_RqDrv 1;
BA_ "U_U611_U625_MY20_Gas_Tx" SG_ 129 SuspDampInc_B_RqDrv 1;
BA_ "U_U611_U625_MY20_Diesel_Tx" SG_ 129 SuspDampInc_B_RqDrv 1;
BA_ "U_B500_MY18_Diesel_Tx" SG_ 129 SuspDampInc_B_RqDrv 1;
BA_ "U_B500_MY18_Gas_Tx" SG_ 129 SuspDampInc_B_RqDrv 1;
BA_ "U_C519_MY18_5_Gas_Tx" SG_ 129 SuspDampInc_B_RqDrv 1;
BA_ "U_C519_MY18_5_Diesel_Tx" SG_ 129 SuspDampInc_B_RqDrv 1;
BA_ "U_B515_MCA_MY17_Gas_Tx" SG_ 129 SuspDampInc_B_RqDrv 1;
BA_ "U_B515_MCA_MY17_Diesel_Tx" SG_ 129 SuspDampInc_B_RqDrv 1;
BA_ "U_B479_MY17_Diesel_Tx" SG_ 129 SuspDampInc_B_RqDrv 1;
BA_ "U_B479_MY17_Gas_Tx" SG_ 129 SuspDampInc_B_RqDrv 1;
BA_ "GenSigSendType" SG_ 129 SuspDampInc_B_RqDrv 3;
BA_ "U_U611_U625_MY20_Phev_Tx" SG_ 129 SteWhlSwtchUp_B_Stat 1;
BA_ "U_CX482_CX483_MY20_Hev_Tx" SG_ 129 SteWhlSwtchUp_B_Stat 1;
BA_ "U_CX482_CX483_MY20_Gas_Tx" SG_ 129 SteWhlSwtchUp_B_Stat 1;
BA_ "U_CX482_CX483_MY20_Diesel_Tx" SG_ 129 SteWhlSwtchUp_B_Stat 1;
BA_ "U_U611_U625_MY20_Hev_Tx" SG_ 129 SteWhlSwtchUp_B_Stat 1;
BA_ "U_U611_U625_MY20_Gas_Tx" SG_ 129 SteWhlSwtchUp_B_Stat 1;
BA_ "U_U611_U625_MY20_Diesel_Tx" SG_ 129 SteWhlSwtchUp_B_Stat 1;
BA_ "U_B500_MY18_Diesel_Tx" SG_ 129 SteWhlSwtchUp_B_Stat 1;
BA_ "U_B500_MY18_Gas_Tx" SG_ 129 SteWhlSwtchUp_B_Stat 1;
BA_ "U_C519_MY18_5_Gas_Tx" SG_ 129 SteWhlSwtchUp_B_Stat 1;
BA_ "U_C519_MY18_5_Diesel_Tx" SG_ 129 SteWhlSwtchUp_B_Stat 1;
BA_ "U_B515_MCA_MY17_Gas_Tx" SG_ 129 SteWhlSwtchUp_B_Stat 1;
BA_ "U_B515_MCA_MY17_Diesel_Tx" SG_ 129 SteWhlSwtchUp_B_Stat 1;
BA_ "U_B479_MY17_Diesel_Tx" SG_ 129 SteWhlSwtchUp_B_Stat 1;
BA_ "U_B479_MY17_Gas_Tx" SG_ 129 SteWhlSwtchUp_B_Stat 1;
BA_ "GenSigSendType" SG_ 129 SteWhlSwtchUp_B_Stat 3;
BA_ "WakeupSignal" SG_ 129 SteWhlSwtchUp_B_Stat 1;
BA_ "U_U611_U625_MY20_Phev_Tx" SG_ 129 SteWhlSwtchRght_B_Stat 1;
BA_ "U_CX482_CX483_MY20_Hev_Tx" SG_ 129 SteWhlSwtchRght_B_Stat 1;
BA_ "U_CX482_CX483_MY20_Gas_Tx" SG_ 129 SteWhlSwtchRght_B_Stat 1;
BA_ "U_CX482_CX483_MY20_Diesel_Tx" SG_ 129 SteWhlSwtchRght_B_Stat 1;
BA_ "U_U611_U625_MY20_Hev_Tx" SG_ 129 SteWhlSwtchRght_B_Stat 1;
BA_ "U_U611_U625_MY20_Gas_Tx" SG_ 129 SteWhlSwtchRght_B_Stat 1;
BA_ "U_U611_U625_MY20_Diesel_Tx" SG_ 129 SteWhlSwtchRght_B_Stat 1;
BA_ "U_B500_MY18_Diesel_Tx" SG_ 129 SteWhlSwtchRght_B_Stat 1;
BA_ "U_B500_MY18_Gas_Tx" SG_ 129 SteWhlSwtchRght_B_Stat 1;
BA_ "U_C519_MY18_5_Gas_Tx" SG_ 129 SteWhlSwtchRght_B_Stat 1;
BA_ "U_C519_MY18_5_Diesel_Tx" SG_ 129 SteWhlSwtchRght_B_Stat 1;
BA_ "U_B515_MCA_MY17_Gas_Tx" SG_ 129 SteWhlSwtchRght_B_Stat 1;
BA_ "U_B515_MCA_MY17_Diesel_Tx" SG_ 129 SteWhlSwtchRght_B_Stat 1;
BA_ "U_B479_MY17_Diesel_Tx" SG_ 129 SteWhlSwtchRght_B_Stat 1;
BA_ "U_B479_MY17_Gas_Tx" SG_ 129 SteWhlSwtchRght_B_Stat 1;
BA_ "GenSigSendType" SG_ 129 SteWhlSwtchRght_B_Stat 3;
BA_ "WakeupSignal" SG_ 129 SteWhlSwtchRght_B_Stat 1;
BA_ "U_U611_U625_MY20_Phev_Tx" SG_ 129 SteWhlSwtchOk_B_Stat 1;
BA_ "U_CX482_CX483_MY20_Hev_Tx" SG_ 129 SteWhlSwtchOk_B_Stat 1;
BA_ "U_CX482_CX483_MY20_Gas_Tx" SG_ 129 SteWhlSwtchOk_B_Stat 1;
BA_ "U_CX482_CX483_MY20_Diesel_Tx" SG_ 129 SteWhlSwtchOk_B_Stat 1;
BA_ "U_U611_U625_MY20_Hev_Tx" SG_ 129 SteWhlSwtchOk_B_Stat 1;
BA_ "U_U611_U625_MY20_Gas_Tx" SG_ 129 SteWhlSwtchOk_B_Stat 1;
BA_ "U_U611_U625_MY20_Diesel_Tx" SG_ 129 SteWhlSwtchOk_B_Stat 1;
BA_ "U_B500_MY18_Diesel_Tx" SG_ 129 SteWhlSwtchOk_B_Stat 1;
BA_ "U_B500_MY18_Gas_Tx" SG_ 129 SteWhlSwtchOk_B_Stat 1;
BA_ "U_C519_MY18_5_Gas_Tx" SG_ 129 SteWhlSwtchOk_B_Stat 1;
BA_ "U_C519_MY18_5_Diesel_Tx" SG_ 129 SteWhlSwtchOk_B_Stat 1;
BA_ "U_B515_MCA_MY17_Gas_Tx" SG_ 129 SteWhlSwtchOk_B_Stat 1;
BA_ "U_B515_MCA_MY17_Diesel_Tx" SG_ 129 SteWhlSwtchOk_B_Stat 1;
BA_ "U_B479_MY17_Diesel_Tx" SG_ 129 SteWhlSwtchOk_B_Stat 1;
BA_ "U_B479_MY17_Gas_Tx" SG_ 129 SteWhlSwtchOk_B_Stat 1;
BA_ "GenSigSendType" SG_ 129 SteWhlSwtchOk_B_Stat 3;
BA_ "WakeupSignal" SG_ 129 SteWhlSwtchOk_B_Stat 1;
BA_ "U_U611_U625_MY20_Phev_Tx" SG_ 129 SteWhlSwtchLeft_B_Stat 1;
BA_ "U_CX482_CX483_MY20_Hev_Tx" SG_ 129 SteWhlSwtchLeft_B_Stat 1;
BA_ "U_CX482_CX483_MY20_Gas_Tx" SG_ 129 SteWhlSwtchLeft_B_Stat 1;
BA_ "U_CX482_CX483_MY20_Diesel_Tx" SG_ 129 SteWhlSwtchLeft_B_Stat 1;
BA_ "U_U611_U625_MY20_Hev_Tx" SG_ 129 SteWhlSwtchLeft_B_Stat 1;
BA_ "U_U611_U625_MY20_Gas_Tx" SG_ 129 SteWhlSwtchLeft_B_Stat 1;
BA_ "U_U611_U625_MY20_Diesel_Tx" SG_ 129 SteWhlSwtchLeft_B_Stat 1;
BA_ "U_B500_MY18_Diesel_Tx" SG_ 129 SteWhlSwtchLeft_B_Stat 1;
BA_ "U_B500_MY18_Gas_Tx" SG_ 129 SteWhlSwtchLeft_B_Stat 1;
BA_ "U_C519_MY18_5_Gas_Tx" SG_ 129 SteWhlSwtchLeft_B_Stat 1;
BA_ "U_C519_MY18_5_Diesel_Tx" SG_ 129 SteWhlSwtchLeft_B_Stat 1;
BA_ "U_B515_MCA_MY17_Gas_Tx" SG_ 129 SteWhlSwtchLeft_B_Stat 1;
BA_ "U_B515_MCA_MY17_Diesel_Tx" SG_ 129 SteWhlSwtchLeft_B_Stat 1;
BA_ "U_B479_MY17_Diesel_Tx" SG_ 129 SteWhlSwtchLeft_B_Stat 1;
BA_ "U_B479_MY17_Gas_Tx" SG_ 129 SteWhlSwtchLeft_B_Stat 1;
BA_ "GenSigSendType" SG_ 129 SteWhlSwtchLeft_B_Stat 3;
BA_ "WakeupSignal" SG_ 129 SteWhlSwtchLeft_B_Stat 1;
BA_ "U_U611_U625_MY20_Phev_Tx" SG_ 129 SteWhlSwtchDown_B_Stat 1;
BA_ "U_CX482_CX483_MY20_Hev_Tx" SG_ 129 SteWhlSwtchDown_B_Stat 1;
BA_ "U_CX482_CX483_MY20_Gas_Tx" SG_ 129 SteWhlSwtchDown_B_Stat 1;
BA_ "U_CX482_CX483_MY20_Diesel_Tx" SG_ 129 SteWhlSwtchDown_B_Stat 1;
BA_ "U_U611_U625_MY20_Hev_Tx" SG_ 129 SteWhlSwtchDown_B_Stat 1;
BA_ "U_U611_U625_MY20_Gas_Tx" SG_ 129 SteWhlSwtchDown_B_Stat 1;
BA_ "U_U611_U625_MY20_Diesel_Tx" SG_ 129 SteWhlSwtchDown_B_Stat 1;
BA_ "U_B500_MY18_Diesel_Tx" SG_ 129 SteWhlSwtchDown_B_Stat 1;
BA_ "U_B500_MY18_Gas_Tx" SG_ 129 SteWhlSwtchDown_B_Stat 1;
BA_ "U_C519_MY18_5_Gas_Tx" SG_ 129 SteWhlSwtchDown_B_Stat 1;
BA_ "U_C519_MY18_5_Diesel_Tx" SG_ 129 SteWhlSwtchDown_B_Stat 1;
BA_ "U_B515_MCA_MY17_Gas_Tx" SG_ 129 SteWhlSwtchDown_B_Stat 1;
BA_ "U_B515_MCA_MY17_Diesel_Tx" SG_ 129 SteWhlSwtchDown_B_Stat 1;
BA_ "U_B479_MY17_Diesel_Tx" SG_ 129 SteWhlSwtchDown_B_Stat 1;
BA_ "U_B479_MY17_Gas_Tx" SG_ 129 SteWhlSwtchDown_B_Stat 1;
BA_ "GenSigSendType" SG_ 129 SteWhlSwtchDown_B_Stat 3;
BA_ "WakeupSignal" SG_ 129 SteWhlSwtchDown_B_Stat 1;
BA_ "U_U611_U625_MY20_Phev_Tx" SG_ 1833 TesterPhysicalResVDM 1;
BA_ "U_U611_U625_MY20_Hev_Tx" SG_ 1833 TesterPhysicalResVDM 1;
BA_ "U_U611_U625_MY20_Gas_Tx" SG_ 1833 TesterPhysicalResVDM 1;
BA_ "U_U611_U625_MY20_Diesel_Tx" SG_ 1833 TesterPhysicalResVDM 1;
BA_ "U_C519_MY18_5_Gas_Tx" SG_ 1833 TesterPhysicalResVDM 1;
BA_ "U_C519_MY18_5_Diesel_Tx" SG_ 1833 TesterPhysicalResVDM 1;
BA_ "GenSigSendType" SG_ 1833 TesterPhysicalResVDM 3;
BA_ "U_CX482_CX483_MY20_Hev_Rx" SG_ 1109 eCallConfirmation 1;
BA_ "U_CX482_CX483_MY20_Gas_Rx" SG_ 1109 eCallConfirmation 1;
BA_ "U_CX482_CX483_MY20_Diesel_Rx" SG_ 1109 eCallConfirmation 1;
BA_ "U_U611_U625_MY20_Hev_Rx" SG_ 1109 eCallConfirmation 1;
BA_ "U_U611_U625_MY20_Gas_Rx" SG_ 1109 eCallConfirmation 1;
BA_ "U_U611_U625_MY20_Diesel_Rx" SG_ 1109 eCallConfirmation 1;
BA_ "U_B500_MY18_Diesel_Rx" SG_ 1109 eCallConfirmation 1;
BA_ "U_B500_MY18_Gas_Rx" SG_ 1109 eCallConfirmation 1;
BA_ "U_C490_MY18_Rx" SG_ 1109 eCallConfirmation 1;
BA_ "U_B562_MY18_Gas_Rx" SG_ 1109 eCallConfirmation 1;
BA_ "U_C519_MY18_5_Gas_Rx" SG_ 1109 eCallConfirmation 1;
BA_ "U_C519_MY18_5_Diesel_Rx" SG_ 1109 eCallConfirmation 1;
BA_ "U_B515_MCA_MY17_Gas_Rx" SG_ 1109 eCallConfirmation 1;
BA_ "U_B515_MCA_MY17_Diesel_Rx" SG_ 1109 eCallConfirmation 1;
BA_ "U_CX482_CX483_MY20_Hev_Tx" SG_ 394 AccTrgDist2_D_Dsply 1;
BA_ "U_CX482_CX483_MY20_Gas_Tx" SG_ 394 AccTrgDist2_D_Dsply 1;
BA_ "U_CX482_CX483_MY20_Diesel_Tx" SG_ 394 AccTrgDist2_D_Dsply 1;
BA_ "U_U611_U625_MY20_Hev_Tx" SG_ 394 AccTrgDist2_D_Dsply 1;
BA_ "U_U611_U625_MY20_Gas_Tx" SG_ 394 AccTrgDist2_D_Dsply 1;
BA_ "U_U611_U625_MY20_Diesel_Tx" SG_ 394 AccTrgDist2_D_Dsply 1;
BA_ "U_C519_MY18_5_Gas_Tx" SG_ 394 AccTrgDist2_D_Dsply 1;
BA_ "U_C519_MY18_5_Diesel_Tx" SG_ 394 AccTrgDist2_D_Dsply 1;
BA_ "U_B479_MY17_Diesel_Tx" SG_ 394 AccTrgDist2_D_Dsply 1;
BA_ "U_B479_MY17_Gas_Tx" SG_ 394 AccTrgDist2_D_Dsply 1;
BA_ "GenSigSendType" SG_ 394 AccTrgDist2_D_Dsply 3;
BA_ "CrossOver_InfoCAN" SG_ 394 AccTrgDist2_D_Dsply 1;
BA_ "U_CX482_CX483_MY20_Hev_Tx" SG_ 394 AccStopRes_B_Dsply 1;
BA_ "U_CX482_CX483_MY20_Gas_Tx" SG_ 394 AccStopRes_B_Dsply 1;
BA_ "U_CX482_CX483_MY20_Diesel_Tx" SG_ 394 AccStopRes_B_Dsply 1;
BA_ "U_U611_U625_MY20_Hev_Tx" SG_ 394 AccStopRes_B_Dsply 1;
BA_ "U_U611_U625_MY20_Gas_Tx" SG_ 394 AccStopRes_B_Dsply 1;
BA_ "U_U611_U625_MY20_Diesel_Tx" SG_ 394 AccStopRes_B_Dsply 1;
BA_ "U_C519_MY18_5_Gas_Tx" SG_ 394 AccStopRes_B_Dsply 1;
BA_ "U_C519_MY18_5_Diesel_Tx" SG_ 394 AccStopRes_B_Dsply 1;
BA_ "U_B479_MY17_Diesel_Tx" SG_ 394 AccStopRes_B_Dsply 1;
BA_ "U_B479_MY17_Gas_Tx" SG_ 394 AccStopRes_B_Dsply 1;
BA_ "GenSigSendType" SG_ 394 AccStopRes_B_Dsply 3;
BA_ "CrossOver_InfoCAN" SG_ 394 AccStopRes_B_Dsply 1;
BA_ "U_CX482_CX483_MY20_Hev_Tx" SG_ 394 TjaWarn_D_Rq 1;
BA_ "U_CX482_CX483_MY20_Gas_Tx" SG_ 394 TjaWarn_D_Rq 1;
BA_ "U_CX482_CX483_MY20_Diesel_Tx" SG_ 394 TjaWarn_D_Rq 1;
BA_ "U_U611_U625_MY20_Hev_Tx" SG_ 394 TjaWarn_D_Rq 1;
BA_ "U_U611_U625_MY20_Gas_Tx" SG_ 394 TjaWarn_D_Rq 1;
BA_ "U_U611_U625_MY20_Diesel_Tx" SG_ 394 TjaWarn_D_Rq 1;
BA_ "U_C519_MY18_5_Gas_Tx" SG_ 394 TjaWarn_D_Rq 1;
BA_ "U_C519_MY18_5_Diesel_Tx" SG_ 394 TjaWarn_D_Rq 1;
BA_ "GenSigSendType" SG_ 394 TjaWarn_D_Rq 3;
BA_ "U_CX482_CX483_MY20_Hev_Tx" SG_ 394 Tja_D_Stat 1;
BA_ "U_CX482_CX483_MY20_Gas_Tx" SG_ 394 Tja_D_Stat 1;
BA_ "U_CX482_CX483_MY20_Diesel_Tx" SG_ 394 Tja_D_Stat 1;
BA_ "U_U611_U625_MY20_Hev_Tx" SG_ 394 Tja_D_Stat 1;
BA_ "U_U611_U625_MY20_Gas_Tx" SG_ 394 Tja_D_Stat 1;
BA_ "U_U611_U625_MY20_Diesel_Tx" SG_ 394 Tja_D_Stat 1;
BA_ "U_C519_MY18_5_Gas_Tx" SG_ 394 Tja_D_Stat 1;
BA_ "U_C519_MY18_5_Diesel_Tx" SG_ 394 Tja_D_Stat 1;
BA_ "GenSigSendType" SG_ 394 Tja_D_Stat 3;
BA_ "U_CX482_CX483_MY20_Hev_Tx" SG_ 394 TjaMsgTxt_D_Dsply 1;
BA_ "U_CX482_CX483_MY20_Gas_Tx" SG_ 394 TjaMsgTxt_D_Dsply 1;
BA_ "U_CX482_CX483_MY20_Diesel_Tx" SG_ 394 TjaMsgTxt_D_Dsply 1;
BA_ "U_U611_U625_MY20_Hev_Tx" SG_ 394 TjaMsgTxt_D_Dsply 1;
BA_ "U_U611_U625_MY20_Gas_Tx" SG_ 394 TjaMsgTxt_D_Dsply 1;
BA_ "U_U611_U625_MY20_Diesel_Tx" SG_ 394 TjaMsgTxt_D_Dsply 1;
BA_ "U_C519_MY18_5_Gas_Tx" SG_ 394 TjaMsgTxt_D_Dsply 1;
BA_ "U_C519_MY18_5_Diesel_Tx" SG_ 394 TjaMsgTxt_D_Dsply 1;
BA_ "GenSigSendType" SG_ 394 TjaMsgTxt_D_Dsply 3;
BA_ "U_CX482_CX483_MY20_Hev_Tx" SG_ 394 IaccLamp_D_Rq 1;
BA_ "U_CX482_CX483_MY20_Gas_Tx" SG_ 394 IaccLamp_D_Rq 1;
BA_ "U_CX482_CX483_MY20_Diesel_Tx" SG_ 394 IaccLamp_D_Rq 1;
BA_ "U_U611_U625_MY20_Hev_Tx" SG_ 394 IaccLamp_D_Rq 1;
BA_ "U_U611_U625_MY20_Gas_Tx" SG_ 394 IaccLamp_D_Rq 1;
BA_ "U_U611_U625_MY20_Diesel_Tx" SG_ 394 IaccLamp_D_Rq 1;
BA_ "U_C519_MY18_5_Gas_Tx" SG_ 394 IaccLamp_D_Rq 1;
BA_ "U_C519_MY18_5_Diesel_Tx" SG_ 394 IaccLamp_D_Rq 1;
BA_ "GenSigSendType" SG_ 394 IaccLamp_D_Rq 3;
BA_ "U_CX482_CX483_MY20_Hev_Tx" SG_ 394 AccMsgTxt_D2_Rq 1;
BA_ "U_CX482_CX483_MY20_Gas_Tx" SG_ 394 AccMsgTxt_D2_Rq 1;
BA_ "U_CX482_CX483_MY20_Diesel_Tx" SG_ 394 AccMsgTxt_D2_Rq 1;
BA_ "U_U611_U625_MY20_Hev_Tx" SG_ 394 AccMsgTxt_D2_Rq 1;
BA_ "U_U611_U625_MY20_Gas_Tx" SG_ 394 AccMsgTxt_D2_Rq 1;
BA_ "U_U611_U625_MY20_Diesel_Tx" SG_ 394 AccMsgTxt_D2_Rq 1;
BA_ "U_C519_MY18_5_Gas_Tx" SG_ 394 AccMsgTxt_D2_Rq 1;
BA_ "U_C519_MY18_5_Diesel_Tx" SG_ 394 AccMsgTxt_D2_Rq 1;
BA_ "GenSigSendType" SG_ 394 AccMsgTxt_D2_Rq 3;
BA_ "U_CX482_CX483_MY20_Hev_Tx" SG_ 394 FcwDeny_B_Dsply 1;
BA_ "U_CX482_CX483_MY20_Gas_Tx" SG_ 394 FcwDeny_B_Dsply 1;
BA_ "U_CX482_CX483_MY20_Diesel_Tx" SG_ 394 FcwDeny_B_Dsply 1;
BA_ "U_U611_U625_MY20_Hev_Tx" SG_ 394 FcwDeny_B_Dsply 1;
BA_ "U_U611_U625_MY20_Gas_Tx" SG_ 394 FcwDeny_B_Dsply 1;
BA_ "U_U611_U625_MY20_Diesel_Tx" SG_ 394 FcwDeny_B_Dsply 1;
BA_ "U_C519_MY18_5_Gas_Tx" SG_ 394 FcwDeny_B_Dsply 1;
BA_ "U_C519_MY18_5_Diesel_Tx" SG_ 394 FcwDeny_B_Dsply 1;
BA_ "U_B479_MY17_Diesel_Tx" SG_ 394 FcwDeny_B_Dsply 1;
BA_ "U_B479_MY17_Gas_Tx" SG_ 394 FcwDeny_B_Dsply 1;
BA_ "GenSigSendType" SG_ 394 FcwDeny_B_Dsply 3;
BA_ "CrossOver_InfoCAN" SG_ 394 FcwDeny_B_Dsply 1;
BA_ "U_CX482_CX483_MY20_Hev_Tx" SG_ 394 FdaWarn_B_Rq 1;
BA_ "U_CX482_CX483_MY20_Gas_Tx" SG_ 394 FdaWarn_B_Rq 1;
BA_ "U_CX482_CX483_MY20_Diesel_Tx" SG_ 394 FdaWarn_B_Rq 1;
BA_ "U_U611_U625_MY20_Hev_Tx" SG_ 394 FdaWarn_B_Rq 1;
BA_ "U_U611_U625_MY20_Gas_Tx" SG_ 394 FdaWarn_B_Rq 1;
BA_ "U_U611_U625_MY20_Diesel_Tx" SG_ 394 FdaWarn_B_Rq 1;
BA_ "U_C519_MY18_5_Gas_Tx" SG_ 394 FdaWarn_B_Rq 1;
BA_ "U_C519_MY18_5_Diesel_Tx" SG_ 394 FdaWarn_B_Rq 1;
BA_ "U_B479_MY17_Diesel_Tx" SG_ 394 FdaWarn_B_Rq 1;
BA_ "U_B479_MY17_Gas_Tx" SG_ 394 FdaWarn_B_Rq 1;
BA_ "GenSigSendType" SG_ 394 FdaWarn_B_Rq 3;
BA_ "CrossOver_InfoCAN" SG_ 394 FdaWarn_B_Rq 1;
BA_ "U_CX482_CX483_MY20_Hev_Tx" SG_ 394 FcwMemStat_B_Actl 1;
BA_ "U_CX482_CX483_MY20_Gas_Tx" SG_ 394 FcwMemStat_B_Actl 1;
BA_ "U_CX482_CX483_MY20_Diesel_Tx" SG_ 394 FcwMemStat_B_Actl 1;
BA_ "U_U611_U625_MY20_Hev_Tx" SG_ 394 FcwMemStat_B_Actl 1;
BA_ "U_U611_U625_MY20_Gas_Tx" SG_ 394 FcwMemStat_B_Actl 1;
BA_ "U_U611_U625_MY20_Diesel_Tx" SG_ 394 FcwMemStat_B_Actl 1;
BA_ "U_C519_MY18_5_Gas_Tx" SG_ 394 FcwMemStat_B_Actl 1;
BA_ "U_C519_MY18_5_Diesel_Tx" SG_ 394 FcwMemStat_B_Actl 1;
BA_ "U_B479_MY17_Diesel_Tx" SG_ 394 FcwMemStat_B_Actl 1;
BA_ "U_B479_MY17_Gas_Tx" SG_ 394 FcwMemStat_B_Actl 1;
BA_ "GenSigSendType" SG_ 394 FcwMemStat_B_Actl 3;
BA_ "CrossOver_InfoCAN" SG_ 394 FcwMemStat_B_Actl 1;
BA_ "U_CX482_CX483_MY20_Hev_Tx" SG_ 394 AccTGap_B_Dsply 1;
BA_ "U_CX482_CX483_MY20_Gas_Tx" SG_ 394 AccTGap_B_Dsply 1;
BA_ "U_CX482_CX483_MY20_Diesel_Tx" SG_ 394 AccTGap_B_Dsply 1;
BA_ "U_U611_U625_MY20_Hev_Tx" SG_ 394 AccTGap_B_Dsply 1;
BA_ "U_U611_U625_MY20_Gas_Tx" SG_ 394 AccTGap_B_Dsply 1;
BA_ "U_U611_U625_MY20_Diesel_Tx" SG_ 394 AccTGap_B_Dsply 1;
BA_ "U_C519_MY18_5_Gas_Tx" SG_ 394 AccTGap_B_Dsply 1;
BA_ "U_C519_MY18_5_Diesel_Tx" SG_ 394 AccTGap_B_Dsply 1;
BA_ "U_B479_MY17_Diesel_Tx" SG_ 394 AccTGap_B_Dsply 1;
BA_ "U_B479_MY17_Gas_Tx" SG_ 394 AccTGap_B_Dsply 1;
BA_ "GenSigSendType" SG_ 394 AccTGap_B_Dsply 3;
BA_ "CrossOver_InfoCAN" SG_ 394 AccTGap_B_Dsply 1;
BA_ "U_CX482_CX483_MY20_Hev_Tx" SG_ 394 CadsAlignIncplt_B_Actl 1;
BA_ "U_CX482_CX483_MY20_Gas_Tx" SG_ 394 CadsAlignIncplt_B_Actl 1;
BA_ "U_CX482_CX483_MY20_Diesel_Tx" SG_ 394 CadsAlignIncplt_B_Actl 1;
BA_ "U_U611_U625_MY20_Hev_Tx" SG_ 394 CadsAlignIncplt_B_Actl 1;
BA_ "U_U611_U625_MY20_Gas_Tx" SG_ 394 CadsAlignIncplt_B_Actl 1;
BA_ "U_U611_U625_MY20_Diesel_Tx" SG_ 394 CadsAlignIncplt_B_Actl 1;
BA_ "U_C519_MY18_5_Gas_Tx" SG_ 394 CadsAlignIncplt_B_Actl 1;
BA_ "U_C519_MY18_5_Diesel_Tx" SG_ 394 CadsAlignIncplt_B_Actl 1;
BA_ "U_B479_MY17_Diesel_Tx" SG_ 394 CadsAlignIncplt_B_Actl 1;
BA_ "U_B479_MY17_Gas_Tx" SG_ 394 CadsAlignIncplt_B_Actl 1;
BA_ "GenSigSendType" SG_ 394 CadsAlignIncplt_B_Actl 3;
BA_ "CrossOver_InfoCAN" SG_ 394 CadsAlignIncplt_B_Actl 1;
BA_ "GenSigSendType" SG_ 394 AccLowVMde_B_Dsply 3;
BA_ "CrossOver_InfoCAN" SG_ 394 AccLowVMde_B_Dsply 1;
BA_ "U_CX482_CX483_MY20_Hev_Tx" SG_ 394 AccFllwMde_B_Dsply 1;
BA_ "U_CX482_CX483_MY20_Gas_Tx" SG_ 394 AccFllwMde_B_Dsply 1;
BA_ "U_CX482_CX483_MY20_Diesel_Tx" SG_ 394 AccFllwMde_B_Dsply 1;
BA_ "U_U611_U625_MY20_Hev_Tx" SG_ 394 AccFllwMde_B_Dsply 1;
BA_ "U_U611_U625_MY20_Gas_Tx" SG_ 394 AccFllwMde_B_Dsply 1;
BA_ "U_U611_U625_MY20_Diesel_Tx" SG_ 394 AccFllwMde_B_Dsply 1;
BA_ "U_C519_MY18_5_Gas_Tx" SG_ 394 AccFllwMde_B_Dsply 1;
BA_ "U_C519_MY18_5_Diesel_Tx" SG_ 394 AccFllwMde_B_Dsply 1;
BA_ "U_B479_MY17_Diesel_Tx" SG_ 394 AccFllwMde_B_Dsply 1;
BA_ "U_B479_MY17_Gas_Tx" SG_ 394 AccFllwMde_B_Dsply 1;
BA_ "GenSigSendType" SG_ 394 AccFllwMde_B_Dsply 3;
BA_ "CrossOver_InfoCAN" SG_ 394 AccFllwMde_B_Dsply 1;
BA_ "U_CX482_CX483_MY20_Hev_Tx" SG_ 394 CadsRadrBlck_B_Actl 1;
BA_ "U_CX482_CX483_MY20_Gas_Tx" SG_ 394 CadsRadrBlck_B_Actl 1;
BA_ "U_CX482_CX483_MY20_Diesel_Tx" SG_ 394 CadsRadrBlck_B_Actl 1;
BA_ "U_U611_U625_MY20_Hev_Tx" SG_ 394 CadsRadrBlck_B_Actl 1;
BA_ "U_U611_U625_MY20_Gas_Tx" SG_ 394 CadsRadrBlck_B_Actl 1;
BA_ "U_U611_U625_MY20_Diesel_Tx" SG_ 394 CadsRadrBlck_B_Actl 1;
BA_ "U_C519_MY18_5_Gas_Tx" SG_ 394 CadsRadrBlck_B_Actl 1;
BA_ "U_C519_MY18_5_Diesel_Tx" SG_ 394 CadsRadrBlck_B_Actl 1;
BA_ "U_B479_MY17_Diesel_Tx" SG_ 394 CadsRadrBlck_B_Actl 1;
BA_ "U_B479_MY17_Gas_Tx" SG_ 394 CadsRadrBlck_B_Actl 1;
BA_ "GenSigSendType" SG_ 394 CadsRadrBlck_B_Actl 3;
BA_ "CrossOver_InfoCAN" SG_ 394 CadsRadrBlck_B_Actl 1;
BA_ "U_CX482_CX483_MY20_Hev_Tx" SG_ 394 FdaStat_D_Dsply 1;
BA_ "U_CX482_CX483_MY20_Gas_Tx" SG_ 394 FdaStat_D_Dsply 1;
BA_ "U_CX482_CX483_MY20_Diesel_Tx" SG_ 394 FdaStat_D_Dsply 1;
BA_ "U_U611_U625_MY20_Hev_Tx" SG_ 394 FdaStat_D_Dsply 1;
BA_ "U_U611_U625_MY20_Gas_Tx" SG_ 394 FdaStat_D_Dsply 1;
BA_ "U_U611_U625_MY20_Diesel_Tx" SG_ 394 FdaStat_D_Dsply 1;
BA_ "U_C519_MY18_5_Gas_Tx" SG_ 394 FdaStat_D_Dsply 1;
BA_ "U_C519_MY18_5_Diesel_Tx" SG_ 394 FdaStat_D_Dsply 1;
BA_ "U_B479_MY17_Diesel_Tx" SG_ 394 FdaStat_D_Dsply 1;
BA_ "U_B479_MY17_Gas_Tx" SG_ 394 FdaStat_D_Dsply 1;
BA_ "GenSigSendType" SG_ 394 FdaStat_D_Dsply 3;
BA_ "CrossOver_InfoCAN" SG_ 394 FdaStat_D_Dsply 1;
BA_ "U_CX482_CX483_MY20_Hev_Tx" SG_ 394 FdaDeny_B_Dsply 1;
BA_ "U_CX482_CX483_MY20_Gas_Tx" SG_ 394 FdaDeny_B_Dsply 1;
BA_ "U_CX482_CX483_MY20_Diesel_Tx" SG_ 394 FdaDeny_B_Dsply 1;
BA_ "U_U611_U625_MY20_Hev_Tx" SG_ 394 FdaDeny_B_Dsply 1;
BA_ "U_U611_U625_MY20_Gas_Tx" SG_ 394 FdaDeny_B_Dsply 1;
BA_ "U_U611_U625_MY20_Diesel_Tx" SG_ 394 FdaDeny_B_Dsply 1;
BA_ "U_C519_MY18_5_Gas_Tx" SG_ 394 FdaDeny_B_Dsply 1;
BA_ "U_C519_MY18_5_Diesel_Tx" SG_ 394 FdaDeny_B_Dsply 1;
BA_ "U_B479_MY17_Diesel_Tx" SG_ 394 FdaDeny_B_Dsply 1;
BA_ "U_B479_MY17_Gas_Tx" SG_ 394 FdaDeny_B_Dsply 1;
BA_ "GenSigSendType" SG_ 394 FdaDeny_B_Dsply 3;
BA_ "CrossOver_InfoCAN" SG_ 394 FdaDeny_B_Dsply 1;
BA_ "U_CX482_CX483_MY20_Hev_Tx" SG_ 394 CadsChime_B_Rq 1;
BA_ "U_CX482_CX483_MY20_Gas_Tx" SG_ 394 CadsChime_B_Rq 1;
BA_ "U_CX482_CX483_MY20_Diesel_Tx" SG_ 394 CadsChime_B_Rq 1;
BA_ "U_U611_U625_MY20_Hev_Tx" SG_ 394 CadsChime_B_Rq 1;
BA_ "U_U611_U625_MY20_Gas_Tx" SG_ 394 CadsChime_B_Rq 1;
BA_ "U_U611_U625_MY20_Diesel_Tx" SG_ 394 CadsChime_B_Rq 1;
BA_ "U_C519_MY18_5_Gas_Tx" SG_ 394 CadsChime_B_Rq 1;
BA_ "U_C519_MY18_5_Diesel_Tx" SG_ 394 CadsChime_B_Rq 1;
BA_ "U_B479_MY17_Diesel_Tx" SG_ 394 CadsChime_B_Rq 1;
BA_ "U_B479_MY17_Gas_Tx" SG_ 394 CadsChime_B_Rq 1;
BA_ "GenSigSendType" SG_ 394 CadsChime_B_Rq 3;
BA_ "CrossOver_InfoCAN" SG_ 394 CadsChime_B_Rq 1;
BA_ "U_CX482_CX483_MY20_Hev_Tx" SG_ 394 CmbbPostEvnt_B_Dsply 1;
BA_ "U_CX482_CX483_MY20_Gas_Tx" SG_ 394 CmbbPostEvnt_B_Dsply 1;
BA_ "U_CX482_CX483_MY20_Diesel_Tx" SG_ 394 CmbbPostEvnt_B_Dsply 1;
BA_ "U_U611_U625_MY20_Hev_Tx" SG_ 394 CmbbPostEvnt_B_Dsply 1;
BA_ "U_U611_U625_MY20_Gas_Tx" SG_ 394 CmbbPostEvnt_B_Dsply 1;
BA_ "U_U611_U625_MY20_Diesel_Tx" SG_ 394 CmbbPostEvnt_B_Dsply 1;
BA_ "U_C519_MY18_5_Gas_Tx" SG_ 394 CmbbPostEvnt_B_Dsply 1;
BA_ "U_C519_MY18_5_Diesel_Tx" SG_ 394 CmbbPostEvnt_B_Dsply 1;
BA_ "U_B479_MY17_Diesel_Tx" SG_ 394 CmbbPostEvnt_B_Dsply 1;
BA_ "U_B479_MY17_Gas_Tx" SG_ 394 CmbbPostEvnt_B_Dsply 1;
BA_ "GenSigSendType" SG_ 394 CmbbPostEvnt_B_Dsply 3;
BA_ "CrossOver_InfoCAN" SG_ 394 CmbbPostEvnt_B_Dsply 1;
BA_ "GenSigSendType" SG_ 394 FcwCmbbSrvcRqd_B_Rq 3;
BA_ "CrossOver_InfoCAN" SG_ 394 FcwCmbbSrvcRqd_B_Rq 1;
BA_ "U_CX482_CX483_MY20_Hev_Tx" SG_ 394 AccStopMde_B_Dsply 1;
BA_ "U_CX482_CX483_MY20_Gas_Tx" SG_ 394 AccStopMde_B_Dsply 1;
BA_ "U_CX482_CX483_MY20_Diesel_Tx" SG_ 394 AccStopMde_B_Dsply 1;
BA_ "U_U611_U625_MY20_Hev_Tx" SG_ 394 AccStopMde_B_Dsply 1;
BA_ "U_U611_U625_MY20_Gas_Tx" SG_ 394 AccStopMde_B_Dsply 1;
BA_ "U_U611_U625_MY20_Diesel_Tx" SG_ 394 AccStopMde_B_Dsply 1;
BA_ "U_C519_MY18_5_Gas_Tx" SG_ 394 AccStopMde_B_Dsply 1;
BA_ "U_C519_MY18_5_Diesel_Tx" SG_ 394 AccStopMde_B_Dsply 1;
BA_ "U_B479_MY17_Diesel_Tx" SG_ 394 AccStopMde_B_Dsply 1;
BA_ "U_B479_MY17_Gas_Tx" SG_ 394 AccStopMde_B_Dsply 1;
BA_ "GenSigSendType" SG_ 394 AccStopMde_B_Dsply 3;
BA_ "CrossOver_InfoCAN" SG_ 394 AccStopMde_B_Dsply 1;
BA_ "GenSigSendType" SG_ 394 CadsCamraBlck_B_Actl 3;
BA_ "CrossOver_InfoCAN" SG_ 394 CadsCamraBlck_B_Actl 1;
BA_ "U_CX482_CX483_MY20_Hev_Tx" SG_ 394 FcwMemSens_D_Actl 1;
BA_ "U_CX482_CX483_MY20_Gas_Tx" SG_ 394 FcwMemSens_D_Actl 1;
BA_ "U_CX482_CX483_MY20_Diesel_Tx" SG_ 394 FcwMemSens_D_Actl 1;
BA_ "U_U611_U625_MY20_Hev_Tx" SG_ 394 FcwMemSens_D_Actl 1;
BA_ "U_U611_U625_MY20_Gas_Tx" SG_ 394 FcwMemSens_D_Actl 1;
BA_ "U_U611_U625_MY20_Diesel_Tx" SG_ 394 FcwMemSens_D_Actl 1;
BA_ "U_C519_MY18_5_Gas_Tx" SG_ 394 FcwMemSens_D_Actl 1;
BA_ "U_C519_MY18_5_Diesel_Tx" SG_ 394 FcwMemSens_D_Actl 1;
BA_ "U_B479_MY17_Diesel_Tx" SG_ 394 FcwMemSens_D_Actl 1;
BA_ "U_B479_MY17_Gas_Tx" SG_ 394 FcwMemSens_D_Actl 1;
BA_ "GenSigSendType" SG_ 394 FcwMemSens_D_Actl 3;
BA_ "CrossOver_InfoCAN" SG_ 394 FcwMemSens_D_Actl 1;
BA_ "GenSigSendType" SG_ 394 FcwMemDfaltOn_B_Actl 3;
BA_ "CrossOver_InfoCAN" SG_ 394 FcwMemDfaltOn_B_Actl 1;
BA_ "U_CX482_CX483_MY20_Hev_Tx" SG_ 394 AccSrvcRqd_B_Rq 1;
BA_ "U_CX482_CX483_MY20_Gas_Tx" SG_ 394 AccSrvcRqd_B_Rq 1;
BA_ "U_CX482_CX483_MY20_Diesel_Tx" SG_ 394 AccSrvcRqd_B_Rq 1;
BA_ "U_U611_U625_MY20_Hev_Tx" SG_ 394 AccSrvcRqd_B_Rq 1;
BA_ "U_U611_U625_MY20_Gas_Tx" SG_ 394 AccSrvcRqd_B_Rq 1;
BA_ "U_U611_U625_MY20_Diesel_Tx" SG_ 394 AccSrvcRqd_B_Rq 1;
BA_ "U_C519_MY18_5_Gas_Tx" SG_ 394 AccSrvcRqd_B_Rq 1;
BA_ "U_C519_MY18_5_Diesel_Tx" SG_ 394 AccSrvcRqd_B_Rq 1;
BA_ "U_B479_MY17_Diesel_Tx" SG_ 394 AccSrvcRqd_B_Rq 1;
BA_ "U_B479_MY17_Gas_Tx" SG_ 394 AccSrvcRqd_B_Rq 1;
BA_ "GenSigSendType" SG_ 394 AccSrvcRqd_B_Rq 3;
BA_ "CrossOver_InfoCAN" SG_ 394 AccSrvcRqd_B_Rq 1;
BA_ "U_CX482_CX483_MY20_Hev_Tx" SG_ 394 FcwMsgTxt_D_Rq 1;
BA_ "U_CX482_CX483_MY20_Gas_Tx" SG_ 394 FcwMsgTxt_D_Rq 1;
BA_ "U_CX482_CX483_MY20_Diesel_Tx" SG_ 394 FcwMsgTxt_D_Rq 1;
BA_ "U_U611_U625_MY20_Hev_Tx" SG_ 394 FcwMsgTxt_D_Rq 1;
BA_ "U_U611_U625_MY20_Gas_Tx" SG_ 394 FcwMsgTxt_D_Rq 1;
BA_ "U_U611_U625_MY20_Diesel_Tx" SG_ 394 FcwMsgTxt_D_Rq 1;
BA_ "U_C519_MY18_5_Gas_Tx" SG_ 394 FcwMsgTxt_D_Rq 1;
BA_ "U_C519_MY18_5_Diesel_Tx" SG_ 394 FcwMsgTxt_D_Rq 1;
BA_ "U_B479_MY17_Diesel_Tx" SG_ 394 FcwMsgTxt_D_Rq 1;
BA_ "U_B479_MY17_Gas_Tx" SG_ 394 FcwMsgTxt_D_Rq 1;
BA_ "GenSigSendType" SG_ 394 FcwMsgTxt_D_Rq 3;
BA_ "CrossOver_InfoCAN" SG_ 394 FcwMsgTxt_D_Rq 1;
BA_ "U_CX482_CX483_MY20_Hev_Tx" SG_ 394 AccWarn_D_Dsply 1;
BA_ "U_CX482_CX483_MY20_Gas_Tx" SG_ 394 AccWarn_D_Dsply 1;
BA_ "U_CX482_CX483_MY20_Diesel_Tx" SG_ 394 AccWarn_D_Dsply 1;
BA_ "U_U611_U625_MY20_Hev_Tx" SG_ 394 AccWarn_D_Dsply 1;
BA_ "U_U611_U625_MY20_Gas_Tx" SG_ 394 AccWarn_D_Dsply 1;
BA_ "U_U611_U625_MY20_Diesel_Tx" SG_ 394 AccWarn_D_Dsply 1;
BA_ "U_C519_MY18_5_Gas_Tx" SG_ 394 AccWarn_D_Dsply 1;
BA_ "U_C519_MY18_5_Diesel_Tx" SG_ 394 AccWarn_D_Dsply 1;
BA_ "U_B479_MY17_Diesel_Tx" SG_ 394 AccWarn_D_Dsply 1;
BA_ "U_B479_MY17_Gas_Tx" SG_ 394 AccWarn_D_Dsply 1;
BA_ "GenSigSendType" SG_ 394 AccWarn_D_Dsply 3;
BA_ "CrossOver_InfoCAN" SG_ 394 AccWarn_D_Dsply 1;
BA_ "U_CX482_CX483_MY20_Hev_Tx" SG_ 394 FcwVisblWarn_B_Rq 1;
BA_ "U_CX482_CX483_MY20_Gas_Tx" SG_ 394 FcwVisblWarn_B_Rq 1;
BA_ "U_CX482_CX483_MY20_Diesel_Tx" SG_ 394 FcwVisblWarn_B_Rq 1;
BA_ "U_U611_U625_MY20_Hev_Tx" SG_ 394 FcwVisblWarn_B_Rq 1;
BA_ "U_U611_U625_MY20_Gas_Tx" SG_ 394 FcwVisblWarn_B_Rq 1;
BA_ "U_U611_U625_MY20_Diesel_Tx" SG_ 394 FcwVisblWarn_B_Rq 1;
BA_ "U_C519_MY18_5_Gas_Tx" SG_ 394 FcwVisblWarn_B_Rq 1;
BA_ "U_C519_MY18_5_Diesel_Tx" SG_ 394 FcwVisblWarn_B_Rq 1;
BA_ "U_B479_MY17_Diesel_Tx" SG_ 394 FcwVisblWarn_B_Rq 1;
BA_ "U_B479_MY17_Gas_Tx" SG_ 394 FcwVisblWarn_B_Rq 1;
BA_ "GenSigSendType" SG_ 394 FcwVisblWarn_B_Rq 3;
BA_ "CrossOver_InfoCAN" SG_ 394 FcwVisblWarn_B_Rq 1;
BA_ "U_CX482_CX483_MY20_Hev_Tx" SG_ 394 FcwAudioWarn_B_Rq 1;
BA_ "U_CX482_CX483_MY20_Gas_Tx" SG_ 394 FcwAudioWarn_B_Rq 1;
BA_ "U_CX482_CX483_MY20_Diesel_Tx" SG_ 394 FcwAudioWarn_B_Rq 1;
BA_ "U_U611_U625_MY20_Hev_Tx" SG_ 394 FcwAudioWarn_B_Rq 1;
BA_ "U_U611_U625_MY20_Gas_Tx" SG_ 394 FcwAudioWarn_B_Rq 1;
BA_ "U_U611_U625_MY20_Diesel_Tx" SG_ 394 FcwAudioWarn_B_Rq 1;
BA_ "U_C519_MY18_5_Gas_Tx" SG_ 394 FcwAudioWarn_B_Rq 1;
BA_ "U_C519_MY18_5_Diesel_Tx" SG_ 394 FcwAudioWarn_B_Rq 1;
BA_ "U_B479_MY17_Diesel_Tx" SG_ 394 FcwAudioWarn_B_Rq 1;
BA_ "U_B479_MY17_Gas_Tx" SG_ 394 FcwAudioWarn_B_Rq 1;
BA_ "GenSigSendType" SG_ 394 FcwAudioWarn_B_Rq 3;
BA_ "CrossOver_InfoCAN" SG_ 394 FcwAudioWarn_B_Rq 1;
BA_ "GenSigSendType" SG_ 394 FcwMemAudioOn_B_Actl 3;
BA_ "CrossOver_InfoCAN" SG_ 394 FcwMemAudioOn_B_Actl 1;
BA_ "U_CX482_CX483_MY20_Hev_Tx" SG_ 394 AccTGap_D_Dsply 1;
BA_ "U_CX482_CX483_MY20_Gas_Tx" SG_ 394 AccTGap_D_Dsply 1;
BA_ "U_CX482_CX483_MY20_Diesel_Tx" SG_ 394 AccTGap_D_Dsply 1;
BA_ "U_U611_U625_MY20_Hev_Tx" SG_ 394 AccTGap_D_Dsply 1;
BA_ "U_U611_U625_MY20_Gas_Tx" SG_ 394 AccTGap_D_Dsply 1;
BA_ "U_U611_U625_MY20_Diesel_Tx" SG_ 394 AccTGap_D_Dsply 1;
BA_ "U_C519_MY18_5_Gas_Tx" SG_ 394 AccTGap_D_Dsply 1;
BA_ "U_C519_MY18_5_Diesel_Tx" SG_ 394 AccTGap_D_Dsply 1;
BA_ "U_B479_MY17_Diesel_Tx" SG_ 394 AccTGap_D_Dsply 1;
BA_ "U_B479_MY17_Gas_Tx" SG_ 394 AccTGap_D_Dsply 1;
BA_ "GenSigSendType" SG_ 394 AccTGap_D_Dsply 3;
BA_ "GenSigStartValue" SG_ 394 AccTGap_D_Dsply 3;
BA_ "CrossOver_InfoCAN" SG_ 394 AccTGap_D_Dsply 1;
BA_ "U_CX482_CX483_MY20_Hev_Tx" SG_ 394 AccMemEnbl_B_RqDrv 1;
BA_ "U_CX482_CX483_MY20_Gas_Tx" SG_ 394 AccMemEnbl_B_RqDrv 1;
BA_ "U_CX482_CX483_MY20_Diesel_Tx" SG_ 394 AccMemEnbl_B_RqDrv 1;
BA_ "U_U611_U625_MY20_Hev_Tx" SG_ 394 AccMemEnbl_B_RqDrv 1;
BA_ "U_U611_U625_MY20_Gas_Tx" SG_ 394 AccMemEnbl_B_RqDrv 1;
BA_ "U_U611_U625_MY20_Diesel_Tx" SG_ 394 AccMemEnbl_B_RqDrv 1;
BA_ "U_C519_MY18_5_Gas_Tx" SG_ 394 AccMemEnbl_B_RqDrv 1;
BA_ "U_C519_MY18_5_Diesel_Tx" SG_ 394 AccMemEnbl_B_RqDrv 1;
BA_ "U_B479_MY17_Diesel_Tx" SG_ 394 AccMemEnbl_B_RqDrv 1;
BA_ "U_B479_MY17_Gas_Tx" SG_ 394 AccMemEnbl_B_RqDrv 1;
BA_ "GenSigSendType" SG_ 394 AccMemEnbl_B_RqDrv 3;
BA_ "GenSigStartValue" SG_ 394 AccMemEnbl_B_RqDrv 1;
BA_ "CrossOver_InfoCAN" SG_ 394 AccMemEnbl_B_RqDrv 1;
BA_ "U_CX482_CX483_MY20_Hev_Tx" SG_ 394 FdaMem_B_Stat 1;
BA_ "U_CX482_CX483_MY20_Gas_Tx" SG_ 394 FdaMem_B_Stat 1;
BA_ "U_CX482_CX483_MY20_Diesel_Tx" SG_ 394 FdaMem_B_Stat 1;
BA_ "U_U611_U625_MY20_Hev_Tx" SG_ 394 FdaMem_B_Stat 1;
BA_ "U_U611_U625_MY20_Gas_Tx" SG_ 394 FdaMem_B_Stat 1;
BA_ "U_U611_U625_MY20_Diesel_Tx" SG_ 394 FdaMem_B_Stat 1;
BA_ "U_C519_MY18_5_Gas_Tx" SG_ 394 FdaMem_B_Stat 1;
BA_ "U_C519_MY18_5_Diesel_Tx" SG_ 394 FdaMem_B_Stat 1;
BA_ "U_B479_MY17_Diesel_Tx" SG_ 394 FdaMem_B_Stat 1;
BA_ "U_B479_MY17_Gas_Tx" SG_ 394 FdaMem_B_Stat 1;
BA_ "GenSigSendType" SG_ 394 FdaMem_B_Stat 3;
BA_ "CrossOver_InfoCAN" SG_ 394 FdaMem_B_Stat 1;
BA_ "U_U611_U625_MY20_Hev_Tx" SG_ 1046 PrkBrkDynmc_D_Allw 1;
BA_ "U_U611_U625_MY20_Gas_Tx" SG_ 1046 PrkBrkDynmc_D_Allw 1;
BA_ "U_U611_U625_MY20_Diesel_Tx" SG_ 1046 PrkBrkDynmc_D_Allw 1;
BA_ "U_U611_U625_MY20_Hev_Tx" SG_ 1046 BrkPrkBrkDynmc_B_Actl 1;
BA_ "U_U611_U625_MY20_Gas_Tx" SG_ 1046 BrkPrkBrkDynmc_B_Actl 1;
BA_ "U_U611_U625_MY20_Diesel_Tx" SG_ 1046 BrkPrkBrkDynmc_B_Actl 1;
BA_ "U_U611_U625_MY20_Hev_Tx" SG_ 1046 ReserveTracCtlPtActv 1;
BA_ "U_U611_U625_MY20_Gas_Tx" SG_ 1046 ReserveTracCtlPtActv 1;
BA_ "U_U611_U625_MY20_Diesel_Tx" SG_ 1046 ReserveTracCtlPtActv 1;
BA_ "CrossOver_InfoCAN" SG_ 1046 ReserveTracCtlPtActv 1;
BA_ "U_CX482_CX483_MY20_Hev_Tx" SG_ 1046 HsaMde_D_Mem 1;
BA_ "U_CX482_CX483_MY20_Gas_Tx" SG_ 1046 HsaMde_D_Mem 1;
BA_ "U_CX482_CX483_MY20_Diesel_Tx" SG_ 1046 HsaMde_D_Mem 1;
BA_ "U_U611_U625_MY20_Hev_Tx" SG_ 1046 HsaMde_D_Mem 1;
BA_ "U_U611_U625_MY20_Gas_Tx" SG_ 1046 HsaMde_D_Mem 1;
BA_ "U_U611_U625_MY20_Diesel_Tx" SG_ 1046 HsaMde_D_Mem 1;
BA_ "U_B500_MY18_Diesel_Tx" SG_ 1046 HsaMde_D_Mem 1;
BA_ "U_B500_MY18_Gas_Tx" SG_ 1046 HsaMde_D_Mem 1;
BA_ "U_C490_MY18_Tx" SG_ 1046 HsaMde_D_Mem 1;
BA_ "U_B562_MY18_Gas_Tx" SG_ 1046 HsaMde_D_Mem 1;
BA_ "U_C519_MY18_5_Gas_Tx" SG_ 1046 HsaMde_D_Mem 1;
BA_ "U_C519_MY18_5_Diesel_Tx" SG_ 1046 HsaMde_D_Mem 1;
BA_ "U_B515_MCA_MY17_Gas_Tx" SG_ 1046 HsaMde_D_Mem 1;
BA_ "U_B515_MCA_MY17_Diesel_Tx" SG_ 1046 HsaMde_D_Mem 1;
BA_ "U_B479_MY17_Diesel_Tx" SG_ 1046 HsaMde_D_Mem 1;
BA_ "U_B479_MY17_Gas_Tx" SG_ 1046 HsaMde_D_Mem 1;
BA_ "U_B562LC_MY15_Gas_Tx" SG_ 1046 HsaMde_D_Mem 1;
BA_ "U_B562LC_MY15_Diesel_Tx" SG_ 1046 HsaMde_D_Mem 1;
BA_ "GenSigStartValue" SG_ 1046 HsaMde_D_Mem 1;
BA_ "CrossOver_InfoCAN" SG_ 1046 HsaMde_D_Mem 1;
BA_ "U_CX482_CX483_MY20_Hev_Tx" SG_ 1046 BrkBstrVac_B_Rq 1;
BA_ "U_CX482_CX483_MY20_Gas_Tx" SG_ 1046 BrkBstrVac_B_Rq 1;
BA_ "U_CX482_CX483_MY20_Diesel_Tx" SG_ 1046 BrkBstrVac_B_Rq 1;
BA_ "U_U611_U625_MY20_Hev_Tx" SG_ 1046 BrkBstrVac_B_Rq 1;
BA_ "U_U611_U625_MY20_Gas_Tx" SG_ 1046 BrkBstrVac_B_Rq 1;
BA_ "U_U611_U625_MY20_Diesel_Tx" SG_ 1046 BrkBstrVac_B_Rq 1;
BA_ "U_B500_MY18_Diesel_Tx" SG_ 1046 BrkBstrVac_B_Rq 1;
BA_ "U_B500_MY18_Gas_Tx" SG_ 1046 BrkBstrVac_B_Rq 1;
BA_ "U_C490_MY18_Tx" SG_ 1046 BrkBstrVac_B_Rq 1;
BA_ "U_B562_MY18_Gas_Tx" SG_ 1046 BrkBstrVac_B_Rq 1;
BA_ "U_C519_MY18_5_Gas_Tx" SG_ 1046 BrkBstrVac_B_Rq 1;
BA_ "U_C519_MY18_5_Diesel_Tx" SG_ 1046 BrkBstrVac_B_Rq 1;
BA_ "U_B515_MCA_MY17_Gas_Tx" SG_ 1046 BrkBstrVac_B_Rq 1;
BA_ "U_B515_MCA_MY17_Diesel_Tx" SG_ 1046 BrkBstrVac_B_Rq 1;
BA_ "U_B479_MY17_Diesel_Tx" SG_ 1046 BrkBstrVac_B_Rq 1;
BA_ "U_B479_MY17_Gas_Tx" SG_ 1046 BrkBstrVac_B_Rq 1;
BA_ "CrossOver_InfoCAN" SG_ 1046 BrkBstrVac_B_Rq 1;
BA_ "U_U611_U625_MY20_Hev_Tx" SG_ 1046 HdcMde_D_Actl 1;
BA_ "U_U611_U625_MY20_Gas_Tx" SG_ 1046 HdcMde_D_Actl 1;
BA_ "U_U611_U625_MY20_Diesel_Tx" SG_ 1046 HdcMde_D_Actl 1;
BA_ "CrossOver_InfoCAN" SG_ 1046 HdcMde_D_Actl 1;
BA_ "U_U611_U625_MY20_Hev_Tx" SG_ 1046 RearDiffLck_Tq2_RqMx 1;
BA_ "U_U611_U625_MY20_Gas_Tx" SG_ 1046 RearDiffLck_Tq2_RqMx 1;
BA_ "U_U611_U625_MY20_Diesel_Tx" SG_ 1046 RearDiffLck_Tq2_RqMx 1;
BA_ "GenSigStartValue" SG_ 1046 RearDiffLck_Tq2_RqMx 4094;
BA_ "U_CX482_CX483_MY20_Hev_Tx" SG_ 1046 TRLR_SWAY_EVNT_IN_PROG 1;
BA_ "U_CX482_CX483_MY20_Gas_Tx" SG_ 1046 TRLR_SWAY_EVNT_IN_PROG 1;
BA_ "U_CX482_CX483_MY20_Diesel_Tx" SG_ 1046 TRLR_SWAY_EVNT_IN_PROG 1;
BA_ "U_U611_U625_MY20_Hev_Tx" SG_ 1046 TRLR_SWAY_EVNT_IN_PROG 1;
BA_ "U_U611_U625_MY20_Gas_Tx" SG_ 1046 TRLR_SWAY_EVNT_IN_PROG 1;
BA_ "U_U611_U625_MY20_Diesel_Tx" SG_ 1046 TRLR_SWAY_EVNT_IN_PROG 1;
BA_ "U_B562_MY18_Gas_Tx" SG_ 1046 TRLR_SWAY_EVNT_IN_PROG 1;
BA_ "U_C519_MY18_5_Gas_Tx" SG_ 1046 TRLR_SWAY_EVNT_IN_PROG 1;
BA_ "U_C519_MY18_5_Diesel_Tx" SG_ 1046 TRLR_SWAY_EVNT_IN_PROG 1;
BA_ "U_B515_MCA_MY17_Gas_Tx" SG_ 1046 TRLR_SWAY_EVNT_IN_PROG 1;
BA_ "U_B515_MCA_MY17_Diesel_Tx" SG_ 1046 TRLR_SWAY_EVNT_IN_PROG 1;
BA_ "U_B479_MY17_Diesel_Tx" SG_ 1046 TRLR_SWAY_EVNT_IN_PROG 1;
BA_ "U_B479_MY17_Gas_Tx" SG_ 1046 TRLR_SWAY_EVNT_IN_PROG 1;
BA_ "U_CX482_CX483_MY20_Hev_Tx" SG_ 1046 TRLR_SWAY_CONFIG_STAT 1;
BA_ "U_CX482_CX483_MY20_Gas_Tx" SG_ 1046 TRLR_SWAY_CONFIG_STAT 1;
BA_ "U_CX482_CX483_MY20_Diesel_Tx" SG_ 1046 TRLR_SWAY_CONFIG_STAT 1;
BA_ "U_U611_U625_MY20_Hev_Tx" SG_ 1046 TRLR_SWAY_CONFIG_STAT 1;
BA_ "U_U611_U625_MY20_Gas_Tx" SG_ 1046 TRLR_SWAY_CONFIG_STAT 1;
BA_ "U_U611_U625_MY20_Diesel_Tx" SG_ 1046 TRLR_SWAY_CONFIG_STAT 1;
BA_ "U_B562_MY18_Gas_Tx" SG_ 1046 TRLR_SWAY_CONFIG_STAT 1;
BA_ "U_C519_MY18_5_Gas_Tx" SG_ 1046 TRLR_SWAY_CONFIG_STAT 1;
BA_ "U_C519_MY18_5_Diesel_Tx" SG_ 1046 TRLR_SWAY_CONFIG_STAT 1;
BA_ "U_B515_MCA_MY17_Gas_Tx" SG_ 1046 TRLR_SWAY_CONFIG_STAT 1;
BA_ "U_B515_MCA_MY17_Diesel_Tx" SG_ 1046 TRLR_SWAY_CONFIG_STAT 1;
BA_ "U_B479_MY17_Diesel_Tx" SG_ 1046 TRLR_SWAY_CONFIG_STAT 1;
BA_ "U_B479_MY17_Gas_Tx" SG_ 1046 TRLR_SWAY_CONFIG_STAT 1;
BA_ "U_CX482_CX483_MY20_Hev_Tx" SG_ 1046 TCMode 1;
BA_ "U_CX482_CX483_MY20_Gas_Tx" SG_ 1046 TCMode 1;
BA_ "U_CX482_CX483_MY20_Diesel_Tx" SG_ 1046 TCMode 1;
BA_ "U_U611_U625_MY20_Hev_Tx" SG_ 1046 TCMode 1;
BA_ "U_U611_U625_MY20_Gas_Tx" SG_ 1046 TCMode 1;
BA_ "U_U611_U625_MY20_Diesel_Tx" SG_ 1046 TCMode 1;
BA_ "U_B500_MY18_Diesel_Tx" SG_ 1046 TCMode 1;
BA_ "U_B500_MY18_Gas_Tx" SG_ 1046 TCMode 1;
BA_ "U_C490_MY18_Tx" SG_ 1046 TCMode 1;
BA_ "U_B562_MY18_Gas_Tx" SG_ 1046 TCMode 1;
BA_ "U_C519_MY18_5_Gas_Tx" SG_ 1046 TCMode 1;
BA_ "U_C519_MY18_5_Diesel_Tx" SG_ 1046 TCMode 1;
BA_ "U_B515_MCA_MY17_Gas_Tx" SG_ 1046 TCMode 1;
BA_ "U_B515_MCA_MY17_Diesel_Tx" SG_ 1046 TCMode 1;
BA_ "U_B479_MY17_Diesel_Tx" SG_ 1046 TCMode 1;
BA_ "U_B479_MY17_Gas_Tx" SG_ 1046 TCMode 1;
BA_ "U_B562LC_MY15_Gas_Tx" SG_ 1046 TCMode 1;
BA_ "U_B562LC_MY15_Diesel_Tx" SG_ 1046 TCMode 1;
BA_ "U_U611_U625_MY20_Phev_Rx" SG_ 1046 TCMode 1;
BA_ "U_CX482_CX483_MY20_Hev_Rx" SG_ 1046 TCMode 1;
BA_ "U_CX482_CX483_MY20_Gas_Rx" SG_ 1046 TCMode 1;
BA_ "U_CX482_CX483_MY20_Diesel_Rx" SG_ 1046 TCMode 1;
BA_ "U_U611_U625_MY20_Hev_Rx" SG_ 1046 TCMode 1;
BA_ "U_U611_U625_MY20_Gas_Rx" SG_ 1046 TCMode 1;
BA_ "U_U611_U625_MY20_Diesel_Rx" SG_ 1046 TCMode 1;
BA_ "U_B500_MY18_Diesel_Rx" SG_ 1046 TCMode 1;
BA_ "U_B500_MY18_Gas_Rx" SG_ 1046 TCMode 1;
BA_ "U_C490_MY18_Rx" SG_ 1046 TCMode 1;
BA_ "U_B562_MY18_Gas_Rx" SG_ 1046 TCMode 1;
BA_ "U_B515_MCA_MY17_Gas_Rx" SG_ 1046 TCMode 1;
BA_ "U_B515_MCA_MY17_Diesel_Rx" SG_ 1046 TCMode 1;
BA_ "U_C519_MY18_5_Gas_Rx" SG_ 1046 TCMode 1;
BA_ "U_C519_MY18_5_Diesel_Rx" SG_ 1046 TCMode 1;
BA_ "U_B479_MY17_Diesel_Rx" SG_ 1046 TCMode 1;
BA_ "U_B479_MY17_Gas_Rx" SG_ 1046 TCMode 1;
BA_ "ContentDependant" SG_ 1046 TCMode 1;
BA_ "CrossOver_InfoCAN" SG_ 1046 TCMode 1;
BA_ "U_CX482_CX483_MY20_Hev_Tx" SG_ 1046 DrvSlipCtlLamp_D_Rq 1;
BA_ "U_CX482_CX483_MY20_Gas_Tx" SG_ 1046 DrvSlipCtlLamp_D_Rq 1;
BA_ "U_CX482_CX483_MY20_Diesel_Tx" SG_ 1046 DrvSlipCtlLamp_D_Rq 1;
BA_ "U_U611_U625_MY20_Hev_Tx" SG_ 1046 DrvSlipCtlLamp_D_Rq 1;
BA_ "U_U611_U625_MY20_Gas_Tx" SG_ 1046 DrvSlipCtlLamp_D_Rq 1;
BA_ "U_U611_U625_MY20_Diesel_Tx" SG_ 1046 DrvSlipCtlLamp_D_Rq 1;
BA_ "U_B500_MY18_Diesel_Tx" SG_ 1046 DrvSlipCtlLamp_D_Rq 1;
BA_ "U_B500_MY18_Gas_Tx" SG_ 1046 DrvSlipCtlLamp_D_Rq 1;
BA_ "U_C490_MY18_Tx" SG_ 1046 DrvSlipCtlLamp_D_Rq 1;
BA_ "U_B562_MY18_Gas_Tx" SG_ 1046 DrvSlipCtlLamp_D_Rq 1;
BA_ "U_C519_MY18_5_Gas_Tx" SG_ 1046 DrvSlipCtlLamp_D_Rq 1;
BA_ "U_C519_MY18_5_Diesel_Tx" SG_ 1046 DrvSlipCtlLamp_D_Rq 1;
BA_ "U_B515_MCA_MY17_Gas_Tx" SG_ 1046 DrvSlipCtlLamp_D_Rq 1;
BA_ "U_B515_MCA_MY17_Diesel_Tx" SG_ 1046 DrvSlipCtlLamp_D_Rq 1;
BA_ "U_B479_MY17_Diesel_Tx" SG_ 1046 DrvSlipCtlLamp_D_Rq 1;
BA_ "U_B479_MY17_Gas_Tx" SG_ 1046 DrvSlipCtlLamp_D_Rq 1;
BA_ "U_B562LC_MY15_Gas_Tx" SG_ 1046 DrvSlipCtlLamp_D_Rq 1;
BA_ "U_B562LC_MY15_Diesel_Tx" SG_ 1046 DrvSlipCtlLamp_D_Rq 1;
BA_ "U_U611_U625_MY20_Phev_Rx" SG_ 1046 DrvSlipCtlLamp_D_Rq 1;
BA_ "U_CX482_CX483_MY20_Hev_Rx" SG_ 1046 DrvSlipCtlLamp_D_Rq 1;
BA_ "U_CX482_CX483_MY20_Gas_Rx" SG_ 1046 DrvSlipCtlLamp_D_Rq 1;
BA_ "U_CX482_CX483_MY20_Diesel_Rx" SG_ 1046 DrvSlipCtlLamp_D_Rq 1;
BA_ "U_U611_U625_MY20_Hev_Rx" SG_ 1046 DrvSlipCtlLamp_D_Rq 1;
BA_ "U_U611_U625_MY20_Gas_Rx" SG_ 1046 DrvSlipCtlLamp_D_Rq 1;
BA_ "U_U611_U625_MY20_Diesel_Rx" SG_ 1046 DrvSlipCtlLamp_D_Rq 1;
BA_ "U_B500_MY18_Diesel_Rx" SG_ 1046 DrvSlipCtlLamp_D_Rq 1;
BA_ "U_B500_MY18_Gas_Rx" SG_ 1046 DrvSlipCtlLamp_D_Rq 1;
BA_ "U_C490_MY18_Rx" SG_ 1046 DrvSlipCtlLamp_D_Rq 1;
BA_ "U_B562_MY18_Gas_Rx" SG_ 1046 DrvSlipCtlLamp_D_Rq 1;
BA_ "U_C519_MY18_5_Gas_Rx" SG_ 1046 DrvSlipCtlLamp_D_Rq 1;
BA_ "U_C519_MY18_5_Diesel_Rx" SG_ 1046 DrvSlipCtlLamp_D_Rq 1;
BA_ "U_B515_MCA_MY17_Gas_Rx" SG_ 1046 DrvSlipCtlLamp_D_Rq 1;
BA_ "U_B515_MCA_MY17_Diesel_Rx" SG_ 1046 DrvSlipCtlLamp_D_Rq 1;
BA_ "U_B479_MY17_Diesel_Rx" SG_ 1046 DrvSlipCtlLamp_D_Rq 1;
BA_ "U_B479_MY17_Gas_Rx" SG_ 1046 DrvSlipCtlLamp_D_Rq 1;
BA_ "CrossOver_InfoCAN" SG_ 1046 DrvSlipCtlLamp_D_Rq 1;
BA_ "U_CX482_CX483_MY20_Hev_Tx" SG_ 1046 Abs_B_Falt 1;
BA_ "U_CX482_CX483_MY20_Gas_Tx" SG_ 1046 Abs_B_Falt 1;
BA_ "U_CX482_CX483_MY20_Diesel_Tx" SG_ 1046 Abs_B_Falt 1;
BA_ "U_U611_U625_MY20_Hev_Tx" SG_ 1046 Abs_B_Falt 1;
BA_ "U_U611_U625_MY20_Gas_Tx" SG_ 1046 Abs_B_Falt 1;
BA_ "U_U611_U625_MY20_Diesel_Tx" SG_ 1046 Abs_B_Falt 1;
BA_ "U_B500_MY18_Diesel_Tx" SG_ 1046 Abs_B_Falt 1;
BA_ "U_B500_MY18_Gas_Tx" SG_ 1046 Abs_B_Falt 1;
BA_ "U_C490_MY18_Tx" SG_ 1046 Abs_B_Falt 1;
BA_ "U_B562_MY18_Gas_Tx" SG_ 1046 Abs_B_Falt 1;
BA_ "U_C519_MY18_5_Gas_Tx" SG_ 1046 Abs_B_Falt 1;
BA_ "U_C519_MY18_5_Diesel_Tx" SG_ 1046 Abs_B_Falt 1;
BA_ "U_B515_MCA_MY17_Gas_Tx" SG_ 1046 Abs_B_Falt 1;
BA_ "U_B515_MCA_MY17_Diesel_Tx" SG_ 1046 Abs_B_Falt 1;
BA_ "U_B479_MY17_Diesel_Tx" SG_ 1046 Abs_B_Falt 1;
BA_ "U_B479_MY17_Gas_Tx" SG_ 1046 Abs_B_Falt 1;
BA_ "U_B562LC_MY15_Gas_Tx" SG_ 1046 Abs_B_Falt 1;
BA_ "U_B562LC_MY15_Diesel_Tx" SG_ 1046 Abs_B_Falt 1;
BA_ "CrossOver_InfoCAN" SG_ 1046 Abs_B_Falt 1;
BA_ "U_CX482_CX483_MY20_Hev_Tx" SG_ 1046 DrvSlipCtlMde_D_Ind 1;
BA_ "U_CX482_CX483_MY20_Gas_Tx" SG_ 1046 DrvSlipCtlMde_D_Ind 1;
BA_ "U_CX482_CX483_MY20_Diesel_Tx" SG_ 1046 DrvSlipCtlMde_D_Ind 1;
BA_ "U_U611_U625_MY20_Hev_Tx" SG_ 1046 DrvSlipCtlMde_D_Ind 1;
BA_ "U_U611_U625_MY20_Gas_Tx" SG_ 1046 DrvSlipCtlMde_D_Ind 1;
BA_ "U_U611_U625_MY20_Diesel_Tx" SG_ 1046 DrvSlipCtlMde_D_Ind 1;
BA_ "U_B500_MY18_Diesel_Tx" SG_ 1046 DrvSlipCtlMde_D_Ind 1;
BA_ "U_B500_MY18_Gas_Tx" SG_ 1046 DrvSlipCtlMde_D_Ind 1;
BA_ "U_C490_MY18_Tx" SG_ 1046 DrvSlipCtlMde_D_Ind 1;
BA_ "U_B562_MY18_Gas_Tx" SG_ 1046 DrvSlipCtlMde_D_Ind 1;
BA_ "U_C519_MY18_5_Gas_Tx" SG_ 1046 DrvSlipCtlMde_D_Ind 1;
BA_ "U_C519_MY18_5_Diesel_Tx" SG_ 1046 DrvSlipCtlMde_D_Ind 1;
BA_ "U_B515_MCA_MY17_Gas_Tx" SG_ 1046 DrvSlipCtlMde_D_Ind 1;
BA_ "U_B515_MCA_MY17_Diesel_Tx" SG_ 1046 DrvSlipCtlMde_D_Ind 1;
BA_ "U_B479_MY17_Diesel_Tx" SG_ 1046 DrvSlipCtlMde_D_Ind 1;
BA_ "U_B479_MY17_Gas_Tx" SG_ 1046 DrvSlipCtlMde_D_Ind 1;
BA_ "U_B562LC_MY15_Gas_Tx" SG_ 1046 DrvSlipCtlMde_D_Ind 1;
BA_ "U_B562LC_MY15_Diesel_Tx" SG_ 1046 DrvSlipCtlMde_D_Ind 1;
BA_ "U_CX482_CX483_MY20_Hev_Rx" SG_ 1046 DrvSlipCtlMde_D_Ind 1;
BA_ "U_CX482_CX483_MY20_Gas_Rx" SG_ 1046 DrvSlipCtlMde_D_Ind 1;
BA_ "U_CX482_CX483_MY20_Diesel_Rx" SG_ 1046 DrvSlipCtlMde_D_Ind 1;
BA_ "U_U611_U625_MY20_Hev_Rx" SG_ 1046 DrvSlipCtlMde_D_Ind 1;
BA_ "U_U611_U625_MY20_Gas_Rx" SG_ 1046 DrvSlipCtlMde_D_Ind 1;
BA_ "U_U611_U625_MY20_Diesel_Rx" SG_ 1046 DrvSlipCtlMde_D_Ind 1;
BA_ "U_B500_MY18_Diesel_Rx" SG_ 1046 DrvSlipCtlMde_D_Ind 1;
BA_ "U_B500_MY18_Gas_Rx" SG_ 1046 DrvSlipCtlMde_D_Ind 1;
BA_ "U_C490_MY18_Rx" SG_ 1046 DrvSlipCtlMde_D_Ind 1;
BA_ "U_B562_MY18_Gas_Rx" SG_ 1046 DrvSlipCtlMde_D_Ind 1;
BA_ "U_C519_MY18_5_Gas_Rx" SG_ 1046 DrvSlipCtlMde_D_Ind 1;
BA_ "U_C519_MY18_5_Diesel_Rx" SG_ 1046 DrvSlipCtlMde_D_Ind 1;
BA_ "U_B515_MCA_MY17_Gas_Rx" SG_ 1046 DrvSlipCtlMde_D_Ind 1;
BA_ "U_B515_MCA_MY17_Diesel_Rx" SG_ 1046 DrvSlipCtlMde_D_Ind 1;
BA_ "CrossOver_InfoCAN" SG_ 1046 DrvSlipCtlMde_D_Ind 1;
BA_ "U_CX482_CX483_MY20_Hev_Tx" SG_ 1046 BpedMove_No_Cs 1;
BA_ "U_CX482_CX483_MY20_Gas_Tx" SG_ 1046 BpedMove_No_Cs 1;
BA_ "U_CX482_CX483_MY20_Diesel_Tx" SG_ 1046 BpedMove_No_Cs 1;
BA_ "U_U611_U625_MY20_Hev_Tx" SG_ 1046 BpedMove_No_Cs 1;
BA_ "U_U611_U625_MY20_Gas_Tx" SG_ 1046 BpedMove_No_Cs 1;
BA_ "U_U611_U625_MY20_Diesel_Tx" SG_ 1046 BpedMove_No_Cs 1;
BA_ "U_C519_MY18_5_Gas_Tx" SG_ 1046 BpedMove_No_Cs 1;
BA_ "U_C519_MY18_5_Diesel_Tx" SG_ 1046 BpedMove_No_Cs 1;
BA_ "U_B515_MCA_MY17_Gas_Tx" SG_ 1046 BpedMove_No_Cs 1;
BA_ "U_B515_MCA_MY17_Diesel_Tx" SG_ 1046 BpedMove_No_Cs 1;
BA_ "U_B479_MY17_Diesel_Tx" SG_ 1046 BpedMove_No_Cs 1;
BA_ "U_B479_MY17_Gas_Tx" SG_ 1046 BpedMove_No_Cs 1;
BA_ "U_B562LC_MY15_Gas_Tx" SG_ 1046 BpedMove_No_Cs 1;
BA_ "U_B562LC_MY15_Diesel_Tx" SG_ 1046 BpedMove_No_Cs 1;
BA_ "CrossOver_InfoCAN" SG_ 1046 BpedMove_No_Cs 1;
BA_ "U_CX482_CX483_MY20_Hev_Tx" SG_ 1046 DrvAntiLckLamp_D_Rq 1;
BA_ "U_CX482_CX483_MY20_Gas_Tx" SG_ 1046 DrvAntiLckLamp_D_Rq 1;
BA_ "U_CX482_CX483_MY20_Diesel_Tx" SG_ 1046 DrvAntiLckLamp_D_Rq 1;
BA_ "U_U611_U625_MY20_Hev_Tx" SG_ 1046 DrvAntiLckLamp_D_Rq 1;
BA_ "U_U611_U625_MY20_Gas_Tx" SG_ 1046 DrvAntiLckLamp_D_Rq 1;
BA_ "U_U611_U625_MY20_Diesel_Tx" SG_ 1046 DrvAntiLckLamp_D_Rq 1;
BA_ "U_B500_MY18_Diesel_Tx" SG_ 1046 DrvAntiLckLamp_D_Rq 1;
BA_ "U_B500_MY18_Gas_Tx" SG_ 1046 DrvAntiLckLamp_D_Rq 1;
BA_ "U_C490_MY18_Tx" SG_ 1046 DrvAntiLckLamp_D_Rq 1;
BA_ "U_B562_MY18_Gas_Tx" SG_ 1046 DrvAntiLckLamp_D_Rq 1;
BA_ "U_C519_MY18_5_Gas_Tx" SG_ 1046 DrvAntiLckLamp_D_Rq 1;
BA_ "U_C519_MY18_5_Diesel_Tx" SG_ 1046 DrvAntiLckLamp_D_Rq 1;
BA_ "U_B515_MCA_MY17_Gas_Tx" SG_ 1046 DrvAntiLckLamp_D_Rq 1;
BA_ "U_B515_MCA_MY17_Diesel_Tx" SG_ 1046 DrvAntiLckLamp_D_Rq 1;
BA_ "U_B479_MY17_Diesel_Tx" SG_ 1046 DrvAntiLckLamp_D_Rq 1;
BA_ "U_B479_MY17_Gas_Tx" SG_ 1046 DrvAntiLckLamp_D_Rq 1;
BA_ "U_B562LC_MY15_Gas_Tx" SG_ 1046 DrvAntiLckLamp_D_Rq 1;
BA_ "U_B562LC_MY15_Diesel_Tx" SG_ 1046 DrvAntiLckLamp_D_Rq 1;
BA_ "U_CX482_CX483_MY20_Hev_Rx" SG_ 1046 DrvAntiLckLamp_D_Rq 1;
BA_ "U_CX482_CX483_MY20_Gas_Rx" SG_ 1046 DrvAntiLckLamp_D_Rq 1;
BA_ "U_CX482_CX483_MY20_Diesel_Rx" SG_ 1046 DrvAntiLckLamp_D_Rq 1;
BA_ "U_U611_U625_MY20_Hev_Rx" SG_ 1046 DrvAntiLckLamp_D_Rq 1;
BA_ "U_U611_U625_MY20_Gas_Rx" SG_ 1046 DrvAntiLckLamp_D_Rq 1;
BA_ "U_U611_U625_MY20_Diesel_Rx" SG_ 1046 DrvAntiLckLamp_D_Rq 1;
BA_ "U_B500_MY18_Diesel_Rx" SG_ 1046 DrvAntiLckLamp_D_Rq 1;
BA_ "U_B500_MY18_Gas_Rx" SG_ 1046 DrvAntiLckLamp_D_Rq 1;
BA_ "U_C490_MY18_Rx" SG_ 1046 DrvAntiLckLamp_D_Rq 1;
BA_ "U_B562_MY18_Gas_Rx" SG_ 1046 DrvAntiLckLamp_D_Rq 1;
BA_ "U_C519_MY18_5_Gas_Rx" SG_ 1046 DrvAntiLckLamp_D_Rq 1;
BA_ "U_C519_MY18_5_Diesel_Rx" SG_ 1046 DrvAntiLckLamp_D_Rq 1;
BA_ "U_B515_MCA_MY17_Gas_Rx" SG_ 1046 DrvAntiLckLamp_D_Rq 1;
BA_ "U_B515_MCA_MY17_Diesel_Rx" SG_ 1046 DrvAntiLckLamp_D_Rq 1;
BA_ "U_B479_MY17_Diesel_Rx" SG_ 1046 DrvAntiLckLamp_D_Rq 1;
BA_ "U_B479_MY17_Gas_Rx" SG_ 1046 DrvAntiLckLamp_D_Rq 1;
BA_ "CrossOver_InfoCAN" SG_ 1046 DrvAntiLckLamp_D_Rq 1;
BA_ "U_CX482_CX483_MY20_Hev_Tx" SG_ 1046 BpedMove_No_Cnt 1;
BA_ "U_CX482_CX483_MY20_Gas_Tx" SG_ 1046 BpedMove_No_Cnt 1;
BA_ "U_CX482_CX483_MY20_Diesel_Tx" SG_ 1046 BpedMove_No_Cnt 1;
BA_ "U_U611_U625_MY20_Hev_Tx" SG_ 1046 BpedMove_No_Cnt 1;
BA_ "U_U611_U625_MY20_Gas_Tx" SG_ 1046 BpedMove_No_Cnt 1;
BA_ "U_U611_U625_MY20_Diesel_Tx" SG_ 1046 BpedMove_No_Cnt 1;
BA_ "U_C519_MY18_5_Gas_Tx" SG_ 1046 BpedMove_No_Cnt 1;
BA_ "U_C519_MY18_5_Diesel_Tx" SG_ 1046 BpedMove_No_Cnt 1;
BA_ "U_B515_MCA_MY17_Gas_Tx" SG_ 1046 BpedMove_No_Cnt 1;
BA_ "U_B515_MCA_MY17_Diesel_Tx" SG_ 1046 BpedMove_No_Cnt 1;
BA_ "U_B479_MY17_Diesel_Tx" SG_ 1046 BpedMove_No_Cnt 1;
BA_ "U_B479_MY17_Gas_Tx" SG_ 1046 BpedMove_No_Cnt 1;
BA_ "U_B562LC_MY15_Gas_Tx" SG_ 1046 BpedMove_No_Cnt 1;
BA_ "U_B562LC_MY15_Diesel_Tx" SG_ 1046 BpedMove_No_Cnt 1;
BA_ "CrossOver_InfoCAN" SG_ 1046 BpedMove_No_Cnt 1;
BA_ "U_CX482_CX483_MY20_Hev_Tx" SG_ 1046 StabCtlBrk_B_Avail 1;
BA_ "U_CX482_CX483_MY20_Gas_Tx" SG_ 1046 StabCtlBrk_B_Avail 1;
BA_ "U_CX482_CX483_MY20_Diesel_Tx" SG_ 1046 StabCtlBrk_B_Avail 1;
BA_ "U_U611_U625_MY20_Hev_Tx" SG_ 1046 StabCtlBrk_B_Avail 1;
BA_ "U_U611_U625_MY20_Gas_Tx" SG_ 1046 StabCtlBrk_B_Avail 1;
BA_ "U_U611_U625_MY20_Diesel_Tx" SG_ 1046 StabCtlBrk_B_Avail 1;
BA_ "U_B500_MY18_Diesel_Tx" SG_ 1046 StabCtlBrk_B_Avail 1;
BA_ "U_B500_MY18_Gas_Tx" SG_ 1046 StabCtlBrk_B_Avail 1;
BA_ "U_C490_MY18_Tx" SG_ 1046 StabCtlBrk_B_Avail 1;
BA_ "U_B562_MY18_Gas_Tx" SG_ 1046 StabCtlBrk_B_Avail 1;
BA_ "U_C519_MY18_5_Gas_Tx" SG_ 1046 StabCtlBrk_B_Avail 1;
BA_ "U_C519_MY18_5_Diesel_Tx" SG_ 1046 StabCtlBrk_B_Avail 1;
BA_ "U_B515_MCA_MY17_Gas_Tx" SG_ 1046 StabCtlBrk_B_Avail 1;
BA_ "U_B515_MCA_MY17_Diesel_Tx" SG_ 1046 StabCtlBrk_B_Avail 1;
BA_ "U_B479_MY17_Diesel_Tx" SG_ 1046 StabCtlBrk_B_Avail 1;
BA_ "U_B479_MY17_Gas_Tx" SG_ 1046 StabCtlBrk_B_Avail 1;
BA_ "U_B562LC_MY15_Gas_Tx" SG_ 1046 StabCtlBrk_B_Avail 1;
BA_ "U_B562LC_MY15_Diesel_Tx" SG_ 1046 StabCtlBrk_B_Avail 1;
BA_ "U_U611_U625_MY20_Phev_Rx" SG_ 1046 StabCtlBrk_B_Avail 1;
BA_ "U_U611_U625_MY20_Hev_Rx" SG_ 1046 StabCtlBrk_B_Avail 1;
BA_ "U_U611_U625_MY20_Gas_Rx" SG_ 1046 StabCtlBrk_B_Avail 1;
BA_ "U_U611_U625_MY20_Diesel_Rx" SG_ 1046 StabCtlBrk_B_Avail 1;
BA_ "U_C519_MY18_5_Gas_Rx" SG_ 1046 StabCtlBrk_B_Avail 1;
BA_ "U_C519_MY18_5_Diesel_Rx" SG_ 1046 StabCtlBrk_B_Avail 1;
BA_ "GenSigStartValue" SG_ 1046 StabCtlBrk_B_Avail 1;
BA_ "CrossOver_InfoCAN" SG_ 1046 StabCtlBrk_B_Avail 1;
BA_ "U_U611_U625_MY20_Hev_Tx" SG_ 1046 DrvHdcWarnInfo_D_Rq 1;
BA_ "U_U611_U625_MY20_Gas_Tx" SG_ 1046 DrvHdcWarnInfo_D_Rq 1;
BA_ "U_U611_U625_MY20_Diesel_Tx" SG_ 1046 DrvHdcWarnInfo_D_Rq 1;
BA_ "CrossOver_InfoCAN" SG_ 1046 DrvHdcWarnInfo_D_Rq 1;
BA_ "U_U611_U625_MY20_Hev_Tx" SG_ 1046 DrvHdcMsg_D_Rq 1;
BA_ "U_U611_U625_MY20_Gas_Tx" SG_ 1046 DrvHdcMsg_D_Rq 1;
BA_ "U_U611_U625_MY20_Diesel_Tx" SG_ 1046 DrvHdcMsg_D_Rq 1;
BA_ "CrossOver_InfoCAN" SG_ 1046 DrvHdcMsg_D_Rq 1;
BA_ "U_U611_U625_MY20_Hev_Tx" SG_ 1046 DrvHdcLampInfo_D_Rq 1;
BA_ "U_U611_U625_MY20_Gas_Tx" SG_ 1046 DrvHdcLampInfo_D_Rq 1;
BA_ "U_U611_U625_MY20_Diesel_Tx" SG_ 1046 DrvHdcLampInfo_D_Rq 1;
BA_ "CrossOver_InfoCAN" SG_ 1046 DrvHdcLampInfo_D_Rq 1;
BA_ "U_CX482_CX483_MY20_Hev_Tx" SG_ 1046 BpedMove_D_Actl 1;
BA_ "U_CX482_CX483_MY20_Gas_Tx" SG_ 1046 BpedMove_D_Actl 1;
BA_ "U_CX482_CX483_MY20_Diesel_Tx" SG_ 1046 BpedMove_D_Actl 1;
BA_ "U_U611_U625_MY20_Hev_Tx" SG_ 1046 BpedMove_D_Actl 1;
BA_ "U_U611_U625_MY20_Gas_Tx" SG_ 1046 BpedMove_D_Actl 1;
BA_ "U_U611_U625_MY20_Diesel_Tx" SG_ 1046 BpedMove_D_Actl 1;
BA_ "U_C519_MY18_5_Gas_Tx" SG_ 1046 BpedMove_D_Actl 1;
BA_ "U_C519_MY18_5_Diesel_Tx" SG_ 1046 BpedMove_D_Actl 1;
BA_ "U_B515_MCA_MY17_Gas_Tx" SG_ 1046 BpedMove_D_Actl 1;
BA_ "U_B515_MCA_MY17_Diesel_Tx" SG_ 1046 BpedMove_D_Actl 1;
BA_ "U_B479_MY17_Diesel_Tx" SG_ 1046 BpedMove_D_Actl 1;
BA_ "U_B479_MY17_Gas_Tx" SG_ 1046 BpedMove_D_Actl 1;
BA_ "U_B562LC_MY15_Gas_Tx" SG_ 1046 BpedMove_D_Actl 1;
BA_ "U_B562LC_MY15_Diesel_Tx" SG_ 1046 BpedMove_D_Actl 1;
BA_ "U_C519_MY18_5_Gas_Rx" SG_ 1046 BpedMove_D_Actl 1;
BA_ "U_C519_MY18_5_Diesel_Rx" SG_ 1046 BpedMove_D_Actl 1;
BA_ "GenSigStartValue" SG_ 1046 BpedMove_D_Actl 3;
BA_ "CrossOver_InfoCAN" SG_ 1046 BpedMove_D_Actl 1;
BA_ "U_CX482_CX483_MY20_Hev_Tx" SG_ 1046 ChimeBrk_B_Rq 1;
BA_ "U_CX482_CX483_MY20_Gas_Tx" SG_ 1046 ChimeBrk_B_Rq 1;
BA_ "U_CX482_CX483_MY20_Diesel_Tx" SG_ 1046 ChimeBrk_B_Rq 1;
BA_ "U_U611_U625_MY20_Hev_Tx" SG_ 1046 ChimeBrk_B_Rq 1;
BA_ "U_U611_U625_MY20_Gas_Tx" SG_ 1046 ChimeBrk_B_Rq 1;
BA_ "U_U611_U625_MY20_Diesel_Tx" SG_ 1046 ChimeBrk_B_Rq 1;
BA_ "U_B500_MY18_Diesel_Tx" SG_ 1046 ChimeBrk_B_Rq 1;
BA_ "U_B500_MY18_Gas_Tx" SG_ 1046 ChimeBrk_B_Rq 1;
BA_ "U_C490_MY18_Tx" SG_ 1046 ChimeBrk_B_Rq 1;
BA_ "U_B562_MY18_Gas_Tx" SG_ 1046 ChimeBrk_B_Rq 1;
BA_ "U_C519_MY18_5_Gas_Tx" SG_ 1046 ChimeBrk_B_Rq 1;
BA_ "U_C519_MY18_5_Diesel_Tx" SG_ 1046 ChimeBrk_B_Rq 1;
BA_ "U_B515_MCA_MY17_Gas_Tx" SG_ 1046 ChimeBrk_B_Rq 1;
BA_ "U_B515_MCA_MY17_Diesel_Tx" SG_ 1046 ChimeBrk_B_Rq 1;
BA_ "U_B562LC_MY15_Gas_Tx" SG_ 1046 ChimeBrk_B_Rq 1;
BA_ "U_B562LC_MY15_Diesel_Tx" SG_ 1046 ChimeBrk_B_Rq 1;
BA_ "CrossOver_InfoCAN" SG_ 1046 ChimeBrk_B_Rq 1;
BA_ "U_CX482_CX483_MY20_Hev_Tx" SG_ 1046 BrkLamp_B_Rq 1;
BA_ "U_CX482_CX483_MY20_Gas_Tx" SG_ 1046 BrkLamp_B_Rq 1;
BA_ "U_CX482_CX483_MY20_Diesel_Tx" SG_ 1046 BrkLamp_B_Rq 1;
BA_ "U_U611_U625_MY20_Hev_Tx" SG_ 1046 BrkLamp_B_Rq 1;
BA_ "U_U611_U625_MY20_Gas_Tx" SG_ 1046 BrkLamp_B_Rq 1;
BA_ "U_U611_U625_MY20_Diesel_Tx" SG_ 1046 BrkLamp_B_Rq 1;
BA_ "U_B500_MY18_Diesel_Tx" SG_ 1046 BrkLamp_B_Rq 1;
BA_ "U_B500_MY18_Gas_Tx" SG_ 1046 BrkLamp_B_Rq 1;
BA_ "U_C490_MY18_Tx" SG_ 1046 BrkLamp_B_Rq 1;
BA_ "U_B562_MY18_Gas_Tx" SG_ 1046 BrkLamp_B_Rq 1;
BA_ "U_C519_MY18_5_Gas_Tx" SG_ 1046 BrkLamp_B_Rq 1;
BA_ "U_C519_MY18_5_Diesel_Tx" SG_ 1046 BrkLamp_B_Rq 1;
BA_ "U_B515_MCA_MY17_Gas_Tx" SG_ 1046 BrkLamp_B_Rq 1;
BA_ "U_B515_MCA_MY17_Diesel_Tx" SG_ 1046 BrkLamp_B_Rq 1;
BA_ "U_B479_MY17_Diesel_Tx" SG_ 1046 BrkLamp_B_Rq 1;
BA_ "U_B479_MY17_Gas_Tx" SG_ 1046 BrkLamp_B_Rq 1;
BA_ "U_B562LC_MY15_Gas_Tx" SG_ 1046 BrkLamp_B_Rq 1;
BA_ "U_B562LC_MY15_Diesel_Tx" SG_ 1046 BrkLamp_B_Rq 1;
BA_ "U_CX482_CX483_MY20_Hev_Rx" SG_ 1046 BrkLamp_B_Rq 1;
BA_ "U_CX482_CX483_MY20_Gas_Rx" SG_ 1046 BrkLamp_B_Rq 1;
BA_ "U_CX482_CX483_MY20_Diesel_Rx" SG_ 1046 BrkLamp_B_Rq 1;
BA_ "U_U611_U625_MY20_Hev_Rx" SG_ 1046 BrkLamp_B_Rq 1;
BA_ "U_U611_U625_MY20_Gas_Rx" SG_ 1046 BrkLamp_B_Rq 1;
BA_ "U_U611_U625_MY20_Diesel_Rx" SG_ 1046 BrkLamp_B_Rq 1;
BA_ "U_B500_MY18_Diesel_Rx" SG_ 1046 BrkLamp_B_Rq 1;
BA_ "U_B500_MY18_Gas_Rx" SG_ 1046 BrkLamp_B_Rq 1;
BA_ "U_C490_MY18_Rx" SG_ 1046 BrkLamp_B_Rq 1;
BA_ "U_B562_MY18_Gas_Rx" SG_ 1046 BrkLamp_B_Rq 1;
BA_ "U_C519_MY18_5_Gas_Rx" SG_ 1046 BrkLamp_B_Rq 1;
BA_ "U_C519_MY18_5_Diesel_Rx" SG_ 1046 BrkLamp_B_Rq 1;
BA_ "U_B515_MCA_MY17_Gas_Rx" SG_ 1046 BrkLamp_B_Rq 1;
BA_ "U_B515_MCA_MY17_Diesel_Rx" SG_ 1046 BrkLamp_B_Rq 1;
BA_ "U_B479_MY17_Diesel_Rx" SG_ 1046 BrkLamp_B_Rq 1;
BA_ "U_B479_MY17_Gas_Rx" SG_ 1046 BrkLamp_B_Rq 1;
BA_ "CrossOver_InfoCAN" SG_ 1046 BrkLamp_B_Rq 1;
BA_ "U_U611_U625_MY20_Hev_Tx" SG_ 1046 HILL_DESC_MC 1;
BA_ "U_U611_U625_MY20_Gas_Tx" SG_ 1046 HILL_DESC_MC 1;
BA_ "U_U611_U625_MY20_Diesel_Tx" SG_ 1046 HILL_DESC_MC 1;
BA_ "CrossOver_InfoCAN" SG_ 1046 HILL_DESC_MC 1;
BA_ "GenSigTimeoutTime_GWM" SG_ 534 BrkObdData_No_Actl 300;
BA_ "U_CX482_CX483_MY20_Hev_Tx" SG_ 534 BrkObdData_No_Actl 1;
BA_ "U_CX482_CX483_MY20_Gas_Tx" SG_ 534 BrkObdData_No_Actl 1;
BA_ "U_CX482_CX483_MY20_Diesel_Tx" SG_ 534 BrkObdData_No_Actl 1;
BA_ "U_B500_MY18_Diesel_Tx" SG_ 534 BrkObdData_No_Actl 1;
BA_ "U_B500_MY18_Gas_Tx" SG_ 534 BrkObdData_No_Actl 1;
BA_ "U_C490_MY18_Tx" SG_ 534 BrkObdData_No_Actl 1;
BA_ "U_B562_MY18_Gas_Tx" SG_ 534 BrkObdData_No_Actl 1;
BA_ "U_C519_MY18_5_Gas_Tx" SG_ 534 BrkObdData_No_Actl 1;
BA_ "U_C519_MY18_5_Diesel_Tx" SG_ 534 BrkObdData_No_Actl 1;
BA_ "U_B515_MCA_MY17_Gas_Tx" SG_ 534 BrkObdData_No_Actl 1;
BA_ "U_B515_MCA_MY17_Diesel_Tx" SG_ 534 BrkObdData_No_Actl 1;
BA_ "U_B479_MY17_Diesel_Tx" SG_ 534 BrkObdData_No_Actl 1;
BA_ "U_B479_MY17_Gas_Tx" SG_ 534 BrkObdData_No_Actl 1;
BA_ "ContentDependant" SG_ 534 BrkObdData_No_Actl 1;
BA_ "GenSigTimeoutTime_GWM" SG_ 534 BrkObdIndex_No_Actl 300;
BA_ "U_CX482_CX483_MY20_Hev_Tx" SG_ 534 BrkObdIndex_No_Actl 1;
BA_ "U_CX482_CX483_MY20_Gas_Tx" SG_ 534 BrkObdIndex_No_Actl 1;
BA_ "U_CX482_CX483_MY20_Diesel_Tx" SG_ 534 BrkObdIndex_No_Actl 1;
BA_ "U_B500_MY18_Diesel_Tx" SG_ 534 BrkObdIndex_No_Actl 1;
BA_ "U_B500_MY18_Gas_Tx" SG_ 534 BrkObdIndex_No_Actl 1;
BA_ "U_C490_MY18_Tx" SG_ 534 BrkObdIndex_No_Actl 1;
BA_ "U_B562_MY18_Gas_Tx" SG_ 534 BrkObdIndex_No_Actl 1;
BA_ "U_C519_MY18_5_Gas_Tx" SG_ 534 BrkObdIndex_No_Actl 1;
BA_ "U_C519_MY18_5_Diesel_Tx" SG_ 534 BrkObdIndex_No_Actl 1;
BA_ "U_B515_MCA_MY17_Gas_Tx" SG_ 534 BrkObdIndex_No_Actl 1;
BA_ "U_B515_MCA_MY17_Diesel_Tx" SG_ 534 BrkObdIndex_No_Actl 1;
BA_ "U_B479_MY17_Diesel_Tx" SG_ 534 BrkObdIndex_No_Actl 1;
BA_ "U_B479_MY17_Gas_Tx" SG_ 534 BrkObdIndex_No_Actl 1;
BA_ "ContentDependant" SG_ 534 BrkObdIndex_No_Actl 1;
BA_ "GenSigTimeoutTime_GWM" SG_ 534 WhlRotatRr_No_Cnt 300;
BA_ "U_CX482_CX483_MY20_Hev_Tx" SG_ 534 WhlRotatRr_No_Cnt 1;
BA_ "U_CX482_CX483_MY20_Gas_Tx" SG_ 534 WhlRotatRr_No_Cnt 1;
BA_ "U_CX482_CX483_MY20_Diesel_Tx" SG_ 534 WhlRotatRr_No_Cnt 1;
BA_ "U_U611_U625_MY20_Hev_Tx" SG_ 534 WhlRotatRr_No_Cnt 1;
BA_ "U_U611_U625_MY20_Gas_Tx" SG_ 534 WhlRotatRr_No_Cnt 1;
BA_ "U_U611_U625_MY20_Diesel_Tx" SG_ 534 WhlRotatRr_No_Cnt 1;
BA_ "U_B500_MY18_Diesel_Tx" SG_ 534 WhlRotatRr_No_Cnt 1;
BA_ "U_B500_MY18_Gas_Tx" SG_ 534 WhlRotatRr_No_Cnt 1;
BA_ "U_C490_MY18_Tx" SG_ 534 WhlRotatRr_No_Cnt 1;
BA_ "U_B562_MY18_Gas_Tx" SG_ 534 WhlRotatRr_No_Cnt 1;
BA_ "U_C519_MY18_5_Gas_Tx" SG_ 534 WhlRotatRr_No_Cnt 1;
BA_ "U_C519_MY18_5_Diesel_Tx" SG_ 534 WhlRotatRr_No_Cnt 1;
BA_ "U_B515_MCA_MY17_Gas_Tx" SG_ 534 WhlRotatRr_No_Cnt 1;
BA_ "U_B515_MCA_MY17_Diesel_Tx" SG_ 534 WhlRotatRr_No_Cnt 1;
BA_ "U_B479_MY17_Diesel_Tx" SG_ 534 WhlRotatRr_No_Cnt 1;
BA_ "U_B479_MY17_Gas_Tx" SG_ 534 WhlRotatRr_No_Cnt 1;
BA_ "U_B562LC_MY15_Gas_Tx" SG_ 534 WhlRotatRr_No_Cnt 1;
BA_ "U_B562LC_MY15_Diesel_Tx" SG_ 534 WhlRotatRr_No_Cnt 1;
BA_ "U_CX482_CX483_MY20_Hev_Rx" SG_ 534 WhlRotatRr_No_Cnt 1;
BA_ "U_CX482_CX483_MY20_Gas_Rx" SG_ 534 WhlRotatRr_No_Cnt 1;
BA_ "U_CX482_CX483_MY20_Diesel_Rx" SG_ 534 WhlRotatRr_No_Cnt 1;
BA_ "U_B500_MY18_Diesel_Rx" SG_ 534 WhlRotatRr_No_Cnt 1;
BA_ "U_B500_MY18_Gas_Rx" SG_ 534 WhlRotatRr_No_Cnt 1;
BA_ "U_C519_MY18_5_Gas_Rx" SG_ 534 WhlRotatRr_No_Cnt 1;
BA_ "U_C519_MY18_5_Diesel_Rx" SG_ 534 WhlRotatRr_No_Cnt 1;
BA_ "U_B479_MY17_Diesel_Rx" SG_ 534 WhlRotatRr_No_Cnt 1;
BA_ "U_B479_MY17_Gas_Rx" SG_ 534 WhlRotatRr_No_Cnt 1;
BA_ "CrossOver_InfoCAN" SG_ 534 WhlRotatRr_No_Cnt 1;
BA_ "GenSigTimeoutTime_GWM" SG_ 534 WhlDirRr_D_Actl 300;
BA_ "U_CX482_CX483_MY20_Hev_Tx" SG_ 534 WhlDirRr_D_Actl 1;
BA_ "U_CX482_CX483_MY20_Gas_Tx" SG_ 534 WhlDirRr_D_Actl 1;
BA_ "U_CX482_CX483_MY20_Diesel_Tx" SG_ 534 WhlDirRr_D_Actl 1;
BA_ "U_U611_U625_MY20_Hev_Tx" SG_ 534 WhlDirRr_D_Actl 1;
BA_ "U_U611_U625_MY20_Gas_Tx" SG_ 534 WhlDirRr_D_Actl 1;
BA_ "U_U611_U625_MY20_Diesel_Tx" SG_ 534 WhlDirRr_D_Actl 1;
BA_ "U_B500_MY18_Diesel_Tx" SG_ 534 WhlDirRr_D_Actl 1;
BA_ "U_B500_MY18_Gas_Tx" SG_ 534 WhlDirRr_D_Actl 1;
BA_ "U_C519_MY18_5_Gas_Tx" SG_ 534 WhlDirRr_D_Actl 1;
BA_ "U_C519_MY18_5_Diesel_Tx" SG_ 534 WhlDirRr_D_Actl 1;
BA_ "U_B515_MCA_MY17_Gas_Tx" SG_ 534 WhlDirRr_D_Actl 1;
BA_ "U_B515_MCA_MY17_Diesel_Tx" SG_ 534 WhlDirRr_D_Actl 1;
BA_ "U_B479_MY17_Diesel_Tx" SG_ 534 WhlDirRr_D_Actl 1;
BA_ "U_B479_MY17_Gas_Tx" SG_ 534 WhlDirRr_D_Actl 1;
BA_ "U_B562LC_MY15_Gas_Tx" SG_ 534 WhlDirRr_D_Actl 1;
BA_ "U_B562LC_MY15_Diesel_Tx" SG_ 534 WhlDirRr_D_Actl 1;
BA_ "U_U611_U625_MY20_Phev_Rx" SG_ 534 WhlDirRr_D_Actl 1;
BA_ "U_B500_MY18_Diesel_Rx" SG_ 534 WhlDirRr_D_Actl 1;
BA_ "U_B500_MY18_Gas_Rx" SG_ 534 WhlDirRr_D_Actl 1;
BA_ "U_CX482_CX483_MY20_Hev_Rx" SG_ 534 WhlDirRr_D_Actl 1;
BA_ "U_CX482_CX483_MY20_Gas_Rx" SG_ 534 WhlDirRr_D_Actl 1;
BA_ "U_CX482_CX483_MY20_Diesel_Rx" SG_ 534 WhlDirRr_D_Actl 1;
BA_ "U_U611_U625_MY20_Hev_Rx" SG_ 534 WhlDirRr_D_Actl 1;
BA_ "U_U611_U625_MY20_Gas_Rx" SG_ 534 WhlDirRr_D_Actl 1;
BA_ "U_U611_U625_MY20_Diesel_Rx" SG_ 534 WhlDirRr_D_Actl 1;
BA_ "U_C519_MY18_5_Gas_Rx" SG_ 534 WhlDirRr_D_Actl 1;
BA_ "U_C519_MY18_5_Diesel_Rx" SG_ 534 WhlDirRr_D_Actl 1;
BA_ "U_B479_MY17_Diesel_Rx" SG_ 534 WhlDirRr_D_Actl 1;
BA_ "U_B479_MY17_Gas_Rx" SG_ 534 WhlDirRr_D_Actl 1;
BA_ "CrossOver_InfoCAN" SG_ 534 WhlDirRr_D_Actl 1;
BA_ "GenSigTimeoutTime_GWM" SG_ 534 WhlDirRl_D_Actl 300;
BA_ "U_CX482_CX483_MY20_Hev_Tx" SG_ 534 WhlDirRl_D_Actl 1;
BA_ "U_CX482_CX483_MY20_Gas_Tx" SG_ 534 WhlDirRl_D_Actl 1;
BA_ "U_CX482_CX483_MY20_Diesel_Tx" SG_ 534 WhlDirRl_D_Actl 1;
BA_ "U_U611_U625_MY20_Hev_Tx" SG_ 534 WhlDirRl_D_Actl 1;
BA_ "U_U611_U625_MY20_Gas_Tx" SG_ 534 WhlDirRl_D_Actl 1;
BA_ "U_U611_U625_MY20_Diesel_Tx" SG_ 534 WhlDirRl_D_Actl 1;
BA_ "U_B500_MY18_Diesel_Tx" SG_ 534 WhlDirRl_D_Actl 1;
BA_ "U_B500_MY18_Gas_Tx" SG_ 534 WhlDirRl_D_Actl 1;
BA_ "U_C519_MY18_5_Gas_Tx" SG_ 534 WhlDirRl_D_Actl 1;
BA_ "U_C519_MY18_5_Diesel_Tx" SG_ 534 WhlDirRl_D_Actl 1;
BA_ "U_B515_MCA_MY17_Gas_Tx" SG_ 534 WhlDirRl_D_Actl 1;
BA_ "U_B515_MCA_MY17_Diesel_Tx" SG_ 534 WhlDirRl_D_Actl 1;
BA_ "U_B479_MY17_Diesel_Tx" SG_ 534 WhlDirRl_D_Actl 1;
BA_ "U_B479_MY17_Gas_Tx" SG_ 534 WhlDirRl_D_Actl 1;
BA_ "U_B562LC_MY15_Gas_Tx" SG_ 534 WhlDirRl_D_Actl 1;
BA_ "U_B562LC_MY15_Diesel_Tx" SG_ 534 WhlDirRl_D_Actl 1;
BA_ "U_U611_U625_MY20_Phev_Rx" SG_ 534 WhlDirRl_D_Actl 1;
BA_ "U_B500_MY18_Diesel_Rx" SG_ 534 WhlDirRl_D_Actl 1;
BA_ "U_B500_MY18_Gas_Rx" SG_ 534 WhlDirRl_D_Actl 1;
BA_ "U_CX482_CX483_MY20_Hev_Rx" SG_ 534 WhlDirRl_D_Actl 1;
BA_ "U_CX482_CX483_MY20_Gas_Rx" SG_ 534 WhlDirRl_D_Actl 1;
BA_ "U_CX482_CX483_MY20_Diesel_Rx" SG_ 534 WhlDirRl_D_Actl 1;
BA_ "U_U611_U625_MY20_Hev_Rx" SG_ 534 WhlDirRl_D_Actl 1;
BA_ "U_U611_U625_MY20_Gas_Rx" SG_ 534 WhlDirRl_D_Actl 1;
BA_ "U_U611_U625_MY20_Diesel_Rx" SG_ 534 WhlDirRl_D_Actl 1;
BA_ "U_C519_MY18_5_Gas_Rx" SG_ 534 WhlDirRl_D_Actl 1;
BA_ "U_C519_MY18_5_Diesel_Rx" SG_ 534 WhlDirRl_D_Actl 1;
BA_ "U_B479_MY17_Diesel_Rx" SG_ 534 WhlDirRl_D_Actl 1;
BA_ "U_B479_MY17_Gas_Rx" SG_ 534 WhlDirRl_D_Actl 1;
BA_ "CrossOver_InfoCAN" SG_ 534 WhlDirRl_D_Actl 1;
BA_ "GenSigTimeoutTime_GWM" SG_ 534 WhlDirFr_D_Actl 300;
BA_ "U_CX482_CX483_MY20_Hev_Tx" SG_ 534 WhlDirFr_D_Actl 1;
BA_ "U_CX482_CX483_MY20_Gas_Tx" SG_ 534 WhlDirFr_D_Actl 1;
BA_ "U_CX482_CX483_MY20_Diesel_Tx" SG_ 534 WhlDirFr_D_Actl 1;
BA_ "U_U611_U625_MY20_Hev_Tx" SG_ 534 WhlDirFr_D_Actl 1;
BA_ "U_U611_U625_MY20_Gas_Tx" SG_ 534 WhlDirFr_D_Actl 1;
BA_ "U_U611_U625_MY20_Diesel_Tx" SG_ 534 WhlDirFr_D_Actl 1;
BA_ "U_B500_MY18_Diesel_Tx" SG_ 534 WhlDirFr_D_Actl 1;
BA_ "U_B500_MY18_Gas_Tx" SG_ 534 WhlDirFr_D_Actl 1;
BA_ "U_C519_MY18_5_Gas_Tx" SG_ 534 WhlDirFr_D_Actl 1;
BA_ "U_C519_MY18_5_Diesel_Tx" SG_ 534 WhlDirFr_D_Actl 1;
BA_ "U_B515_MCA_MY17_Gas_Tx" SG_ 534 WhlDirFr_D_Actl 1;
BA_ "U_B515_MCA_MY17_Diesel_Tx" SG_ 534 WhlDirFr_D_Actl 1;
BA_ "U_B479_MY17_Diesel_Tx" SG_ 534 WhlDirFr_D_Actl 1;
BA_ "U_B479_MY17_Gas_Tx" SG_ 534 WhlDirFr_D_Actl 1;
BA_ "U_U611_U625_MY20_Phev_Rx" SG_ 534 WhlDirFr_D_Actl 1;
BA_ "U_CX482_CX483_MY20_Hev_Rx" SG_ 534 WhlDirFr_D_Actl 1;
BA_ "U_CX482_CX483_MY20_Gas_Rx" SG_ 534 WhlDirFr_D_Actl 1;
BA_ "U_CX482_CX483_MY20_Diesel_Rx" SG_ 534 WhlDirFr_D_Actl 1;
BA_ "U_U611_U625_MY20_Hev_Rx" SG_ 534 WhlDirFr_D_Actl 1;
BA_ "U_U611_U625_MY20_Gas_Rx" SG_ 534 WhlDirFr_D_Actl 1;
BA_ "U_U611_U625_MY20_Diesel_Rx" SG_ 534 WhlDirFr_D_Actl 1;
BA_ "U_B500_MY18_Diesel_Rx" SG_ 534 WhlDirFr_D_Actl 1;
BA_ "U_B500_MY18_Gas_Rx" SG_ 534 WhlDirFr_D_Actl 1;
BA_ "U_C519_MY18_5_Gas_Rx" SG_ 534 WhlDirFr_D_Actl 1;
BA_ "U_C519_MY18_5_Diesel_Rx" SG_ 534 WhlDirFr_D_Actl 1;
BA_ "U_B479_MY17_Diesel_Rx" SG_ 534 WhlDirFr_D_Actl 1;
BA_ "U_B479_MY17_Gas_Rx" SG_ 534 WhlDirFr_D_Actl 1;
BA_ "CrossOver_InfoCAN" SG_ 534 WhlDirFr_D_Actl 1;
BA_ "GenSigTimeoutTime_GWM" SG_ 534 WhlDirFl_D_Actl 300;
BA_ "U_CX482_CX483_MY20_Hev_Tx" SG_ 534 WhlDirFl_D_Actl 1;
BA_ "U_CX482_CX483_MY20_Gas_Tx" SG_ 534 WhlDirFl_D_Actl 1;
BA_ "U_CX482_CX483_MY20_Diesel_Tx" SG_ 534 WhlDirFl_D_Actl 1;
BA_ "U_U611_U625_MY20_Hev_Tx" SG_ 534 WhlDirFl_D_Actl 1;
BA_ "U_U611_U625_MY20_Gas_Tx" SG_ 534 WhlDirFl_D_Actl 1;
BA_ "U_U611_U625_MY20_Diesel_Tx" SG_ 534 WhlDirFl_D_Actl 1;
BA_ "U_B500_MY18_Diesel_Tx" SG_ 534 WhlDirFl_D_Actl 1;
BA_ "U_B500_MY18_Gas_Tx" SG_ 534 WhlDirFl_D_Actl 1;
BA_ "U_C519_MY18_5_Gas_Tx" SG_ 534 WhlDirFl_D_Actl 1;
BA_ "U_C519_MY18_5_Diesel_Tx" SG_ 534 WhlDirFl_D_Actl 1;
BA_ "U_B515_MCA_MY17_Gas_Tx" SG_ 534 WhlDirFl_D_Actl 1;
BA_ "U_B515_MCA_MY17_Diesel_Tx" SG_ 534 WhlDirFl_D_Actl 1;
BA_ "U_B479_MY17_Diesel_Tx" SG_ 534 WhlDirFl_D_Actl 1;
BA_ "U_B479_MY17_Gas_Tx" SG_ 534 WhlDirFl_D_Actl 1;
BA_ "U_U611_U625_MY20_Phev_Rx" SG_ 534 WhlDirFl_D_Actl 1;
BA_ "U_CX482_CX483_MY20_Hev_Rx" SG_ 534 WhlDirFl_D_Actl 1;
BA_ "U_CX482_CX483_MY20_Gas_Rx" SG_ 534 WhlDirFl_D_Actl 1;
BA_ "U_CX482_CX483_MY20_Diesel_Rx" SG_ 534 WhlDirFl_D_Actl 1;
BA_ "U_U611_U625_MY20_Hev_Rx" SG_ 534 WhlDirFl_D_Actl 1;
BA_ "U_U611_U625_MY20_Gas_Rx" SG_ 534 WhlDirFl_D_Actl 1;
BA_ "U_U611_U625_MY20_Diesel_Rx" SG_ 534 WhlDirFl_D_Actl 1;
BA_ "U_B500_MY18_Diesel_Rx" SG_ 534 WhlDirFl_D_Actl 1;
BA_ "U_B500_MY18_Gas_Rx" SG_ 534 WhlDirFl_D_Actl 1;
BA_ "U_C519_MY18_5_Gas_Rx" SG_ 534 WhlDirFl_D_Actl 1;
BA_ "U_C519_MY18_5_Diesel_Rx" SG_ 534 WhlDirFl_D_Actl 1;
BA_ "U_B479_MY17_Diesel_Rx" SG_ 534 WhlDirFl_D_Actl 1;
BA_ "U_B479_MY17_Gas_Rx" SG_ 534 WhlDirFl_D_Actl 1;
BA_ "CrossOver_InfoCAN" SG_ 534 WhlDirFl_D_Actl 1;
BA_ "GenSigTimeoutTime_GWM" SG_ 534 WhlRotatRl_No_Cnt 300;
BA_ "U_CX482_CX483_MY20_Hev_Tx" SG_ 534 WhlRotatRl_No_Cnt 1;
BA_ "U_CX482_CX483_MY20_Gas_Tx" SG_ 534 WhlRotatRl_No_Cnt 1;
BA_ "U_CX482_CX483_MY20_Diesel_Tx" SG_ 534 WhlRotatRl_No_Cnt 1;
BA_ "U_U611_U625_MY20_Hev_Tx" SG_ 534 WhlRotatRl_No_Cnt 1;
BA_ "U_U611_U625_MY20_Gas_Tx" SG_ 534 WhlRotatRl_No_Cnt 1;
BA_ "U_U611_U625_MY20_Diesel_Tx" SG_ 534 WhlRotatRl_No_Cnt 1;
BA_ "U_B500_MY18_Diesel_Tx" SG_ 534 WhlRotatRl_No_Cnt 1;
BA_ "U_B500_MY18_Gas_Tx" SG_ 534 WhlRotatRl_No_Cnt 1;
BA_ "U_C490_MY18_Tx" SG_ 534 WhlRotatRl_No_Cnt 1;
BA_ "U_B562_MY18_Gas_Tx" SG_ 534 WhlRotatRl_No_Cnt 1;
BA_ "U_C519_MY18_5_Gas_Tx" SG_ 534 WhlRotatRl_No_Cnt 1;
BA_ "U_C519_MY18_5_Diesel_Tx" SG_ 534 WhlRotatRl_No_Cnt 1;
BA_ "U_B515_MCA_MY17_Gas_Tx" SG_ 534 WhlRotatRl_No_Cnt 1;
BA_ "U_B515_MCA_MY17_Diesel_Tx" SG_ 534 WhlRotatRl_No_Cnt 1;
BA_ "U_B479_MY17_Diesel_Tx" SG_ 534 WhlRotatRl_No_Cnt 1;
BA_ "U_B479_MY17_Gas_Tx" SG_ 534 WhlRotatRl_No_Cnt 1;
BA_ "U_B562LC_MY15_Gas_Tx" SG_ 534 WhlRotatRl_No_Cnt 1;
BA_ "U_B562LC_MY15_Diesel_Tx" SG_ 534 WhlRotatRl_No_Cnt 1;
BA_ "U_CX482_CX483_MY20_Hev_Rx" SG_ 534 WhlRotatRl_No_Cnt 1;
BA_ "U_CX482_CX483_MY20_Gas_Rx" SG_ 534 WhlRotatRl_No_Cnt 1;
BA_ "U_CX482_CX483_MY20_Diesel_Rx" SG_ 534 WhlRotatRl_No_Cnt 1;
BA_ "U_B500_MY18_Diesel_Rx" SG_ 534 WhlRotatRl_No_Cnt 1;
BA_ "U_B500_MY18_Gas_Rx" SG_ 534 WhlRotatRl_No_Cnt 1;
BA_ "U_C519_MY18_5_Gas_Rx" SG_ 534 WhlRotatRl_No_Cnt 1;
BA_ "U_C519_MY18_5_Diesel_Rx" SG_ 534 WhlRotatRl_No_Cnt 1;
BA_ "U_B479_MY17_Diesel_Rx" SG_ 534 WhlRotatRl_No_Cnt 1;
BA_ "U_B479_MY17_Gas_Rx" SG_ 534 WhlRotatRl_No_Cnt 1;
BA_ "CrossOver_InfoCAN" SG_ 534 WhlRotatRl_No_Cnt 1;
BA_ "GenSigTimeoutTime_GWM" SG_ 534 WhlRotatFr_No_Cnt 300;
BA_ "U_CX482_CX483_MY20_Hev_Tx" SG_ 534 WhlRotatFr_No_Cnt 1;
BA_ "U_CX482_CX483_MY20_Gas_Tx" SG_ 534 WhlRotatFr_No_Cnt 1;
BA_ "U_CX482_CX483_MY20_Diesel_Tx" SG_ 534 WhlRotatFr_No_Cnt 1;
BA_ "U_U611_U625_MY20_Hev_Tx" SG_ 534 WhlRotatFr_No_Cnt 1;
BA_ "U_U611_U625_MY20_Gas_Tx" SG_ 534 WhlRotatFr_No_Cnt 1;
BA_ "U_U611_U625_MY20_Diesel_Tx" SG_ 534 WhlRotatFr_No_Cnt 1;
BA_ "U_B500_MY18_Diesel_Tx" SG_ 534 WhlRotatFr_No_Cnt 1;
BA_ "U_B500_MY18_Gas_Tx" SG_ 534 WhlRotatFr_No_Cnt 1;
BA_ "U_C490_MY18_Tx" SG_ 534 WhlRotatFr_No_Cnt 1;
BA_ "U_B562_MY18_Gas_Tx" SG_ 534 WhlRotatFr_No_Cnt 1;
BA_ "U_C519_MY18_5_Gas_Tx" SG_ 534 WhlRotatFr_No_Cnt 1;
BA_ "U_C519_MY18_5_Diesel_Tx" SG_ 534 WhlRotatFr_No_Cnt 1;
BA_ "U_B515_MCA_MY17_Gas_Tx" SG_ 534 WhlRotatFr_No_Cnt 1;
BA_ "U_B515_MCA_MY17_Diesel_Tx" SG_ 534 WhlRotatFr_No_Cnt 1;
BA_ "U_B479_MY17_Diesel_Tx" SG_ 534 WhlRotatFr_No_Cnt 1;
BA_ "U_B479_MY17_Gas_Tx" SG_ 534 WhlRotatFr_No_Cnt 1;
BA_ "U_B562LC_MY15_Gas_Tx" SG_ 534 WhlRotatFr_No_Cnt 1;
BA_ "U_B562LC_MY15_Diesel_Tx" SG_ 534 WhlRotatFr_No_Cnt 1;
BA_ "U_CX482_CX483_MY20_Hev_Rx" SG_ 534 WhlRotatFr_No_Cnt 1;
BA_ "U_CX482_CX483_MY20_Gas_Rx" SG_ 534 WhlRotatFr_No_Cnt 1;
BA_ "U_CX482_CX483_MY20_Diesel_Rx" SG_ 534 WhlRotatFr_No_Cnt 1;
BA_ "U_B500_MY18_Diesel_Rx" SG_ 534 WhlRotatFr_No_Cnt 1;
BA_ "U_B500_MY18_Gas_Rx" SG_ 534 WhlRotatFr_No_Cnt 1;
BA_ "U_C519_MY18_5_Gas_Rx" SG_ 534 WhlRotatFr_No_Cnt 1;
BA_ "U_C519_MY18_5_Diesel_Rx" SG_ 534 WhlRotatFr_No_Cnt 1;
BA_ "U_B479_MY17_Diesel_Rx" SG_ 534 WhlRotatFr_No_Cnt 1;
BA_ "U_B479_MY17_Gas_Rx" SG_ 534 WhlRotatFr_No_Cnt 1;
BA_ "CrossOver_InfoCAN" SG_ 534 WhlRotatFr_No_Cnt 1;
BA_ "GenSigTimeoutTime_GWM" SG_ 534 WhlRotatFl_No_Cnt 300;
BA_ "U_CX482_CX483_MY20_Hev_Tx" SG_ 534 WhlRotatFl_No_Cnt 1;
BA_ "U_CX482_CX483_MY20_Gas_Tx" SG_ 534 WhlRotatFl_No_Cnt 1;
BA_ "U_CX482_CX483_MY20_Diesel_Tx" SG_ 534 WhlRotatFl_No_Cnt 1;
BA_ "U_U611_U625_MY20_Hev_Tx" SG_ 534 WhlRotatFl_No_Cnt 1;
BA_ "U_U611_U625_MY20_Gas_Tx" SG_ 534 WhlRotatFl_No_Cnt 1;
BA_ "U_U611_U625_MY20_Diesel_Tx" SG_ 534 WhlRotatFl_No_Cnt 1;
BA_ "U_B500_MY18_Diesel_Tx" SG_ 534 WhlRotatFl_No_Cnt 1;
BA_ "U_B500_MY18_Gas_Tx" SG_ 534 WhlRotatFl_No_Cnt 1;
BA_ "U_C490_MY18_Tx" SG_ 534 WhlRotatFl_No_Cnt 1;
BA_ "U_B562_MY18_Gas_Tx" SG_ 534 WhlRotatFl_No_Cnt 1;
BA_ "U_C519_MY18_5_Gas_Tx" SG_ 534 WhlRotatFl_No_Cnt 1;
BA_ "U_C519_MY18_5_Diesel_Tx" SG_ 534 WhlRotatFl_No_Cnt 1;
BA_ "U_B515_MCA_MY17_Gas_Tx" SG_ 534 WhlRotatFl_No_Cnt 1;
BA_ "U_B515_MCA_MY17_Diesel_Tx" SG_ 534 WhlRotatFl_No_Cnt 1;
BA_ "U_B479_MY17_Diesel_Tx" SG_ 534 WhlRotatFl_No_Cnt 1;
BA_ "U_B479_MY17_Gas_Tx" SG_ 534 WhlRotatFl_No_Cnt 1;
BA_ "U_B562LC_MY15_Gas_Tx" SG_ 534 WhlRotatFl_No_Cnt 1;
BA_ "U_B562LC_MY15_Diesel_Tx" SG_ 534 WhlRotatFl_No_Cnt 1;
BA_ "U_CX482_CX483_MY20_Hev_Rx" SG_ 534 WhlRotatFl_No_Cnt 1;
BA_ "U_CX482_CX483_MY20_Gas_Rx" SG_ 534 WhlRotatFl_No_Cnt 1;
BA_ "U_CX482_CX483_MY20_Diesel_Rx" SG_ 534 WhlRotatFl_No_Cnt 1;
BA_ "U_B500_MY18_Diesel_Rx" SG_ 534 WhlRotatFl_No_Cnt 1;
BA_ "U_B500_MY18_Gas_Rx" SG_ 534 WhlRotatFl_No_Cnt 1;
BA_ "U_C519_MY18_5_Gas_Rx" SG_ 534 WhlRotatFl_No_Cnt 1;
BA_ "U_C519_MY18_5_Diesel_Rx" SG_ 534 WhlRotatFl_No_Cnt 1;
BA_ "U_B479_MY17_Diesel_Rx" SG_ 534 WhlRotatFl_No_Cnt 1;
BA_ "U_B479_MY17_Gas_Rx" SG_ 534 WhlRotatFl_No_Cnt 1;
BA_ "CrossOver_InfoCAN" SG_ 534 WhlRotatFl_No_Cnt 1;
VAL_ 947 ValetMode_D_Mem 1 "On" 0 "Off" ;
VAL_ 947 DrStatDrvErrCnt_B_Stat 1 "Yes" 0 "No" ;
VAL_ 947 Backlit_LED_Status 15 "Unused3" 14 "Unused2" 13 "Unused1" 12 "Night_12" 11 "Night_11" 10 "Night_10" 9 "Night_9" 8 "Night_8" 7 "Night_7" 6 "Night_6" 5 "Night_5" 4 "Night_4" 3 "Night_3" 2 "Night_2" 1 "Night_1" 0 "Off" ;
VAL_ 947 TurnLghtRight_D_Rq 3 "Seq" 2 "On" 1 "Off" 0 "Null" ;
VAL_ 947 TurnLghtRightOn_B_Stat 1 "On" 0 "Off" ;
VAL_ 947 TurnLghtLeftOn_B_Stat 1 "On" 0 "Off" ;
VAL_ 947 FogLghtRearOn_B_Stat 1 "On" 0 "Off" ;
VAL_ 947 FogLghtFrontOn_B_Stat 1 "On" 0 "Off" ;
VAL_ 947 TurnLghtLeft_D_Rq 3 "Seq" 2 "On" 1 "Off" 0 "Null" ;
VAL_ 947 IgnKeyType_D_Actl 15 "Invalid" 14 "Unknown" 3 "Key_Not_Prgrm_Read_Failure" 2 "Key_In_Ign_My_Key" 1 "Key_In_Ign_Standard_Key" 0 "Key_Read_In_Progress" ;
VAL_ 947 Parklamp_Status 3 "Invalid" 2 "Unknown" 1 "On" 0 "Off" ;
VAL_ 947 Litval 255 "Invalid" 254 "Unknown" 5 "Day" 4 "Twilight_4" 3 "Twilight_3" 2 "Twilight_2" 1 "Twilight_1" 0 "Night" ;
VAL_ 947 Key_In_Ignition_Stat 1 "In" 0 "Out" ;
VAL_ 947 Ignition_Status 0 "Unknown" 1 "Off" 15 "Invalid" 8 "Start" 4 "Run" 2 "Accessory" ;
VAL_ 947 Dimming_Lvl 255 "Invalid" 254 "Unknown" 18 "Day_6" 17 "Day_5" 16 "Day_4" 15 "Day_3" 14 "Day_2" 13 "Day_1" 12 "Night_12" 11 "Night_11" 10 "Night_10" 9 "Night_9" 8 "Night_8" 7 "Night_7" 6 "Night_6" 5 "Night_5" 4 "Night_4" 3 "Night_3" 2 "Night_2" 1 "Night_1" 0 "Off" ;
VAL_ 947 Day_Night_Status 3 "NotUsed" 2 "Night" 1 "Day" 0 "Null" ;
VAL_ 947 Remote_Start_Status 3 "Invalid" 2 "Unknown" 1 "Remote" 0 "Null" ;
VAL_ 947 DrStatTgate_B_Actl 1 "Ajar" 0 "Closed" ;
VAL_ 947 DrStatRr_B_Actl 1 "Ajar" 0 "Closed" ;
VAL_ 947 DrStatRl_B_Actl 1 "Ajar" 0 "Closed" ;
VAL_ 947 DrStatPsngr_B_Actl 1 "Ajar" 0 "Closed" ;
VAL_ 947 DrStatInnrTgate_B_Actl 1 "Ajar" 0 "Closed" ;
VAL_ 947 DrStatHood_B_Actl 1 "Ajar" 0 "Closed" ;
VAL_ 947 DrStatDrv_B_Actl 1 "Ajar" 0 "Closed" ;
VAL_ 947 PrkBrkActv_B_Actl 1 "Active" 0 "Inactive" ;
VAL_ 947 LifeCycMde_D_Actl 3 "Transport" 2 "NotUsed" 1 "Factory" 0 "Normal" ;
VAL_ 947 CrashEvnt_D_Stat 3 "Invalid" 2 "Fuel_Cutoff_Event" 1 "Deploy_Event" 0 "No_Event" ;
VAL_ 947 FuelPmpInhbt_B_Stat 1 "Inhibit" 0 "No_Inibit" ;
VAL_ 947 BodySrvcRqd_B_Rq 1 "Yes" 0 "No" ;
VAL_ 947 Delay_Accy 1 "On" 0 "Off" ;
VAL_ 131 HeadLghtHiCtrl_D_RqAhb 7 "NotUsed2" 6 "NotUsed1" 5 "Auto_HiBeam" 4 "Auto_LoBeam" 3 "Flash" 2 "Man_HiBeam" 1 "Man_LoBeam" 0 "Null" ;
VAL_ 131 AhbStat_B_Dsply 1 "On" 0 "Off" ;
VAL_ 131 WiprFrontSwtch_D_Stat 15 "NotUsed6" 14 "NotUsed5" 13 "NotUsed4" 12 "NotUsed3" 11 "NotUsed2" 10 "NotUsed1" 9 "PositionNotDetermined" 8 "High" 7 "Low" 6 "Position6" 5 "Position5" 4 "Position4" 3 "Position3" 2 "Position2" 1 "Position1" 0 "Off" ;
VAL_ 131 HeadLghtHiOn_B_StatAhb 1 "On" 0 "Off" ;
VAL_ 131 HeadLghtHiFlash_D_Actl 3 "NotUsed" 2 "High" 1 "Flash_to_Pass" 0 "Null" ;
VAL_ 131 TjaButtnOnOffPress 1 "Pressed" 0 "Not_Pressed" ;
VAL_ 131 AccButtnGapTogglePress 1 "Pressed" 0 "Not_Pressed" ;
VAL_ 131 HeadLghtHiFlash_D_Stat 3 "NotUsed" 2 "High" 1 "Flash_to_Pass" 0 "Null" ;
VAL_ 131 WiprFront_D_Stat 15 "NO_DATA_EXISTS" 14 "STALLED" 13 "RESERVED" 12 "AUTO_ADJUST" 11 "COURTESYWIPE" 10 "AUTO_HIGH" 9 "AUTO_LOW" 8 "WASH" 7 "MIST_FLICK" 6 "MAN_HIGH" 5 "MAN_LOW" 4 "MAN_INT_ON" 3 "MAN_INT_OFF" 2 "OFF_MOVING" 1 "AUTO_OFF" 0 "OFF" ;
VAL_ 131 TurnLghtSwtch_D_Stat 3 "Unused_Treat_As_Off" 2 "Right" 1 "Left" 0 "Off" ;
VAL_ 131 LghtAmb_D_Sns 7 "No_Data_Exists" 6 "Unused2" 5 "Unused1" 4 "Tunnel_Off" 3 "Tunnel_On" 2 "Twilight" 1 "Light" 0 "Dark" ;
VAL_ 131 AccButtnGapIncPress 1 "Button_Pressed" 0 "Button_Not_Pressed" ;
VAL_ 131 AccButtnGapDecPress 1 "Button_Pressed" 0 "Button_Not_Pressed" ;
VAL_ 131 AslButtnOnOffPress 1 "Button_Pressed" 0 "Button_Not_Pressed" ;
VAL_ 131 AslButtnOnOffCnclPress 1 "Button_Pressed" 0 "Button_Not_Pressed" ;
VAL_ 131 CcButtnOnPress 1 "Button_Pressed" 0 "Button_Not_Pressed" ;
VAL_ 131 CcButtnOnOffPress 1 "Button_Pressed" 0 "Button_Not_Pressed" ;
VAL_ 131 CcButtnOnOffCnclPress 1 "Button_Pressed" 0 "Button_Not_Pressed" ;
VAL_ 131 CcButtnOffPress 1 "Button_Pressed" 0 "Button_Not_Pressed" ;
VAL_ 131 CcAsllButtnResPress 1 "Button_Pressed" 0 "Button_Not_Pressed" ;
VAL_ 131 CcAslButtnSetPress 1 "Button_Pressed" 0 "Button_Not_Pressed" ;
VAL_ 131 CcAslButtnSetIncPress 1 "Button_Pressed" 0 "Button_Not_Pressed" ;
VAL_ 131 CcAslButtnSetDecPress 1 "Button_Pressed" 0 "Button_Not_Pressed" ;
VAL_ 131 CcAslButtnResIncPress 1 "Button_Pressed" 0 "Button_Not_Pressed" ;
VAL_ 131 CcAslButtnResDecPress 1 "Button_Pressed" 0 "Button_Not_Pressed" ;
VAL_ 131 CcAslButtnOnPress 1 "Button_Pressed" 0 "Button_Not_Pressed" ;
VAL_ 131 CcAslButtnOnOffCncl 1 "Button_Pressed" 0 "Button_Not_Pressed" ;
VAL_ 131 CcAslButtnOffCnclPress 1 "Button_Pressed" 0 "Button_Not_Pressed" ;
VAL_ 131 CcAslButtnIndxIncPress 1 "Button_Pressed" 0 "Button_Not_Pressed" ;
VAL_ 131 CcAslButtnIndxDecPress 1 "Button_Pressed" 0 "Button_Not_Pressed" ;
VAL_ 131 CcAslButtnDeny_B_Actl 1 "Yes" 0 "No" ;
VAL_ 131 CcAslButtnCnclResPress 1 "Button_Pressed" 0 "Button_Not_Pressed" ;
VAL_ 131 CcAslButtnCnclPress 1 "Button_Pressed" 0 "Button_Not_Pressed" ;
VAL_ 131 LaSwtchPos_D_Stat 3 "Fault" 2 "Unused" 1 "Pressed" 0 "Open" ;
VAL_ 992 MsgCntrPersIndex_D_Rq 7 "Unused_3" 6 "Unused_2" 5 "Unused_1" 4 "Vehicle" 3 "PERS_4" 2 "PERS_3" 1 "PERS_2" 0 "PERS_1" ;
VAL_ 992 MsgCntrDsplyOp_D_Rq 7 "Unused_2" 6 "Unused_1" 5 "Copy" 4 "Restore" 3 "Upload" 2 "Set" 1 "Query" 0 "Null" ;
VAL_ 970 LkaActvStats_D2_Req 7 "NotUsed" 6 "LkaIncrIntervRight" 5 "LkaSupprRight" 4 "LkaStandIntervRight" 3 "LkaSupprLeft" 2 "LkaStandIntervLeft" 1 "LkaIncrIntervLeft" 0 "LkaNoInterv" ;
VAL_ 970 LaRefAng_No_Req 4095 "Fault" ;
VAL_ 970 LaRampType_B_Req 1 "Quick" 0 "Smooth" ;
VAL_ 970 LaCurvature_No_Calc 4095 "Fault" ;
VAL_ 970 LdwActvStats_D_Req 7 "LDW_Suppress_Right_Left" 6 "Not_Used2" 5 "LDW_Suppress_Right" 4 "LDW_Warning_Right" 3 "LDW_Suppress_Left" 2 "LDW_Warning_Left" 1 "Not_Used1" 0 "LDW_Idle" ;
VAL_ 970 LdwActvIntns_D_Req 3 "High" 2 "Medium" 1 "Low" 0 "None" ;
VAL_ 129 SteWhlSwtchView_B_Stat 1 "Pressed" 0 "Not_Pressed" ;
VAL_ 129 SteWhlSwtchSet_B_Stat 1 "Pressed" 0 "Not_Pressed" ;
VAL_ 129 SteWhlSwtchPhon_B_Stat 1 "Pressed" 0 "Not_Pressed" ;
VAL_ 129 SteWhlSwtchNav_B_Stat 1 "Pressed" 0 "Not_Pressed" ;
VAL_ 129 SteWhlSwtchMed_B_Stat 1 "Pressed" 0 "Not_Pressed" ;
VAL_ 129 SteWhlSwtchIod_B_Stat 1 "Pressed" 0 "Not_Pressed" ;
VAL_ 129 SteWhlSwtchHud_B_Stat 1 "Pressed" 0 "Not_Pressed" ;
VAL_ 129 SteWhlSwtchBack_B_Stat 1 "Pressed" 0 "Not_Pressed" ;
VAL_ 129 SteWhlSwtchMenu_B_Stat 1 "Pressed" 0 "Not_Pressed" ;
VAL_ 129 SteEffortInc_B_RqDrv 1 "Pressed" 0 "Not_Pressed" ;
VAL_ 129 SelDrvMdeInc_B_RqDrv 1 "Pressed" 0 "Not_Pressed" ;
VAL_ 129 SelDrvMdeDec_B_RqDrv 1 "Pressed" 0 "Not_Pressed" ;
VAL_ 129 SuspDampInc_B_RqDrv 1 "Pressed" 0 "Not_Pressed" ;
VAL_ 129 SteWhlSwtchUp_B_Stat 1 "Pressed" 0 "Not_Pressed" ;
VAL_ 129 SteWhlSwtchRght_B_Stat 1 "Pressed" 0 "Not_Pressed" ;
VAL_ 129 SteWhlSwtchOk_B_Stat 1 "Pressed" 0 "Not_Pressed" ;
VAL_ 129 SteWhlSwtchLeft_B_Stat 1 "Pressed" 0 "Not_Pressed" ;
VAL_ 129 SteWhlSwtchDown_B_Stat 1 "Pressed" 0 "Not_Pressed" ;
VAL_ 1109 eCallConfirmation 7 "Unused_2" 6 "CallComplete_DTMF_Timeout" 5 "eCall_Configured_Off" 4 "Call_Unsuccessful" 3 "Call_Cancelled" 2 "Call_Completed" 1 "Call_In_Progress" 0 "Normal" ;
VAL_ 394 AccTrgDist2_D_Dsply 15 "DIST_ACTIVE_13_Farthest" 14 "DIST_ACTIVE_12" 13 "DIST_ACTIVE_11" 12 "DIST_ACTIVE_10" 11 "DIST_ACTIVE_9" 10 "DIST_ACTIVE_8" 9 "DIST_ACTIVE_7" 8 "DIST_ACTIVE_6" 7 "DIST_ACTIVE_5" 6 "DIST_ACTIVE_4" 5 "DIST_ACTIVE_3" 4 "DIST_ACTIVE_2" 3 "DIST_ACTIVE_1_Closest" 2 "DIST_ACTIVE_No_Target" 1 "DIST_STANDBY" 0 "DIST_OFF" ;
VAL_ 394 AccStopRes_B_Dsply 1 "Yes" 0 "No" ;
VAL_ 394 TjaWarn_D_Rq 7 "NotUsed_4" 6 "NotUsed_3" 5 "NotUsed_2" 4 "NotUsed_1" 3 "HardTakeOverLevel2" 2 "HardTakeOverLevel1" 1 "TrafficJamAssistCancel" 0 "NoWarning" ;
VAL_ 394 Tja_D_Stat 7 "NotUsed_1" 6 "ActiveWarningRight" 5 "ActiveWarningLeft" 4 "ActiveInterventionRight" 3 "ActiveInterventionLeft" 2 "Active" 1 "Standby" 0 "Off" ;
VAL_ 394 TjaMsgTxt_D_Dsply 7 "NotUsed_4" 6 "NotUsed_3" 5 "NotUsed_2" 4 "NotUsed_1" 3 "TurnOnAdaptCruiseControl" 2 "TrafficJamAssistSelected" 1 "TrafficJamAssistUnavailabl" 0 "NoMessage" ;
VAL_ 394 IaccLamp_D_Rq 3 "NotUsed_2" 2 "NotUsed_1" 1 "DisplayIaccIcon" 0 "DoNotDisplayIaccIcon" ;
VAL_ 394 AccMsgTxt_D2_Rq 15 "NotUsed_1" 14 "NCC_Enabled_Warning" 13 "IACC_TJA_Selected" 12 "ACC_TJA_Selected" 11 "IACC_Selected" 10 "Press_Brake_To_Hold" 9 "Only_Following_In_Low_Spd" 8 "TJA_Unavailable" 7 "Shift_Down" 6 "IACC_Unavailable" 5 "ACC_Selected" 4 "ACC_Overridden" 3 "Brake_Capacity_Warning" 2 "ACC_Cancelled" 1 "ACC_Unavailable" 0 "No_Text" ;
VAL_ 394 FcwDeny_B_Dsply 1 "Yes" 0 "No" ;
VAL_ 394 FdaWarn_B_Rq 1 "Yes" 0 "No" ;
VAL_ 394 FcwMemStat_B_Actl 1 "On" 0 "Off" ;
VAL_ 394 AccTGap_B_Dsply 1 "Yes" 0 "No" ;
VAL_ 394 CadsAlignIncplt_B_Actl 1 "Yes" 0 "No" ;
VAL_ 394 AccLowVMde_B_Dsply 1 "Yes" 0 "No" ;
VAL_ 394 AccFllwMde_B_Dsply 1 "Yes" 0 "No" ;
VAL_ 394 CadsRadrBlck_B_Actl 1 "Yes" 0 "No" ;
VAL_ 394 FdaStat_D_Dsply 7 "Undefined_3" 6 "Undefined_2" 5 "Undefined_1" 4 "Distance_Alert_Unavailable" 3 "DistanceAlertUnavail_Low" 2 "DistanceAlertUnavailActive" 1 "Distance_Alert_Available" 0 "Distance_Alert_Off" ;
VAL_ 394 FdaDeny_B_Dsply 1 "Yes" 0 "No" ;
VAL_ 394 CadsChime_B_Rq 1 "Yes" 0 "No" ;
VAL_ 394 CmbbPostEvnt_B_Dsply 1 "Yes" 0 "No" ;
VAL_ 394 FcwCmbbSrvcRqd_B_Rq 1 "Yes" 0 "No" ;
VAL_ 394 AccStopMde_B_Dsply 1 "Yes" 0 "No" ;
VAL_ 394 CadsCamraBlck_B_Actl 1 "Yes" 0 "No" ;
VAL_ 394 FcwMemSens_D_Actl 3 "FCW_Sensitivity_3" 2 "FCW_Sensitivity_2" 1 "FCW_Sensitivity_1" 0 "Not_Used" ;
VAL_ 394 FcwMemDfaltOn_B_Actl 1 "Default_On" 0 "Last_Setting" ;
VAL_ 394 AccSrvcRqd_B_Rq 1 "Yes" 0 "No" ;
VAL_ 394 FcwMsgTxt_D_Rq 7 "Undefined_3" 6 "Undefined_2" 5 "Low_Visibility" 4 "Unavailable_DueTo_LowSpeed" 3 "Available" 2 "Unavailable" 1 "Off" 0 "No_Text" ;
VAL_ 394 AccWarn_D_Dsply 3 "BrakeReleaseWarn_In_StopMd" 2 "Brake_Capacity_Warning" 1 "Cancel_Warning" 0 "No_Warning" ;
VAL_ 394 FcwVisblWarn_B_Rq 1 "On" 0 "Off" ;
VAL_ 394 FcwAudioWarn_B_Rq 1 "On" 0 "Off" ;
VAL_ 394 FcwMemAudioOn_B_Actl 1 "On" 0 "Off" ;
VAL_ 394 AccTGap_D_Dsply 7 "Undefined_2" 6 "Undefined_1" 5 "Time_Gap_5" 4 "Time_Gap_4" 3 "Time_Gap_3" 2 "Time_Gap_2" 1 "Time_Gap_1" 0 "Not_Used" ;
VAL_ 394 AccMemEnbl_B_RqDrv 1 "Adaptive_Cruise" 0 "Normal_Cruise" ;
VAL_ 394 FdaMem_B_Stat 1 "On" 0 "Off" ;
VAL_ 1046 PrkBrkDynmc_D_Allw 3 "NotUsed" 2 "EPB_ECD_NotPossible" 1 "EPB_ECD_Possible" 0 "Used_at_Start_Up" ;
VAL_ 1046 BrkPrkBrkDynmc_B_Actl 1 "Active" 0 "Inactive" ;
VAL_ 1046 HsaMde_D_Mem 3 "Undefined" 2 "Manual" 1 "Automatic" 0 "Off" ;
VAL_ 1046 BrkBstrVac_B_Rq 1 "Yes" 0 "No" ;
VAL_ 1046 HdcMde_D_Actl 7 "Fault" 6 "Temporarily_Unavailable" 5 "NotEnabled_WrongGearSel" 4 "NotEnabled_SpdLimitExceed" 3 "Active_Braking" 2 "Not_Active_Braking" 1 "Off" 0 "Undefined" ;
VAL_ 1046 RearDiffLck_Tq2_RqMx 4095 "Faulty" ;
VAL_ 1046 TRLR_SWAY_EVNT_IN_PROG 1 "Yes" 0 "No" ;
VAL_ 1046 TRLR_SWAY_CONFIG_STAT 1 "On" 0 "Off" ;
VAL_ 1046 TCMode 1 "Active" 0 "Inactive" ;
VAL_ 1046 DrvSlipCtlLamp_D_Rq 3 "Fast_Flash" 2 "Slow_Flash" 1 "On" 0 "Off" ;
VAL_ 1046 Abs_B_Falt 1 "Yes" 0 "No" ;
VAL_ 1046 DrvSlipCtlMde_D_Ind 3 "App_Specific_Off_Mode_3" 2 "App_Specific_Off_Mode_2" 1 "App_Specific_Off_Mode_1" 0 "Default_Mode" ;
VAL_ 1046 DrvAntiLckLamp_D_Rq 3 "Fast_Flash" 2 "Slow_Flash" 1 "On" 0 "Off" ;
VAL_ 1046 StabCtlBrk_B_Avail 1 "Yes" 0 "No" ;
VAL_ 1046 DrvHdcWarnInfo_D_Rq 3 "Undefined" 2 "Lamp_On_Continuously" 1 "Lamp_Flashing" 0 "Lamp_Off_Continuously" ;
VAL_ 1046 DrvHdcMsg_D_Rq 7 "Undefined" 6 "Speed_too_High" 5 "Temporarily_Unavailable" 4 "System_Fault" 3 "Select_Gear" 2 "Off" 1 "On" 0 "No_Message" ;
VAL_ 1046 DrvHdcLampInfo_D_Rq 3 "Fast_Flash" 2 "Slow_Flash" 1 "On" 0 "Off" ;
VAL_ 1046 BpedMove_D_Actl 3 "Unknown" 2 "DriverApplyingBrakePedal" 1 "NoAutonomousBrkPdlMovement" 0 "AutonomousBrkPedalMove" ;
VAL_ 1046 ChimeBrk_B_Rq 1 "Yes" 0 "No" ;
VAL_ 1046 BrkLamp_B_Rq 1 "Yes" 0 "No" ;
VAL_ 1046 HILL_DESC_MC 7 "Fault_Detected" 6 "Cooling_Down" 5 "Abort_Apply_Brakes" 4 "Active" 3 "Disabled" 2 "Enabled" 1 "Off_Road" 0 "Normal" ;
VAL_ 534 WhlDirRr_D_Actl 3 "Failed" 2 "Unknown" 1 "Backward" 0 "Forward" ;
VAL_ 534 WhlDirRl_D_Actl 3 "Failed" 2 "Unknown" 1 "Backward" 0 "Forward" ;
VAL_ 534 WhlDirFr_D_Actl 3 "Failed" 2 "Unknown" 1 "Backward" 0 "Forward" ;
VAL_ 534 WhlDirFl_D_Actl 3 "Failed" 2 "Unknown" 1 "Backward" 0 "Forward" ;
